VERSION "HNNBNNNYNNNNNNNNNNNNNNNNNNNNNNNNNNNNNNNNNN/4/%%%/4/'%**4NNN///"

NS_ :

BS_:

BU_: AWC BAP_Tester BMC_MLBevo BMS_MV BMS_NV CBC DCDC_800V_PAG DCDC_HV DCDC_HV_02 DCDC_IHEV FCU_MLBevo_FCEV Gateway Gateway_PAG Ladegeraet_2 Ladegeraet_Konzern LE1 LE2 LE_MLBevo Sub_Gateway TME

BO_ 2549874869 ISOx_FCU_Req: 8 Gateway
 SG_ ISOx_FCU_Req_Data : 0|64@1+ (1.0,0.0) [0.0|18446744073709551615] ""  FCU_MLBevo_FCEV

BO_ 2550005941 ISOx_FCU_Resp: 8 FCU_MLBevo_FCEV
 SG_ ISOx_FCU_Resp_Data : 0|64@1+ (1.0,0.0) [0.0|18446744073709551615] ""  Gateway

BO_ 2549874811 ISOx_Hybrid_01_Req: 8 Gateway
 SG_ ISOx_Hybrid_01_Req_Data : 0|64@1+ (1.0,0.0) [0.0|18446744073709551615] ""  BMC_MLBevo

BO_ 2550005883 ISOx_Hybrid_01_Resp: 8 BMC_MLBevo
 SG_ ISOx_Hybrid_01_Resp_Data : 0|64@1+ (1.0,0.0) [0.0|18446744073709551615] ""  Gateway,Gateway_PAG

BO_ 2549874886 ISOx_Ladegeraet_2_Req: 8 Gateway
 SG_ ISOx_Ladegeraet_2_Req_Data : 0|64@1+ (1,0) [0|18446744073709551615] "Unit_None"  Ladegeraet_2

BO_ 2550005958 ISOx_Ladegeraet_2_Resp: 8 Ladegeraet_2
 SG_ ISOx_Ladegeraet_2_Resp_Data : 0|64@1+ (1,0) [0|18446744073709551615] "Unit_None"  Gateway,Gateway_PAG

BO_ 2549874868 ISOx_TelemetrieSG_Req: 8 Gateway
 SG_ ISOx_TelemetrieSG_Req_Data : 0|64@1+ (1.0,0.0) [0.0|18446744073709551615] ""  Sub_Gateway

BO_ 2550005940 ISOx_TelemetrieSG_Resp: 8 Sub_Gateway
 SG_ ISOx_TelemetrieSG_Resp_Data : 0|64@1+ (1.0,0.0) [0.0|18446744073709551615] ""  Gateway,Gateway_PAG

BO_ 497 Kessy_11: 8 Gateway
 SG_ KY_IDG_in_Reichweite : 12|1@1+ (1.0,0.0) [0.0|1] ""  Vector__XXX
 SG_ KY_Auf_Taste : 13|1@1+ (1.0,0.0) [0.0|1] ""  FCU_MLBevo_FCEV,Ladegeraet_Konzern
 SG_ KY_HDF_Taste : 14|1@1+ (1.0,0.0) [0.0|1] ""  Vector__XXX
 SG_ KY_Panik_Taste : 15|1@1+ (1.0,0.0) [0.0|1] ""  Vector__XXX
 SG_ KY_Zu_Taste : 16|1@1+ (1.0,0.0) [0.0|1] ""  Ladegeraet_Konzern
 SG_ KY_FT_Entriegelung_Autorisiert : 17|1@1+ (1.0,0.0) [0.0|1] ""  FCU_MLBevo_FCEV
 SG_ KY_FT_Verriegelung_Autorisiert : 18|1@1+ (1.0,0.0) [0.0|1] ""  Vector__XXX
 SG_ KY_BT_Entriegelung_Autorisiert : 19|1@1+ (1.0,0.0) [0.0|1] ""  FCU_MLBevo_FCEV
 SG_ KY_BT_Verriegelung_Autorisiert : 20|1@1+ (1.0,0.0) [0.0|1] ""  Vector__XXX
 SG_ KY_HFS_Entriegelung_Autorisiert : 21|1@1+ (1.0,0.0) [0.0|1] ""  FCU_MLBevo_FCEV
 SG_ KY_HFS_Verriegelung_Autorisiert : 22|1@1+ (1.0,0.0) [0.0|1] ""  Vector__XXX
 SG_ KY_HBFS_Entriegelung_Autorisiert : 23|1@1+ (1.0,0.0) [0.0|1] ""  FCU_MLBevo_FCEV
 SG_ KY_HBFS_Verriegelung_Autorisiert : 24|1@1+ (1.0,0.0) [0.0|1] ""  Vector__XXX
 SG_ KY_Front_Entr_Autorisiert : 25|1@1+ (1.0,0.0) [0.0|1] ""  Vector__XXX
 SG_ KY_Front_Verr_Autorisiert : 26|1@1+ (1.0,0.0) [0.0|1] ""  Vector__XXX
 SG_ KY_HD_Entriegelung_Autorisiert : 27|1@1+ (1.0,0.0) [0.0|1] ""  FCU_MLBevo_FCEV
 SG_ KY_HD_Verriegelung_Autorisiert : 28|1@1+ (1.0,0.0) [0.0|1] ""  Vector__XXX
 SG_ KY_Bereich : 29|3@1+ (1.0,0.0) [0.0|7] ""  Vector__XXX
 SG_ KY_Position : 32|3@1+ (1.0,0.0) [0.0|7] ""  Vector__XXX
 SG_ KY_ZV_Signatur : 35|11@1+ (1,0) [0|2047] "Unit_None"  Vector__XXX
 SG_ Schluesselnr_Personalisierung : 46|4@1+ (1.0,0.0) [0.0|15] ""  Vector__XXX
 SG_ FFB_FDF_Taste : 50|1@1+ (1.0,0.0) [0.0|1] ""  Vector__XXX
 SG_ FFB_Joker_Taste : 51|1@1+ (1.0,0.0) [0.0|1] ""  Vector__XXX
 SG_ FFB_Park_Taste : 52|1@1+ (1.0,0.0) [0.0|1] ""  Vector__XXX
 SG_ FFB_Remotestart_Taste : 53|1@1+ (1.0,0.0) [0.0|1] ""  Vector__XXX
 SG_ FBS_Aktivierung_Pilot_Parken : 54|1@1+ (1.0,0.0) [0.0|1] ""  Vector__XXX
 SG_ KY_Schluessel_im_Fzg : 55|1@1+ (1.0,0.0) [0.0|1] ""  Vector__XXX
 SG_ KY_EasyClose_Abbruch : 56|1@1+ (1.0,0.0) [0.0|1] ""  Vector__XXX
 SG_ KY_EasyClose_Status : 57|3@1+ (1.0,0.0) [0.0|7] ""  Vector__XXX
 SG_ KY_HD_Auffahrt : 60|1@1+ (1.0,0.0) [0.0|1] ""  Vector__XXX
 SG_ KY_HD_Zufahrt : 61|1@1+ (1.0,0.0) [0.0|1] ""  Vector__XXX
 SG_ KY_LKL_1_Autorisierung : 62|1@1+ (1.0,0.0) [0.0|1] ""  Ladegeraet_Konzern
 SG_ KY_LKL_2_Autorisierung : 63|1@1+ (1.0,0.0) [0.0|1] ""  Ladegeraet_Konzern

BO_ 960 Klemmen_Status_01: 4 Gateway
 SG_ Klemmen_Status_01_CRC : 0|8@1+ (1,0) [0|255] ""  BMC_MLBevo,CBC,DCDC_HV_02,FCU_MLBevo_FCEV,Ladegeraet_2,Ladegeraet_Konzern
 SG_ Klemmen_Status_01_BZ : 8|4@1+ (1,0) [0|15] ""  BMC_MLBevo,CBC,DCDC_HV_02,FCU_MLBevo_FCEV,Ladegeraet_2,Ladegeraet_Konzern
 SG_ RSt_Fahrerhinweise : 12|4@1+ (1.0,0.0) [0.0|15] ""  FCU_MLBevo_FCEV
 SG_ ZAS_Kl_S : 16|1@1+ (1.0,0.0) [0.0|1] ""  FCU_MLBevo_FCEV,Ladegeraet_2,Ladegeraet_Konzern,TME
 SG_ ZAS_Kl_15 : 17|1@1+ (1.0,0.0) [0.0|1] ""  BMC_MLBevo,BMS_MV,BMS_NV,CBC,DCDC_800V_PAG,DCDC_HV,DCDC_HV_02,DCDC_IHEV,FCU_MLBevo_FCEV,Ladegeraet_2,Ladegeraet_Konzern,Sub_Gateway,TME
 SG_ ZAS_Kl_X : 18|1@1+ (1.0,0.0) [0.0|1] ""  FCU_MLBevo_FCEV
 SG_ ZAS_Kl_50_Startanforderung : 19|1@1+ (1.0,0.0) [0.0|1] ""  BMC_MLBevo,FCU_MLBevo_FCEV,Ladegeraet_2,Ladegeraet_Konzern,TME
 SG_ BCM_Remotestart_Betrieb : 20|1@1+ (1.0,0.0) [0.0|1] ""  FCU_MLBevo_FCEV
 SG_ ZAS_Kl_Infotainment : 21|1@1+ (1.0,0.0) [0.0|1] ""  FCU_MLBevo_FCEV
 SG_ BCM_Remotestart_KL15_Anf : 22|1@1+ (1.0,0.0) [0.0|1] ""  FCU_MLBevo_FCEV
 SG_ BCM_Remotestart_MO_Start : 23|1@1+ (1.0,0.0) [0.0|1] ""  FCU_MLBevo_FCEV
 SG_ KST_Warn_P1_ZST_def : 24|1@1+ (1.0,0.0) [0.0|1] ""  FCU_MLBevo_FCEV
 SG_ KST_Warn_P2_ZST_def : 25|1@1+ (1.0,0.0) [0.0|1] ""  FCU_MLBevo_FCEV
 SG_ KST_Fahrerhinweis_1 : 26|1@1+ (1.0,0.0) [0.0|1] ""  FCU_MLBevo_FCEV
 SG_ KST_Fahrerhinweis_2 : 27|1@1+ (1.0,0.0) [0.0|1] ""  FCU_MLBevo_FCEV
 SG_ BCM_Ausparken_Betrieb : 28|1@1+ (1.0,0.0) [0.0|1] ""  FCU_MLBevo_FCEV
 SG_ KST_Fahrerhinweis_4 : 29|1@1+ (1.0,0.0) [0.0|1] ""  FCU_MLBevo_FCEV
 SG_ KST_Fahrerhinweis_5 : 30|1@1+ (1.0,0.0) [0.0|1] ""  FCU_MLBevo_FCEV
 SG_ KST_Fahrerhinweis_6 : 31|1@1+ (1.0,0.0) [0.0|1] ""  FCU_MLBevo_FCEV

BO_ 1646 Klima_03: 8 Gateway
 SG_ KL_STL_aktiv : 0|1@1+ (1.0,0.0) [0.0|1] ""  Vector__XXX
 SG_ KL_STH_aktiv : 1|1@1+ (1.0,0.0) [0.0|1] ""  Vector__XXX
 SG_ KL_Solarluefter_aktiv : 2|1@1+ (1.0,0.0) [0.0|1] ""  Vector__XXX
 SG_ KL_Umluft_Taste : 3|1@1+ (1.0,0.0) [0.0|1] ""  TME
 SG_ KL_Geblaese_Fond_Status : 4|4@1+ (1.0,0.0) [0.0|15] ""  TME
 SG_ KL_STH_Ansteuerung : 8|2@1+ (1.0,0.0) [0.0|3] ""  Vector__XXX
 SG_ KL_STH_Betriebsdauer : 10|6@1+ (1,0) [0|60] "Unit_Minut"  Vector__XXX
 SG_ KL_Magnetventil : 16|1@1+ (1.0,0.0) [0.0|1] ""  Vector__XXX
 SG_ KL_WaPu : 17|1@1+ (1.0,0.0) [0.0|1] ""  Vector__XXX
 SG_ KL_Geblaese_Status : 18|4@1+ (1.0,0.0) [0.0|15] ""  TME
 SG_ KL_Restwaerme_aktiv : 22|1@1+ (1.0,0.0) [0.0|1] ""  Vector__XXX
 SG_ KL_Kompressorkupplung : 23|1@1+ (1.0,0.0) [0.0|1] ""  Vector__XXX
 SG_ KL_BCmE_Livetip_Freigabe : 24|1@1+ (1.0,0.0) [0.0|1] ""  TME
 SG_ KL_HYB_ASV_hinten_schliessen_Anf : 25|1@1+ (1.0,0.0) [0.0|1] ""  TME
 SG_ KL_HYB_ASV_vorne_schliessen_Anf : 26|1@1+ (1.0,0.0) [0.0|1] ""  TME
 SG_ KL_ErwVK_Zusatzrelais : 27|1@1+ (1.0,0.0) [0.0|1] ""  Vector__XXX
 SG_ KL_Status_Beduftung : 28|1@1+ (1.0,0.0) [0.0|1] ""  Vector__XXX
 SG_ KL_Status_Ionisator_Front : 29|1@1+ (1.0,0.0) [0.0|1] ""  Vector__XXX
 SG_ KL_STH_Timer_Status : 30|1@1+ (1.0,0.0) [0.0|1] ""  Vector__XXX
 SG_ KL_ErwVK_Anf : 31|1@1+ (1.0,0.0) [0.0|1] ""  TME
 SG_ KL_Innen_Temp : 32|8@1+ (0.5,-50) [-50.0|76.0] "Unit_DegreCelsi"  TME
 SG_ KL_I_Geblaese_Fond : 40|8@1+ (0.25,0) [0.00|63.50] "Unit_Amper"  Vector__XXX
 SG_ KL_Anf_AussenspiegelHzg : 48|1@1+ (1.0,0.0) [0.0|1] ""  Vector__XXX
 SG_ KL_Heizkreisventilstellung : 49|2@1+ (1.0,0.0) [0.0|3] ""  Vector__XXX
 SG_ KL_FSH_Automatikbetrieb : 51|1@1+ (1.0,0.0) [0.0|1] ""  Vector__XXX
 SG_ KL_SIH_LEH_Verteilung_VL : 52|3@1+ (1.0,0.0) [0.0|7] ""  Vector__XXX
 SG_ KL_SIH_LEL_Verteilung_VL : 55|3@1+ (1.0,0.0) [0.0|7] ""  Vector__XXX
 SG_ KL_SIH_LEH_Verteilung_VR : 58|3@1+ (1.0,0.0) [0.0|7] ""  Vector__XXX
 SG_ KL_SIH_LEL_Verteilung_VR : 61|3@1+ (1.0,0.0) [0.0|7] ""  Vector__XXX

BO_ 1649 Klima_06: 8 Gateway
 SG_ KL_ZZ_Minute : 0|6@1+ (1,0) [0|59] "Unit_Minut"  TME
 SG_ KL_ZZ_Status_Timer : 6|2@1+ (1.0,0.0) [0.0|3] ""  TME
 SG_ KL_ZZ_Monat : 8|4@1+ (1,0) [1|12] "Unit_Month"  TME
 SG_ KL_ZZ_Stunde : 16|5@1+ (1,0) [0|23] "Unit_Hours"  TME
 SG_ KL_ZZ_Betriebsmodus : 21|3@1+ (1.0,0.0) [0.0|7] ""  TME
 SG_ KL_ZZ_Tag : 24|5@1+ (1,0) [1|31] "Unit_Day"  TME
 SG_ KL_Betriebsmodus_FH : 29|3@1+ (1.0,0.0) [0.0|7] ""  Vector__XXX
 SG_ KL_Stopp_Wiederstart_Anz_01 : 32|1@1+ (1.0,0.0) [0.0|1] ""  Vector__XXX
 SG_ KL_Stopp_Wiederstart_Anz_02 : 33|1@1+ (1.0,0.0) [0.0|1] ""  Vector__XXX
 SG_ KL_Stopp_Wiederstart_Anz_03 : 34|1@1+ (1.0,0.0) [0.0|1] ""  Vector__XXX
 SG_ KL_Stopp_Wiederstart_Anz_04 : 35|1@1+ (1.0,0.0) [0.0|1] ""  Vector__XXX
 SG_ KL_Stopp_Wiederstart_Anz_05 : 36|1@1+ (1.0,0.0) [0.0|1] ""  Vector__XXX
 SG_ KL_Stopp_Wiederstart_Anz_06 : 37|1@1+ (1.0,0.0) [0.0|1] ""  Vector__XXX
 SG_ KL_Stopp_Wiederstart_Anz_07 : 38|1@1+ (1.0,0.0) [0.0|1] ""  Vector__XXX
 SG_ KL_Stopp_Wiederstart_Anz_08 : 39|1@1+ (1.0,0.0) [0.0|1] ""  Vector__XXX
 SG_ KL_Stopp_Wiederstart_Anz_09 : 40|1@1+ (1.0,0.0) [0.0|1] ""  Vector__XXX
 SG_ KL_Stopp_Wiederstart_Anz_Std1 : 41|1@1+ (1.0,0.0) [0.0|1] ""  Vector__XXX
 SG_ KL_Stopp_Wiederstart_Anz_Std2 : 42|1@1+ (1.0,0.0) [0.0|1] ""  Vector__XXX

BO_ 949 Klima_11: 8 Gateway
 SG_ KL_Drehz_Anh : 0|1@1+ (1.0,0.0) [0.0|1] ""  TME
 SG_ KL_Vorwarn_Komp_ein : 1|1@1+ (1.0,0.0) [0.0|1] ""  TME
 SG_ KL_AC_Schalter : 2|1@1+ (1.0,0.0) [0.0|1] ""  TME
 SG_ KL_Komp_Moment_alt : 3|1@1+ (1.0,0.0) [0.0|1] ""  TME
 SG_ KL_Vorwarn_Zuheizer_ein : 6|1@1+ (1.0,0.0) [0.0|1] ""  Vector__XXX
 SG_ KL_Zustand : 7|1@1+ (1.0,0.0) [0.0|1] ""  TME
 SG_ KL_Kompressorkupplung_linear : 8|8@1+ (20,0) [0|4000] "Unit_MilliAmper"  Vector__XXX
 SG_ KL_Charisma_FahrPr : 16|4@1+ (1.0,0.0) [0.0|15] ""  TME
 SG_ KL_Charisma_Status : 20|2@1+ (1.0,0.0) [0.0|3] ""  TME
 SG_ KL_nachtr_Stopp_Anf : 22|1@1+ (1.0,0.0) [0.0|1] ""  Vector__XXX
 SG_ KL_T_Charge : 23|1@1+ (1.0,0.0) [0.0|1] ""  Vector__XXX
 SG_ KL_Last_Kompr : 24|8@1+ (0.25,0) [0.00|63.50] "Unit_NewtoMeter"  TME
 SG_ KL_Spannungs_Anf : 32|2@1+ (1.0,0.0) [0.0|3] ""  Vector__XXX
 SG_ KL_Thermomanagement : 34|2@1+ (1.0,0.0) [0.0|3] ""  TME
 SG_ KL_StartStopp_Info : 36|2@1+ (1.0,0.0) [0.0|3] ""  TME
 SG_ KL_Freilauf_Info : 38|2@1+ (1.0,0.0) [0.0|3] ""  Vector__XXX
 SG_ KL_Anf_KL : 40|8@1+ (0.4,0) [0.0|101.6] "Unit_PerCent"  TME
 SG_ KL_el_Zuheizer_Stufe : 48|3@1+ (1.0,0.0) [0.0|7] ""  TME
 SG_ KL_Ausstattung_Klima : 51|3@1+ (1.0,0.0) [0.0|7] ""  Vector__XXX
 SG_ KL_Variante_Standheizung : 54|2@1+ (1.0,0.0) [0.0|3] ""  Vector__XXX

BO_ 1640 Klima_12: 8 Gateway
 SG_ KL_LRH_Taster : 0|1@1+ (1.0,0.0) [0.0|1] ""  Vector__XXX
 SG_ KL_LRH_Stufe : 1|2@1+ (1.0,0.0) [0.0|3] ""  Vector__XXX
 SG_ HSH_Taster : 3|2@1+ (1.0,0.0) [0.0|3] ""  Vector__XXX
 SG_ FSH_Taster : 5|1@1+ (1.0,0.0) [0.0|1] ""  Vector__XXX
 SG_ KL_Zuheizer_Freigabe : 6|1@1+ (1.0,0.0) [0.0|1] ""  TME
 SG_ KL_Beschlagsgefahr : 7|1@1+ (1.0,0.0) [0.0|1] ""  TME
 SG_ KL_SIH_Soll_li : 8|3@1+ (1,0) [0|6] ""  TME
 SG_ KL_SIH_Soll_re : 11|3@1+ (1,0) [0|6] ""  TME
 SG_ KRH_Soll_li : 14|2@1+ (1.0,0.0) [0.0|3] ""  Vector__XXX
 SG_ KL_SIL_Soll_li : 16|3@1+ (1,0) [0|6] ""  TME
 SG_ KL_SIL_Soll_re : 19|3@1+ (1,0) [0|6] ""  TME
 SG_ KRH_Soll_re : 22|2@1+ (1.0,0.0) [0.0|3] ""  Vector__XXX
 SG_ KL_Geblspng_Soll : 24|8@1+ (0.05,1.45) [1.50|14.00] "Unit_Volt"  Vector__XXX
 SG_ KL_Geblspng_Fond_Soll : 32|8@1+ (0.05,1.45) [1.50|14.00] "Unit_Volt"  Vector__XXX
 SG_ KL_I_Geblaese : 40|8@1+ (0.25,0) [0.00|63.50] "Unit_Amper"  Vector__XXX
 SG_ KL_Kompressorstrom_soll : 48|10@1+ (1,0) [0|1021] ""  TME
 SG_ KL_Umluftklappe_Status : 58|4@1+ (1.0,0.0) [0.0|15] ""  TME
 SG_ KL_PTC_Verbauinfo : 62|2@1+ (1.0,0.0) [0.0|3] ""  Vector__XXX

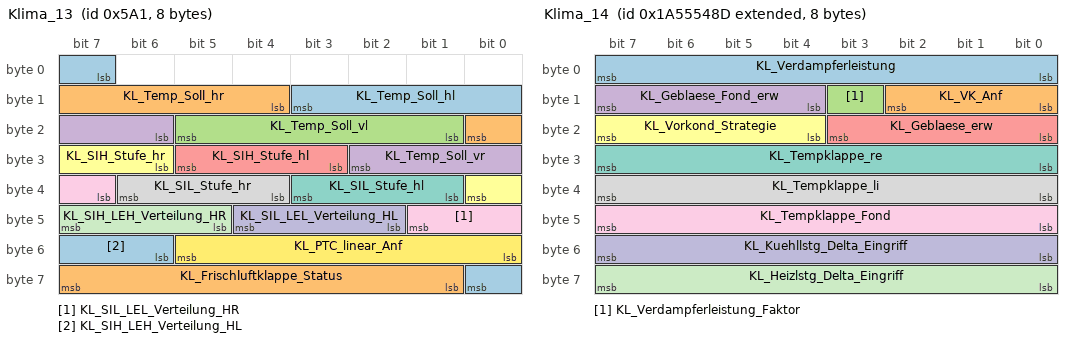
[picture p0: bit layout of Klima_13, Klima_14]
BO_ 1441 Klima_13: 8 Gateway
 SG_ KL_Temp_Soll_hl : 7|5@1+ (0.5,15.5) [15.5|30.0] "Unit_DegreCelsi"  TME
 SG_ KL_Temp_Soll_hr : 12|5@1+ (0.5,15.5) [15.5|30.0] "Unit_DegreCelsi"  TME
 SG_ KL_Temp_Soll_vl : 17|5@1+ (0.5,15.5) [15.5|30.0] "Unit_DegreCelsi"  TME
 SG_ KL_Temp_Soll_vr : 22|5@1+ (0.5,15.5) [15.5|30.0] "Unit_DegreCelsi"  TME
 SG_ KL_SIH_Stufe_hl : 27|3@1+ (1,0) [0|6] ""  Vector__XXX
 SG_ KL_SIH_Stufe_hr : 30|3@1+ (1,0) [0|6] ""  Vector__XXX
 SG_ KL_SIL_Stufe_hl : 33|3@1+ (1,0) [0|6] ""  Vector__XXX
 SG_ KL_SIL_Stufe_hr : 36|3@1+ (1,0) [0|6] ""  Vector__XXX
 SG_ KL_SIL_LEL_Verteilung_HR : 39|3@1+ (1.0,0.0) [0.0|7] ""  Vector__XXX
 SG_ KL_SIL_LEL_Verteilung_HL : 42|3@1+ (1.0,0.0) [0.0|7] ""  Vector__XXX
 SG_ KL_SIH_LEH_Verteilung_HR : 45|3@1+ (1.0,0.0) [0.0|7] ""  Vector__XXX
 SG_ KL_PTC_linear_Anf : 48|6@1+ (50,0) [0|3100] "Unit_Watt"  Vector__XXX
 SG_ KL_SIH_LEH_Verteilung_HL : 54|3@1+ (1.0,0.0) [0.0|7] ""  Vector__XXX
 SG_ KL_Frischluftklappe_Status : 57|7@1+ (1,0) [0|100] "Unit_PerCent"  TME

BO_ 2589283469 Klima_14: 8 Gateway
 SG_ KL_Verdampferleistung : 0|8@1+ (25,0) [0|6325] "Unit_Watt"  TME
 SG_ KL_VK_Anf : 8|3@1+ (1.0,0.0) [0.0|7] ""  Ladegeraet_Konzern,TME
 SG_ KL_Verdampferleistung_Faktor : 11|1@1+ (1.0,0.0) [0.0|1] ""  TME
 SG_ KL_Geblaese_Fond_erw : 12|4@1+ (1.0,0.0) [0.0|15] ""  Vector__XXX
 SG_ KL_Geblaese_erw : 16|4@1+ (1.0,0.0) [0.0|15] ""  Vector__XXX
 SG_ KL_Vorkond_Strategie : 20|4@1+ (1.0,0.0) [0.0|15] ""  TME
 SG_ KL_Tempklappe_re : 24|8@1+ (0.5,0) [0.0|100.0] "Unit_PerCent"  TME
 SG_ KL_Tempklappe_li : 32|8@1+ (0.5,0) [0.0|100.0] "Unit_PerCent"  TME
 SG_ KL_Tempklappe_Fond : 40|8@1+ (0.5,0) [0.0|100.0] "Unit_PerCent"  TME
 SG_ KL_Kuehllstg_Delta_Eingriff : 48|8@1+ (50,-6300) [-6300|6350] "Unit_Watt"  TME
 SG_ KL_Heizlstg_Delta_Eingriff : 56|8@1+ (50,-6300) [-6300|6350] "Unit_Watt"  TME

BO_ 2589283621 Klima_17: 8 Gateway
 SG_ KL_NV_Energie_Anf : 12|8@1+ (10,0) [0|2530] "Unit_WattHour"  Ladegeraet_Konzern,TME
 SG_ KL_FlHz_Soll_VL : 20|3@1+ (1,0) [0|6] "Unit_None"  Vector__XXX
 SG_ KL_FlHz_Soll_HL : 23|3@1+ (1,0) [0|6] "Unit_None"  Vector__XXX
 SG_ KL_FlHz_Soll_VR : 26|3@1+ (1,0) [0|6] "Unit_None"  Vector__XXX
 SG_ KL_FlHz_Soll_HR : 29|3@1+ (1,0) [0|6] "Unit_None"  Vector__XXX
 SG_ KL_Umluft_Connect_status : 32|3@1+ (1.0,0.0) [0.0|7] ""  Vector__XXX
 SG_ KL_ECO_PRO_Aktiv : 35|1@1+ (1.0,0.0) [0.0|1] ""  TME
 SG_ KL_QBit_Sonnenintensitaet : 36|1@1+ (1.0,0.0) [0.0|1] ""  TME
 SG_ KL_ZR_Anforderung : 37|2@1+ (1.0,0.0) [0.0|3] ""  Vector__XXX
 SG_ KL_ACmax_Aktiv : 39|1@1+ (1.0,0.0) [0.0|1] ""  TME
 SG_ KL_Defrost_Aktiv : 40|1@1+ (1.0,0.0) [0.0|1] ""  TME
 SG_ KL_ECO_Aktiv : 41|1@1+ (1.0,0.0) [0.0|1] ""  TME
 SG_ KL_Status_Klimastil : 42|2@1+ (1.0,0.0) [0.0|3] ""  TME
 SG_ KL_Kundeneingriff_Geblaese : 44|1@1+ (1.0,0.0) [0.0|1] ""  TME
 SG_ KL_Thermischer_Bedarf : 45|3@1+ (1.0,0.0) [0.0|7] ""  TME
 SG_ KL_Eps_Innen : 48|8@1+ (0.5,-50) [-50.0|50.0] "Unit_DegreCelsi"  TME
 SG_ KL_Sonnenintensitaet : 56|8@1+ (10,0) [0|1000] "Unit_WattPerMeterSquar"  TME

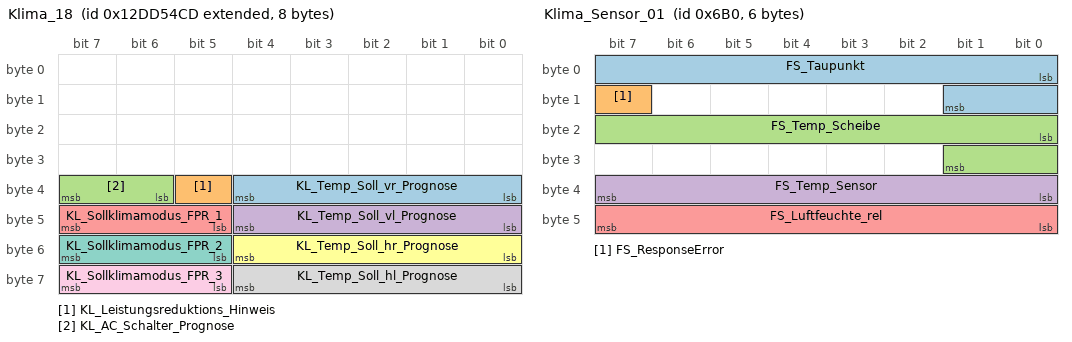
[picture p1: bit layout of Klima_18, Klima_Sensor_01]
BO_ 2463978701 Klima_18: 8 Gateway
 SG_ KL_Temp_Soll_vr_Prognose : 32|5@1+ (0.5,15.5) [15.5|30.0] "Unit_DegreCelsi"  TME
 SG_ KL_Leistungsreduktions_Hinweis : 37|1@1+ (1.0,0.0) [0.0|1] ""  Vector__XXX
 SG_ KL_AC_Schalter_Prognose : 38|2@1+ (1.0,0.0) [0.0|3] ""  TME
 SG_ KL_Temp_Soll_vl_Prognose : 40|5@1+ (0.5,15.5) [15.5|30.0] "Unit_DegreCelsi"  TME
 SG_ KL_Sollklimamodus_FPR_1 : 45|3@1+ (1.0,0.0) [0.0|7] ""  TME
 SG_ KL_Temp_Soll_hr_Prognose : 48|5@1+ (0.5,15.5) [15.5|30.0] "Unit_DegreCelsi"  TME
 SG_ KL_Sollklimamodus_FPR_2 : 53|3@1+ (1.0,0.0) [0.0|7] ""  TME
 SG_ KL_Temp_Soll_hl_Prognose : 56|5@1+ (0.5,15.5) [15.5|30.0] "Unit_DegreCelsi"  TME
 SG_ KL_Sollklimamodus_FPR_3 : 61|3@1+ (1.0,0.0) [0.0|7] ""  TME

BO_ 1712 Klima_Sensor_01: 6 Gateway
 SG_ FS_Taupunkt : 0|10@1+ (0.1,-39.6) [-39.5|60.4] "Unit_DegreCelsi"  TME
 SG_ FS_ResponseError : 15|1@1+ (1.0,0.0) [0.0|1] ""  Vector__XXX
 SG_ FS_Temp_Scheibe : 16|10@1+ (0.1,-39.6) [-39.5|60.4] "Unit_DegreCelsi"  TME
 SG_ FS_Temp_Sensor : 32|8@1+ (0.5,-40) [-39.5|87.0] "Unit_DegreCelsi"  TME
 SG_ FS_Luftfeuchte_rel : 40|8@1+ (0.5,-0.5) [0.0|100.0] "Unit_PerCent"  TME

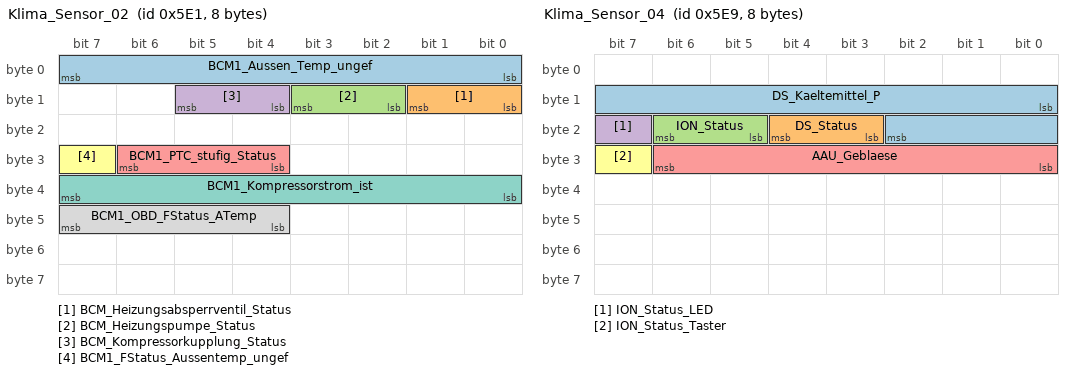
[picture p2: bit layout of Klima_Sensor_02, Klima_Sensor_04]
BO_ 1505 Klima_Sensor_02: 8 Gateway
 SG_ BCM1_Aussen_Temp_ungef : 0|8@1+ (0.5,-50) [-50.0|76.0] "Unit_DegreCelsi"  BMC_MLBevo,BMS_MV,BMS_NV,FCU_MLBevo_FCEV,Ladegeraet_Konzern,TME
 SG_ BCM_Heizungsabsperrventil_Status : 8|2@1+ (1.0,0.0) [0.0|3] ""  Vector__XXX
 SG_ BCM_Heizungspumpe_Status : 10|2@1+ (1.0,0.0) [0.0|3] ""  Vector__XXX
 SG_ BCM_Kompressorkupplung_Status : 12|2@1+ (1.0,0.0) [0.0|3] ""  Vector__XXX
 SG_ BCM1_PTC_stufig_Status : 28|3@1+ (1.0,0.0) [0.0|7] ""  Vector__XXX
 SG_ BCM1_FStatus_Aussentemp_ungef : 31|1@1+ (1.0,0.0) [0.0|1] ""  TME
 SG_ BCM1_Kompressorstrom_ist : 32|8@1+ (4,0) [0|1000] "Unit_MilliAmper"  Vector__XXX
 SG_ BCM1_OBD_FStatus_ATemp : 44|4@1+ (1.0,0.0) [0.0|15] ""  BMC_MLBevo,BMS_MV,Ladegeraet_Konzern,TME

BO_ 1717 Klima_Sensor_03: 8 Gateway
 SG_ FSA_Taupunkt : 0|10@1+ (0.1,-40) [-40.0|60.0] "Unit_DegreCelsi"  TME
 SG_ FSA_Err_Defekt_Tsens_TF : 10|1@1+ (1.0,0.0) [0.0|1] ""  Vector__XXX
 SG_ FSA_Luftfeuchte_TNCTOC : 11|1@1+ (1.0,0.0) [0.0|1] ""  Vector__XXX
 SG_ FSA_Luftfeuchte_TF : 12|1@1+ (1.0,0.0) [0.0|1] ""  Vector__XXX
 SG_ FSA_Err_Unterspannung_TF : 13|1@1+ (1.0,0.0) [0.0|1] ""  Vector__XXX
 SG_ FSA_Err_RAMROM_Check_TF : 14|1@1+ (1.0,0.0) [0.0|1] ""  Vector__XXX
 SG_ FSA_ResponseError : 15|1@1+ (1.0,0.0) [0.0|1] ""  Vector__XXX
 SG_ FSA_Temp_Luft : 16|10@1+ (0.1,-40) [-40.0|61.0] "Unit_DegreCelsi"  TME
 SG_ FSA_Err_RAMROM_Check_TNCTOC : 26|1@1+ (1.0,0.0) [0.0|1] ""  Vector__XXX
 SG_ FSA_Lokal_Bus_elektr_Fehler : 27|1@1+ (1.0,0.0) [0.0|1] ""  Vector__XXX
 SG_ FSA_Timeout : 28|1@1+ (1.0,0.0) [0.0|1] ""  Vector__XXX
 SG_ FSA_Lokal_Bus_Unterbrechung : 29|1@1+ (1.0,0.0) [0.0|1] ""  Vector__XXX
 SG_ FSA_Err_Ueberspannung_TF : 30|1@1+ (1.0,0.0) [0.0|1] ""  Vector__XXX
 SG_ FSA_Luftfeuchte_rel : 32|8@1+ (0.5,0) [0.0|126.0] "Unit_PerCent"  TME
 SG_ FSA_HW : 40|4@1+ (1,0) [0|15] ""  Vector__XXX
 SG_ FSA_SW : 44|4@1+ (1,0) [0|15] ""  Vector__XXX
 SG_ FSA_Temp_Sensor : 48|11@1+ (0.1,-40) [-40.0|90.0] "Unit_DegreCelsi"  TME
 SG_ FSA_Sensorheizung_Status : 59|1@1+ (1.0,0.0) [0.0|1] ""  TME
 SG_ FSA_Err_Defekt_HumSense_TF : 60|1@1+ (1.0,0.0) [0.0|1] ""  Vector__XXX
 SG_ FSA_Err_Defekt_HumSens_TNCTOC : 61|1@1+ (1.0,0.0) [0.0|1] ""  Vector__XXX
 SG_ FSA_ErrMemState : 62|2@1+ (1.0,0.0) [0.0|3] ""  Vector__XXX

BO_ 1513 Klima_Sensor_04: 8 Gateway
 SG_ DS_Kaeltemittel_P : 8|11@1+ (0.0161,0) [0.0000|32.9245] "Unit_Bar"  TME
 SG_ DS_Status : 19|2@1+ (1.0,0.0) [0.0|3] ""  TME
 SG_ ION_Status : 21|2@1+ (1.0,0.0) [0.0|3] ""  Vector__XXX
 SG_ ION_Status_LED : 23|1@1+ (1.0,0.0) [0.0|1] ""  Vector__XXX
 SG_ AAU_Geblaese : 24|7@1+ (1,0) [0|100] "Unit_PerCent"  Vector__XXX
 SG_ ION_Status_Taster : 31|1@1+ (1.0,0.0) [0.0|1] ""  Vector__XXX

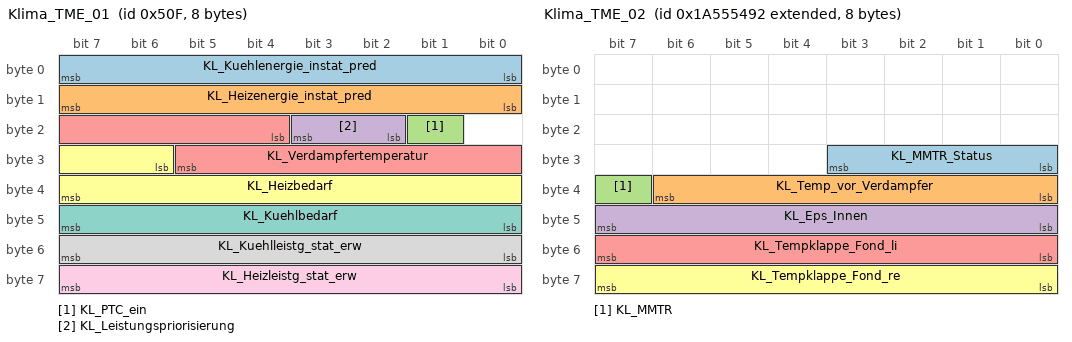
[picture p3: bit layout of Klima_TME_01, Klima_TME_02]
BO_ 1295 Klima_TME_01: 8 Gateway
 SG_ KL_Kuehlenergie_instat_pred : 0|8@1+ (25,0) [0|6325] "Unit_WattHour"  TME
 SG_ KL_Heizenergie_instat_pred : 8|8@1+ (25,0) [0|6325] "Unit_WattHour"  TME
 SG_ KL_PTC_ein : 17|1@1+ (1.0,0.0) [0.0|1] ""  Vector__XXX
 SG_ KL_Leistungspriorisierung : 18|2@1+ (1.0,0.0) [0.0|3] ""  TME
 SG_ KL_Verdampfertemperatur : 20|10@1+ (0.1,-20) [-20.0|70.0] "Unit_DegreCelsi"  TME
 SG_ KL_Heizbedarf : 30|10@1+ (0.1,0) [0.1|90.0] "Unit_DegreCelsi"  TME
 SG_ KL_Kuehlbedarf : 40|8@1+ (0.1,0) [0.0|25.0] "Unit_DegreCelsi"  TME
 SG_ KL_Kuehlleistg_stat_erw : 48|8@1+ (50,0) [0|12650] "Unit_Watt"  TME
 SG_ KL_Heizleistg_stat_erw : 56|8@1+ (50,0) [0|12650] "Unit_Watt"  TME

BO_ 2589283474 Klima_TME_02: 8 Gateway
 SG_ KL_MMTR_Status : 24|4@1+ (1.0,0.0) [0.0|15] ""  BMC_MLBevo,LE1,LE2
 SG_ KL_Temp_vor_Verdampfer : 32|7@1+ (1,-20) [-20|70] "Unit_DegreCelsi"  TME
 SG_ KL_MMTR : 39|1@1+ (1.0,0.0) [0.0|1] ""  BMC_MLBevo,TME
 SG_ KL_Eps_Innen : 40|8@1+ (0.5,-50) [-50.0|50.0] "Unit_DegreCelsi"  Vector__XXX
 SG_ KL_Tempklappe_Fond_li : 48|8@1+ (0.5,0) [0.0|100.0] "Unit_PerCent"  Vector__XXX
 SG_ KL_Tempklappe_Fond_re : 56|8@1+ (0.5,0) [0.0|100.0] "Unit_PerCent"  Vector__XXX

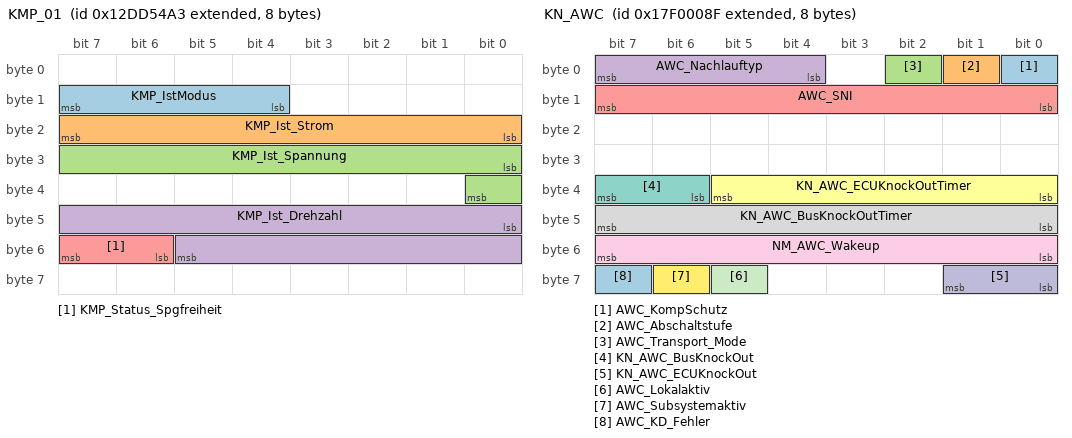
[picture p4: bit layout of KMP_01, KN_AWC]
BO_ 2463978659 KMP_01: 8 FCU_MLBevo_FCEV
 SG_ KMP_IstModus : 12|4@1+ (1.0,0.0) [0.0|15] ""  Vector__XXX
 SG_ KMP_Ist_Strom : 16|8@1+ (0.1,0) [0.0|25.5] "Unit_Amper"  Vector__XXX
 SG_ KMP_Ist_Spannung : 24|9@1+ (2,0) [0|1022] "Unit_Volt"  Gateway
 SG_ KMP_Ist_Drehzahl : 40|14@1+ (1,0) [0|16383] "Unit_RevPerMinute"  TME
 SG_ KMP_Status_Spgfreiheit : 54|2@1+ (1.0,0.0) [0.0|3] ""  Gateway

BO_ 2549088399 KN_AWC: 8 AWC
 SG_ AWC_KompSchutz : 0|1@1+ (1.0,0.0) [0.0|1] ""  Vector__XXX
 SG_ AWC_Abschaltstufe : 1|1@1+ (1.0,0.0) [0.0|1] ""  Vector__XXX
 SG_ AWC_Transport_Mode : 2|1@1+ (1.0,0.0) [0.0|1] ""  Vector__XXX
 SG_ AWC_Nachlauftyp : 4|4@1+ (1.0,0.0) [0.0|15] ""  Gateway
 SG_ AWC_SNI : 8|8@1+ (1.0,0.0) [0.0|255] ""  Gateway
 SG_ KN_AWC_ECUKnockOutTimer : 32|6@1+ (1,0) [0|62] "Unit_Minut"  Gateway
 SG_ KN_AWC_BusKnockOut : 38|2@1+ (1.0,0.0) [0.0|3] ""  Gateway
 SG_ KN_AWC_BusKnockOutTimer : 40|8@1+ (1,0) [0|254] ""  Gateway
 SG_ NM_AWC_Wakeup : 48|8@1+ (1.0,0.0) [0.0|255] ""  Vector__XXX
 SG_ KN_AWC_ECUKnockOut : 56|2@1+ (1.0,0.0) [0.0|3] ""  Gateway
 SG_ AWC_Lokalaktiv : 61|1@1+ (1.0,0.0) [0.0|1] ""  Gateway
 SG_ AWC_Subsystemaktiv : 62|1@1+ (1.0,0.0) [0.0|1] ""  Vector__XXX
 SG_ AWC_KD_Fehler : 63|1@1+ (1.0,0.0) [0.0|1] ""  Gateway

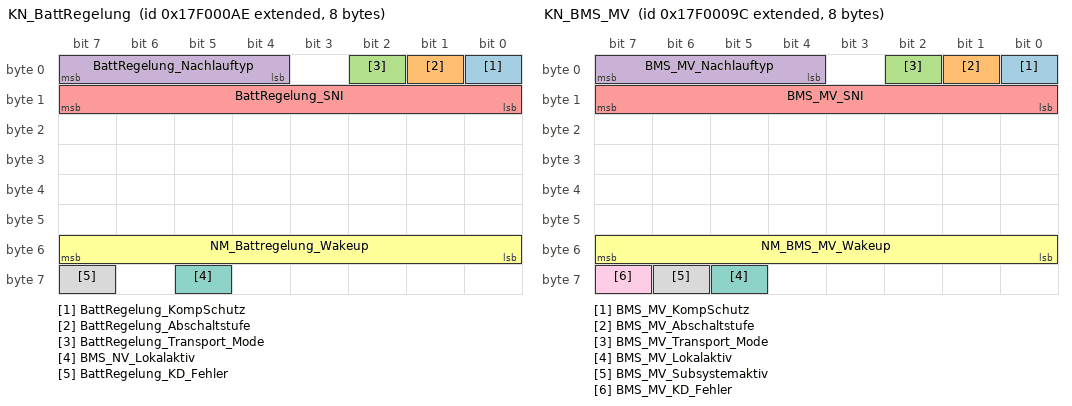
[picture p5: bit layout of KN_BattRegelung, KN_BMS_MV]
BO_ 2549088430 KN_BattRegelung: 8 BMS_NV
 SG_ BattRegelung_KompSchutz : 0|1@1+ (1.0,0.0) [0.0|1] ""  Vector__XXX
 SG_ BattRegelung_Abschaltstufe : 1|1@1+ (1.0,0.0) [0.0|1] ""  Vector__XXX
 SG_ BattRegelung_Transport_Mode : 2|1@1+ (1.0,0.0) [0.0|1] ""  Vector__XXX
 SG_ BattRegelung_Nachlauftyp : 4|4@1+ (1.0,0.0) [0.0|15] ""  Gateway,Gateway_PAG
 SG_ BattRegelung_SNI : 8|8@1+ (1.0,0.0) [0.0|255] ""  Gateway,Gateway_PAG
 SG_ NM_Battregelung_Wakeup : 48|8@1+ (1.0,0.0) [0.0|255] ""  Vector__XXX
 SG_ BMS_NV_Lokalaktiv : 61|1@1+ (1.0,0.0) [0.0|1] ""  Gateway,Gateway_PAG
 SG_ BattRegelung_KD_Fehler : 63|1@1+ (1.0,0.0) [0.0|1] ""  Gateway,Gateway_PAG

BO_ 2549088412 KN_BMS_MV: 8 BMS_MV
 SG_ BMS_MV_KompSchutz : 0|1@1+ (1.0,0.0) [0.0|1] ""  Vector__XXX
 SG_ BMS_MV_Abschaltstufe : 1|1@1+ (1.0,0.0) [0.0|1] ""  Vector__XXX
 SG_ BMS_MV_Transport_Mode : 2|1@1+ (1.0,0.0) [0.0|1] ""  Vector__XXX
 SG_ BMS_MV_Nachlauftyp : 4|4@1+ (1.0,0.0) [0.0|15] ""  Gateway,Gateway_PAG
 SG_ BMS_MV_SNI : 8|8@1+ (1.0,0.0) [0.0|255] ""  Gateway,Gateway_PAG
 SG_ NM_BMS_MV_Wakeup : 48|8@1+ (1.0,0.0) [0.0|255] ""  Vector__XXX
 SG_ BMS_MV_Lokalaktiv : 61|1@1+ (1.0,0.0) [0.0|1] ""  Gateway,Gateway_PAG
 SG_ BMS_MV_Subsystemaktiv : 62|1@1+ (1.0,0.0) [0.0|1] ""  Gateway,Gateway_PAG
 SG_ BMS_MV_KD_Fehler : 63|1@1+ (1.0,0.0) [0.0|1] ""  Gateway,Gateway_PAG

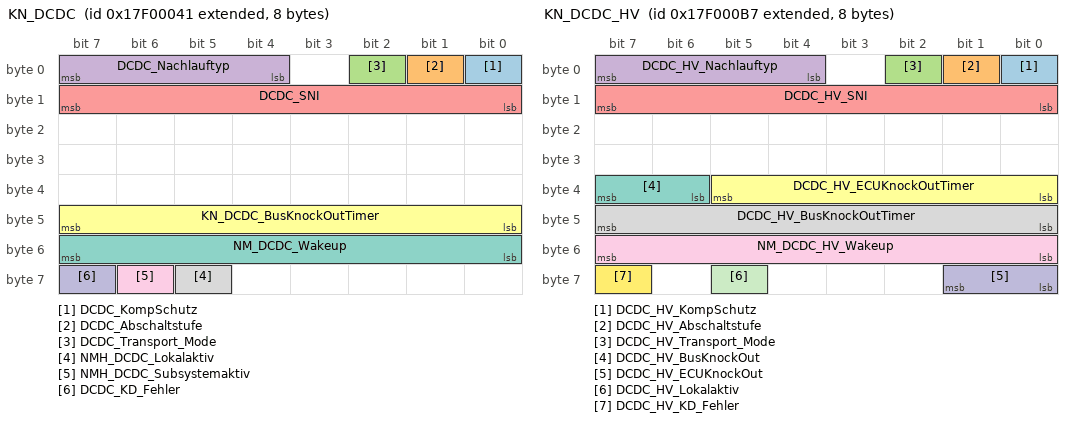
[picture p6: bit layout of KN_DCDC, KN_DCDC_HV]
BO_ 2549088321 KN_DCDC: 8 DCDC_IHEV
 SG_ DCDC_KompSchutz : 0|1@1+ (1.0,0.0) [0.0|1] ""  Vector__XXX
 SG_ DCDC_Abschaltstufe : 1|1@1+ (1.0,0.0) [0.0|1] ""  Vector__XXX
 SG_ DCDC_Transport_Mode : 2|1@1+ (1.0,0.0) [0.0|1] ""  Vector__XXX
 SG_ DCDC_Nachlauftyp : 4|4@1+ (1.0,0.0) [0.0|15] ""  Gateway,Gateway_PAG
 SG_ DCDC_SNI : 8|8@1+ (1.0,0.0) [0.0|255] ""  Gateway,Gateway_PAG
 SG_ KN_DCDC_BusKnockOutTimer : 40|8@1+ (1,0) [0|254] "Unit_None"  Gateway,Gateway_PAG
 SG_ NM_DCDC_Wakeup : 48|8@1+ (1.0,0.0) [0.0|255] ""  Vector__XXX
 SG_ NMH_DCDC_Lokalaktiv : 61|1@1+ (1.0,0.0) [0.0|1] ""  Gateway,Gateway_PAG
 SG_ NMH_DCDC_Subsystemaktiv : 62|1@1+ (1.0,0.0) [0.0|1] ""  Vector__XXX
 SG_ DCDC_KD_Fehler : 63|1@1+ (1.0,0.0) [0.0|1] ""  Gateway,Gateway_PAG

BO_ 2549088439 KN_DCDC_HV: 8 CBC
 SG_ DCDC_HV_KompSchutz : 0|1@1+ (1.0,0.0) [0.0|1] ""  Vector__XXX
 SG_ DCDC_HV_Abschaltstufe : 1|1@1+ (1.0,0.0) [0.0|1] ""  Vector__XXX
 SG_ DCDC_HV_Transport_Mode : 2|1@1+ (1.0,0.0) [0.0|1] ""  Vector__XXX
 SG_ DCDC_HV_Nachlauftyp : 4|4@1+ (1.0,0.0) [0.0|15] ""  Gateway,Gateway_PAG
 SG_ DCDC_HV_SNI : 8|8@1+ (1.0,0.0) [0.0|255] ""  Gateway,Gateway_PAG
 SG_ DCDC_HV_ECUKnockOutTimer : 32|6@1+ (1,0) [0|62] "Unit_Minut"  Gateway,Gateway_PAG
 SG_ DCDC_HV_BusKnockOut : 38|2@1+ (1.0,0.0) [0.0|3] ""  Gateway,Gateway_PAG
 SG_ DCDC_HV_BusKnockOutTimer : 40|8@1+ (1,0) [0|254] ""  Gateway,Gateway_PAG
 SG_ NM_DCDC_HV_Wakeup : 48|8@1+ (1.0,0.0) [0.0|255] ""  Vector__XXX
 SG_ DCDC_HV_ECUKnockOut : 56|2@1+ (1.0,0.0) [0.0|3] ""  Gateway,Gateway_PAG
 SG_ DCDC_HV_Lokalaktiv : 61|1@1+ (1.0,0.0) [0.0|1] ""  Gateway,Gateway_PAG
 SG_ DCDC_HV_KD_Fehler : 63|1@1+ (1.0,0.0) [0.0|1] ""  Gateway,Gateway_PAG

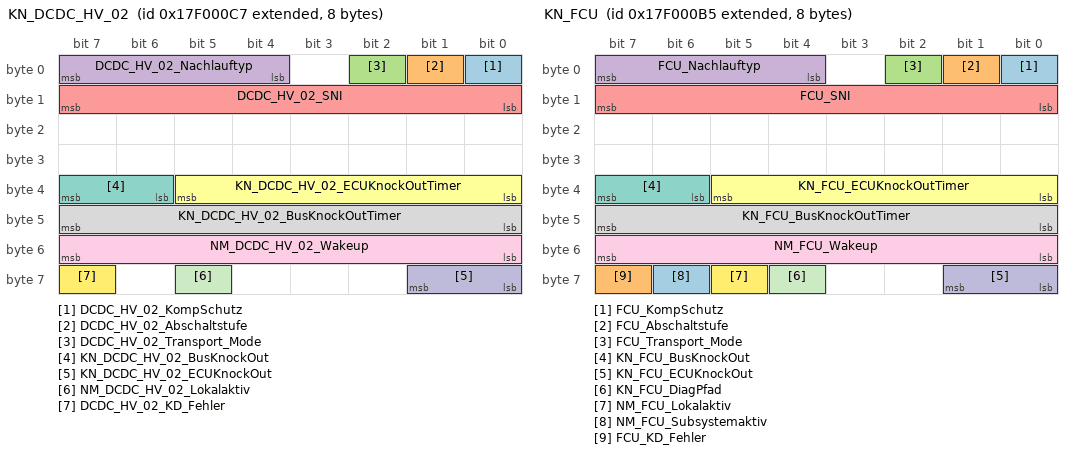
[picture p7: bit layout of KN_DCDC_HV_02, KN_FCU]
BO_ 2549088455 KN_DCDC_HV_02: 8 DCDC_HV_02
 SG_ DCDC_HV_02_KompSchutz : 0|1@1+ (1.0,0.0) [0.0|1] ""  Vector__XXX
 SG_ DCDC_HV_02_Abschaltstufe : 1|1@1+ (1.0,0.0) [0.0|1] ""  Vector__XXX
 SG_ DCDC_HV_02_Transport_Mode : 2|1@1+ (1.0,0.0) [0.0|1] ""  Vector__XXX
 SG_ DCDC_HV_02_Nachlauftyp : 4|4@1+ (1.0,0.0) [0.0|15] ""  Gateway,Gateway_PAG
 SG_ DCDC_HV_02_SNI : 8|8@1+ (1.0,0.0) [0.0|255] ""  Gateway,Gateway_PAG
 SG_ KN_DCDC_HV_02_ECUKnockOutTimer : 32|6@1+ (1,0) [0|62] "Unit_Minut"  Gateway,Gateway_PAG
 SG_ KN_DCDC_HV_02_BusKnockOut : 38|2@1+ (1.0,0.0) [0.0|3] ""  Gateway,Gateway_PAG
 SG_ KN_DCDC_HV_02_BusKnockOutTimer : 40|8@1+ (1,0) [0|254] ""  Gateway,Gateway_PAG
 SG_ NM_DCDC_HV_02_Wakeup : 48|8@1+ (1.0,0.0) [0.0|255] ""  Vector__XXX
 SG_ KN_DCDC_HV_02_ECUKnockOut : 56|2@1+ (1.0,0.0) [0.0|3] ""  Gateway,Gateway_PAG
 SG_ NM_DCDC_HV_02_Lokalaktiv : 61|1@1+ (1.0,0.0) [0.0|1] ""  Gateway,Gateway_PAG
 SG_ DCDC_HV_02_KD_Fehler : 63|1@1+ (1.0,0.0) [0.0|1] ""  Gateway,Gateway_PAG

BO_ 2549088437 KN_FCU: 8 FCU_MLBevo_FCEV
 SG_ FCU_KompSchutz : 0|1@1+ (1.0,0.0) [0.0|1] ""  Vector__XXX
 SG_ FCU_Abschaltstufe : 1|1@1+ (1.0,0.0) [0.0|1] ""  Vector__XXX
 SG_ FCU_Transport_Mode : 2|1@1+ (1.0,0.0) [0.0|1] ""  Vector__XXX
 SG_ FCU_Nachlauftyp : 4|4@1+ (1.0,0.0) [0.0|15] ""  Gateway
 SG_ FCU_SNI : 8|8@1+ (1.0,0.0) [0.0|255] ""  Gateway
 SG_ KN_FCU_ECUKnockOutTimer : 32|6@1+ (1,0) [0|62] "Unit_Minut"  Gateway
 SG_ KN_FCU_BusKnockOut : 38|2@1+ (1.0,0.0) [0.0|3] ""  Gateway
 SG_ KN_FCU_BusKnockOutTimer : 40|8@1+ (1,0) [0|254] ""  Gateway
 SG_ NM_FCU_Wakeup : 48|8@1+ (1.0,0.0) [0.0|255] ""  Vector__XXX
 SG_ KN_FCU_ECUKnockOut : 56|2@1+ (1.0,0.0) [0.0|3] ""  Gateway
 SG_ KN_FCU_DiagPfad : 60|1@1+ (1.0,0.0) [0.0|1] ""  Vector__XXX
 SG_ NM_FCU_Lokalaktiv : 61|1@1+ (1.0,0.0) [0.0|1] ""  Gateway
 SG_ NM_FCU_Subsystemaktiv : 62|1@1+ (1.0,0.0) [0.0|1] ""  Gateway
 SG_ FCU_KD_Fehler : 63|1@1+ (1.0,0.0) [0.0|1] ""  Gateway

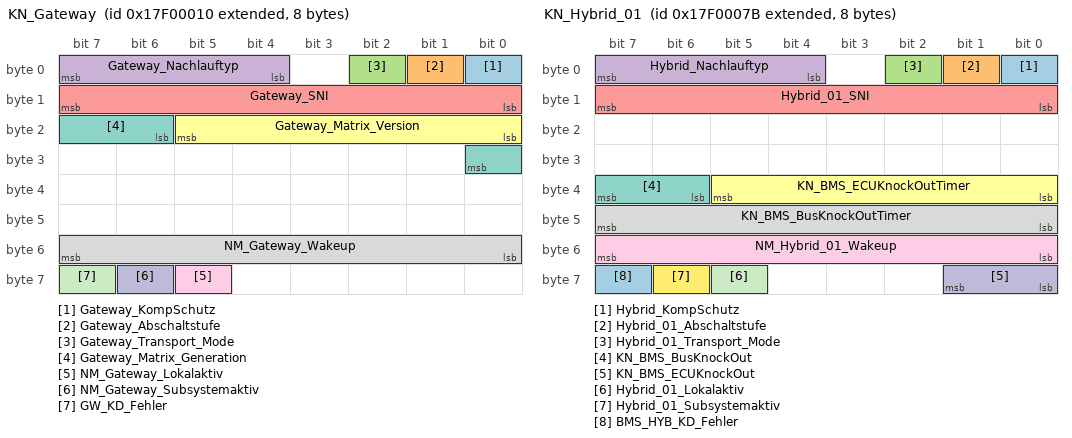
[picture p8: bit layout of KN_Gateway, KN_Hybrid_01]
BO_ 2549088272 KN_Gateway: 8 Gateway
 SG_ Gateway_KompSchutz : 0|1@1+ (1.0,0.0) [0.0|1] ""  Vector__XXX
 SG_ Gateway_Abschaltstufe : 1|1@1+ (1.0,0.0) [0.0|1] ""  Vector__XXX
 SG_ Gateway_Transport_Mode : 2|1@1+ (1.0,0.0) [0.0|1] ""  Vector__XXX
 SG_ Gateway_Nachlauftyp : 4|4@1+ (1.0,0.0) [0.0|15] ""  Vector__XXX
 SG_ Gateway_SNI : 8|8@1+ (1.0,0.0) [0.0|255] ""  Vector__XXX
 SG_ Gateway_Matrix_Version : 16|6@1+ (1,0) [0|63] "Unit_None"  Vector__XXX
 SG_ Gateway_Matrix_Generation : 22|3@1+ (1,0) [0|7] "Unit_None"  Vector__XXX
 SG_ NM_Gateway_Wakeup : 48|8@1+ (1.0,0.0) [0.0|255] ""  Vector__XXX
 SG_ NM_Gateway_Lokalaktiv : 61|1@1+ (1.0,0.0) [0.0|1] ""  Vector__XXX
 SG_ NM_Gateway_Subsystemaktiv : 62|1@1+ (1.0,0.0) [0.0|1] ""  Vector__XXX
 SG_ GW_KD_Fehler : 63|1@1+ (1.0,0.0) [0.0|1] ""  Vector__XXX

BO_ 2549088379 KN_Hybrid_01: 8 BMC_MLBevo
 SG_ Hybrid_KompSchutz : 0|1@1+ (1.0,0.0) [0.0|1] ""  Vector__XXX
 SG_ Hybrid_01_Abschaltstufe : 1|1@1+ (1.0,0.0) [0.0|1] ""  Vector__XXX
 SG_ Hybrid_01_Transport_Mode : 2|1@1+ (1.0,0.0) [0.0|1] ""  Vector__XXX
 SG_ Hybrid_Nachlauftyp : 4|4@1+ (1.0,0.0) [0.0|15] ""  Gateway,Gateway_PAG
 SG_ Hybrid_01_SNI : 8|8@1+ (1.0,0.0) [0.0|255] ""  Gateway,Gateway_PAG
 SG_ KN_BMS_ECUKnockOutTimer : 32|6@1+ (1,0) [0|62] "Unit_Minut"  Vector__XXX
 SG_ KN_BMS_BusKnockOut : 38|2@1+ (1.0,0.0) [0.0|3] ""  Vector__XXX
 SG_ KN_BMS_BusKnockOutTimer : 40|8@1+ (1,0) [0|254] ""  Gateway,Gateway_PAG
 SG_ NM_Hybrid_01_Wakeup : 48|8@1+ (1.0,0.0) [0.0|255] ""  Vector__XXX
 SG_ KN_BMS_ECUKnockOut : 56|2@1+ (1.0,0.0) [0.0|3] ""  Vector__XXX
 SG_ Hybrid_01_Lokalaktiv : 61|1@1+ (1.0,0.0) [0.0|1] ""  Gateway,Gateway_PAG
 SG_ Hybrid_01_Subsystemaktiv : 62|1@1+ (1.0,0.0) [0.0|1] ""  Gateway,Gateway_PAG
 SG_ BMS_HYB_KD_Fehler : 63|1@1+ (1.0,0.0) [0.0|1] ""  Gateway,Gateway_PAG

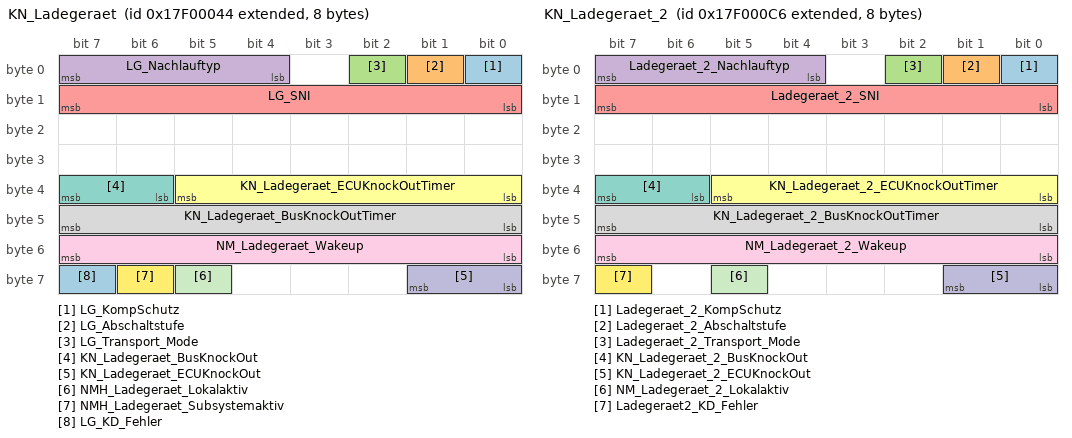
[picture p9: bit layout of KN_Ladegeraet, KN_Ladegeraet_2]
BO_ 2549088324 KN_Ladegeraet: 8 Ladegeraet_Konzern
 SG_ LG_KompSchutz : 0|1@1+ (1.0,0.0) [0.0|1] ""  Vector__XXX
 SG_ LG_Abschaltstufe : 1|1@1+ (1.0,0.0) [0.0|1] ""  Vector__XXX
 SG_ LG_Transport_Mode : 2|1@1+ (1.0,0.0) [0.0|1] ""  Vector__XXX
 SG_ LG_Nachlauftyp : 4|4@1+ (1.0,0.0) [0.0|15] ""  Gateway,Gateway_PAG
 SG_ LG_SNI : 8|8@1+ (1.0,0.0) [0.0|255] ""  Gateway,Gateway_PAG
 SG_ KN_Ladegeraet_ECUKnockOutTimer : 32|6@1+ (1,0) [0|62] "Unit_Minut"  Gateway
 SG_ KN_Ladegeraet_BusKnockOut : 38|2@1+ (1.0,0.0) [0.0|3] ""  Gateway
 SG_ KN_Ladegeraet_BusKnockOutTimer : 40|8@1+ (1,0) [0|254] ""  Gateway,Gateway_PAG
 SG_ NM_Ladegeraet_Wakeup : 48|8@1+ (1.0,0.0) [0.0|255] ""  Vector__XXX
 SG_ KN_Ladegeraet_ECUKnockOut : 56|2@1+ (1.0,0.0) [0.0|3] ""  Gateway
 SG_ NMH_Ladegeraet_Lokalaktiv : 61|1@1+ (1.0,0.0) [0.0|1] ""  Gateway,Gateway_PAG
 SG_ NMH_Ladegeraet_Subsystemaktiv : 62|1@1+ (1.0,0.0) [0.0|1] ""  Vector__XXX
 SG_ LG_KD_Fehler : 63|1@1+ (1.0,0.0) [0.0|1] ""  Gateway,Gateway_PAG

BO_ 2549088454 KN_Ladegeraet_2: 8 Ladegeraet_2
 SG_ Ladegeraet_2_KompSchutz : 0|1@1+ (1.0,0.0) [0.0|1] ""  Vector__XXX
 SG_ Ladegeraet_2_Abschaltstufe : 1|1@1+ (1.0,0.0) [0.0|1] ""  Vector__XXX
 SG_ Ladegeraet_2_Transport_Mode : 2|1@1+ (1.0,0.0) [0.0|1] ""  Vector__XXX
 SG_ Ladegeraet_2_Nachlauftyp : 4|4@1+ (1.0,0.0) [0.0|15] ""  Gateway,Gateway_PAG
 SG_ Ladegeraet_2_SNI : 8|8@1+ (1.0,0.0) [0.0|255] ""  Gateway,Gateway_PAG
 SG_ KN_Ladegeraet_2_ECUKnockOutTimer : 32|6@1+ (1,0) [0|62] "Unit_Minut"  Vector__XXX
 SG_ KN_Ladegeraet_2_BusKnockOut : 38|2@1+ (1.0,0.0) [0.0|3] ""  Vector__XXX
 SG_ KN_Ladegeraet_2_BusKnockOutTimer : 40|8@1+ (1,0) [0|254] ""  Gateway
 SG_ NM_Ladegeraet_2_Wakeup : 48|8@1+ (1.0,0.0) [0.0|255] ""  Vector__XXX
 SG_ KN_Ladegeraet_2_ECUKnockOut : 56|2@1+ (1.0,0.0) [0.0|3] ""  Vector__XXX
 SG_ NM_Ladegeraet_2_Lokalaktiv : 61|1@1+ (1.0,0.0) [0.0|1] ""  Gateway,Gateway_PAG
 SG_ Ladegeraet2_KD_Fehler : 63|1@1+ (1.0,0.0) [0.0|1] ""  Gateway,Gateway_PAG

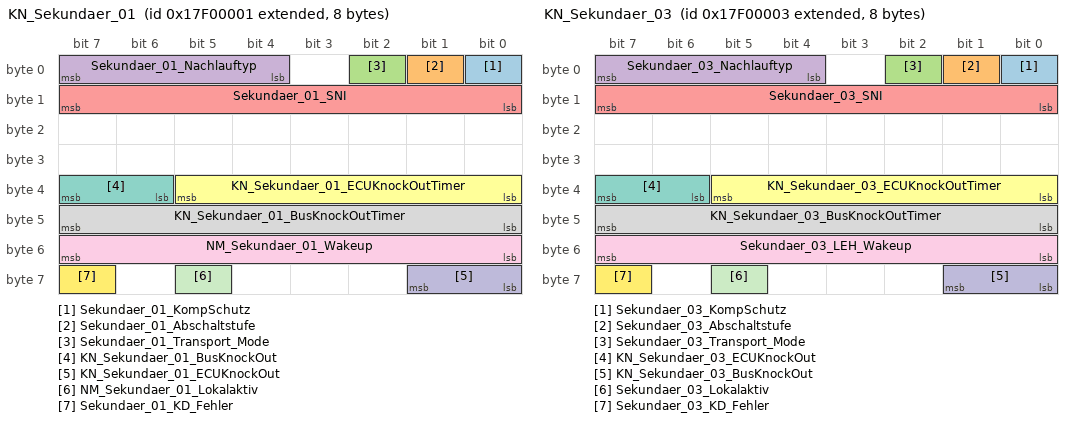
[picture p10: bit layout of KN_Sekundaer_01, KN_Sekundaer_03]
BO_ 2549088257 KN_Sekundaer_01: 8 LE2
 SG_ Sekundaer_01_KompSchutz : 0|1@1+ (1.0,0.0) [0.0|1] ""  Vector__XXX
 SG_ Sekundaer_01_Abschaltstufe : 1|1@1+ (1.0,0.0) [0.0|1] ""  Vector__XXX
 SG_ Sekundaer_01_Transport_Mode : 2|1@1+ (1.0,0.0) [0.0|1] ""  Vector__XXX
 SG_ Sekundaer_01_Nachlauftyp : 4|4@1+ (1.0,0.0) [0.0|15] ""  Gateway,Gateway_PAG
 SG_ Sekundaer_01_SNI : 8|8@1+ (1.0,0.0) [0.0|255] ""  Gateway,Gateway_PAG
 SG_ KN_Sekundaer_01_ECUKnockOutTimer : 32|6@1+ (1,0) [0|62] "Unit_Minut"  Gateway,Gateway_PAG
 SG_ KN_Sekundaer_01_BusKnockOut : 38|2@1+ (1.0,0.0) [0.0|3] ""  Gateway,Gateway_PAG
 SG_ KN_Sekundaer_01_BusKnockOutTimer : 40|8@1+ (1,0) [0|254] ""  Gateway,Gateway_PAG
 SG_ NM_Sekundaer_01_Wakeup : 48|8@1+ (1.0,0.0) [0.0|255] ""  Vector__XXX
 SG_ KN_Sekundaer_01_ECUKnockOut : 56|2@1+ (1.0,0.0) [0.0|3] ""  Gateway,Gateway_PAG
 SG_ NM_Sekundaer_01_Lokalaktiv : 61|1@1+ (1.0,0.0) [0.0|1] ""  Gateway
 SG_ Sekundaer_01_KD_Fehler : 63|1@1+ (1.0,0.0) [0.0|1] ""  Gateway,Gateway_PAG

BO_ 2549088259 KN_Sekundaer_03: 8 LE1
 SG_ Sekundaer_03_KompSchutz : 0|1@1+ (1.0,0.0) [0.0|1] ""  Vector__XXX
 SG_ Sekundaer_03_Abschaltstufe : 1|1@1+ (1.0,0.0) [0.0|1] ""  Vector__XXX
 SG_ Sekundaer_03_Transport_Mode : 2|1@1+ (1.0,0.0) [0.0|1] ""  Vector__XXX
 SG_ Sekundaer_03_Nachlauftyp : 4|4@1+ (1.0,0.0) [0.0|15] ""  Gateway,Gateway_PAG
 SG_ Sekundaer_03_SNI : 8|8@1+ (1.0,0.0) [0.0|255] ""  Gateway,Gateway_PAG
 SG_ KN_Sekundaer_03_ECUKnockOutTimer : 32|6@1+ (1,0) [0|62] "Unit_Minut"  Gateway,Gateway_PAG
 SG_ KN_Sekundaer_03_ECUKnockOut : 38|2@1+ (1.0,0.0) [0.0|3] ""  Gateway,Gateway_PAG
 SG_ KN_Sekundaer_03_BusKnockOutTimer : 40|8@1+ (1,0) [0|254] ""  Gateway,Gateway_PAG
 SG_ Sekundaer_03_LEH_Wakeup : 48|8@1+ (1.0,0.0) [0.0|255] ""  Vector__XXX
 SG_ KN_Sekundaer_03_BusKnockOut : 56|2@1+ (1.0,0.0) [0.0|3] ""  Gateway,Gateway_PAG
 SG_ Sekundaer_03_Lokalaktiv : 61|1@1+ (1.0,0.0) [0.0|1] ""  Gateway
 SG_ Sekundaer_03_KD_Fehler : 63|1@1+ (1.0,0.0) [0.0|1] ""  Gateway,Gateway_PAG

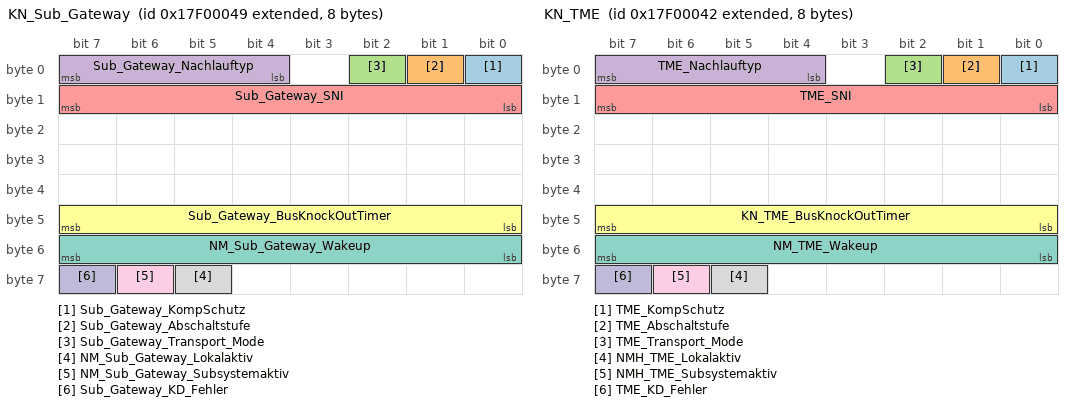
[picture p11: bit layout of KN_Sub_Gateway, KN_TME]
BO_ 2549088329 KN_Sub_Gateway: 8 Sub_Gateway
 SG_ Sub_Gateway_KompSchutz : 0|1@1+ (1.0,0.0) [0.0|1] ""  Vector__XXX
 SG_ Sub_Gateway_Abschaltstufe : 1|1@1+ (1.0,0.0) [0.0|1] ""  Vector__XXX
 SG_ Sub_Gateway_Transport_Mode : 2|1@1+ (1.0,0.0) [0.0|1] ""  Vector__XXX
 SG_ Sub_Gateway_Nachlauftyp : 4|4@1+ (1.0,0.0) [0.0|15] ""  Gateway,Gateway_PAG
 SG_ Sub_Gateway_SNI : 8|8@1+ (1.0,0.0) [0.0|255] ""  Gateway,Gateway_PAG
 SG_ Sub_Gateway_BusKnockOutTimer : 40|8@1+ (1,0) [0|254] ""  Vector__XXX
 SG_ NM_Sub_Gateway_Wakeup : 48|8@1+ (1.0,0.0) [0.0|255] ""  Vector__XXX
 SG_ NM_Sub_Gateway_Lokalaktiv : 61|1@1+ (1.0,0.0) [0.0|1] ""  Gateway
 SG_ NM_Sub_Gateway_Subsystemaktiv : 62|1@1+ (1.0,0.0) [0.0|1] ""  Gateway
 SG_ Sub_Gateway_KD_Fehler : 63|1@1+ (1.0,0.0) [0.0|1] ""  Gateway,Gateway_PAG

BO_ 2549088322 KN_TME: 8 TME
 SG_ TME_KompSchutz : 0|1@1+ (1.0,0.0) [0.0|1] ""  Vector__XXX
 SG_ TME_Abschaltstufe : 1|1@1+ (1.0,0.0) [0.0|1] ""  Vector__XXX
 SG_ TME_Transport_Mode : 2|1@1+ (1.0,0.0) [0.0|1] ""  Vector__XXX
 SG_ TME_Nachlauftyp : 4|4@1+ (1.0,0.0) [0.0|15] ""  Gateway,Gateway_PAG
 SG_ TME_SNI : 8|8@1+ (1.0,0.0) [0.0|255] ""  Gateway,Gateway_PAG
 SG_ KN_TME_BusKnockOutTimer : 40|8@1+ (1,0) [0|254] "Unit_Minut"  Gateway,Gateway_PAG
 SG_ NM_TME_Wakeup : 48|8@1+ (1.0,0.0) [0.0|255] ""  Vector__XXX
 SG_ NMH_TME_Lokalaktiv : 61|1@1+ (1.0,0.0) [0.0|1] ""  Gateway,Gateway_PAG
 SG_ NMH_TME_Subsystemaktiv : 62|1@1+ (1.0,0.0) [0.0|1] ""  Gateway,Gateway_PAG
 SG_ TME_KD_Fehler : 63|1@1+ (1.0,0.0) [0.0|1] ""  Gateway,Gateway_PAG

BO_ 779 Kombi_01: 8 Gateway
 SG_ KBI_ABS_Lampe : 0|1@1+ (1.0,0.0) [0.0|1] ""  Vector__XXX
 SG_ KBI_ESP_Lampe : 1|1@1+ (1.0,0.0) [0.0|1] ""  Vector__XXX
 SG_ KBI_BKL_Lampe : 2|1@1+ (1.0,0.0) [0.0|1] ""  Vector__XXX
 SG_ KBI_Airbag_Lampe : 3|1@1+ (1.0,0.0) [0.0|1] ""  Vector__XXX
 SG_ KBI_SILA_gueltig : 4|1@1+ (1.0,0.0) [0.0|1] ""  Vector__XXX
 SG_ KBI_Lenkung_Lampe : 5|1@1+ (1,0) [0|1] ""  Vector__XXX
 SG_ KBI_Vorglueh_System_Lampe : 6|1@1+ (1.0,0.0) [0.0|1] ""  Vector__XXX
 SG_ KBI_NV_in_Anzeige : 7|1@1+ (1.0,0.0) [0.0|1] ""  Vector__XXX
 SG_ Kombi_01_BZ : 8|4@1+ (1,0) [0|15] ""  Vector__XXX
 SG_ KBI_Anzeigestatus_ACC : 12|1@1+ (1.0,0.0) [0.0|1] ""  Vector__XXX
 SG_ KBI_Anzeigestatus_GRA : 13|2@1+ (1.0,0.0) [0.0|3] ""  Vector__XXX
 SG_ KBI_Tankwarnung : 16|1@1+ (1.0,0.0) [0.0|1] ""  TME
 SG_ KBI_MFA_v_Einheit_01 : 17|1@1+ (1.0,0.0) [0.0|1] ""  Vector__XXX
 SG_ KBI_im_Stellgliedtest : 18|1@1+ (1.0,0.0) [0.0|1] ""  Vector__XXX
 SG_ KBI_Anzeigefehler_LDW : 19|2@1+ (1.0,0.0) [0.0|3] ""  Vector__XXX
 SG_ KBI_Tankwarnung_ungueltig : 21|1@1+ (1.0,0.0) [0.0|1] ""  Vector__XXX
 SG_ KBI_Handbremse : 23|1@1+ (1.0,0.0) [0.0|1] ""  Vector__XXX
 SG_ KBI_V_Digital : 24|9@1+ (1,0) [0|511] ""  Vector__XXX
 SG_ KBI_PLA_in_Anzeige : 33|1@1+ (1.0,0.0) [0.0|1] ""  Vector__XXX
 SG_ KBI_Anzeigefehler_NV : 34|1@1+ (1.0,0.0) [0.0|1] ""  Vector__XXX
 SG_ KBI_Anzeigestatus_LIM : 35|2@1+ (1.0,0.0) [0.0|3] ""  Vector__XXX
 SG_ KBI_ARA_in_Anzeige : 37|1@1+ (1.0,0.0) [0.0|1] ""  Vector__XXX
 SG_ KBI_Taster_Lift : 38|1@1+ (1.0,0.0) [0.0|1] ""  Vector__XXX
 SG_ KBI_Taster_Fahrwerk : 39|1@1+ (1.0,0.0) [0.0|1] ""  Vector__XXX
 SG_ KBI_GRA_Hauptschalter : 40|2@1+ (1.0,0.0) [0.0|3] ""  Vector__XXX
 SG_ KBI_Bestaetigung_ESP_Off : 42|2@1+ (1.0,0.0) [0.0|3] ""  Vector__XXX
 SG_ KBI_angez_Geschw : 48|10@1+ (0.32,0) [0.00|325.12] "Unit_KiloMeterPerHour"  Vector__XXX
 SG_ KBI_Einheit_Tacho : 58|1@1+ (1.0,0.0) [0.0|1] ""  Vector__XXX
 SG_ KBI_Konsistenz_ACC : 59|1@1+ (1.0,0.0) [0.0|1] ""  Vector__XXX
 SG_ KBI_Fehler_Anzeige_ACC : 60|1@1+ (1.0,0.0) [0.0|1] ""  Vector__XXX
 SG_ KBI_Anzeigefehler_SWA : 61|2@1+ (1.0,0.0) [0.0|3] ""  Vector__XXX
 SG_ KBI_Systemstatus : 63|1@1+ (1.0,0.0) [0.0|1] ""  Vector__XXX

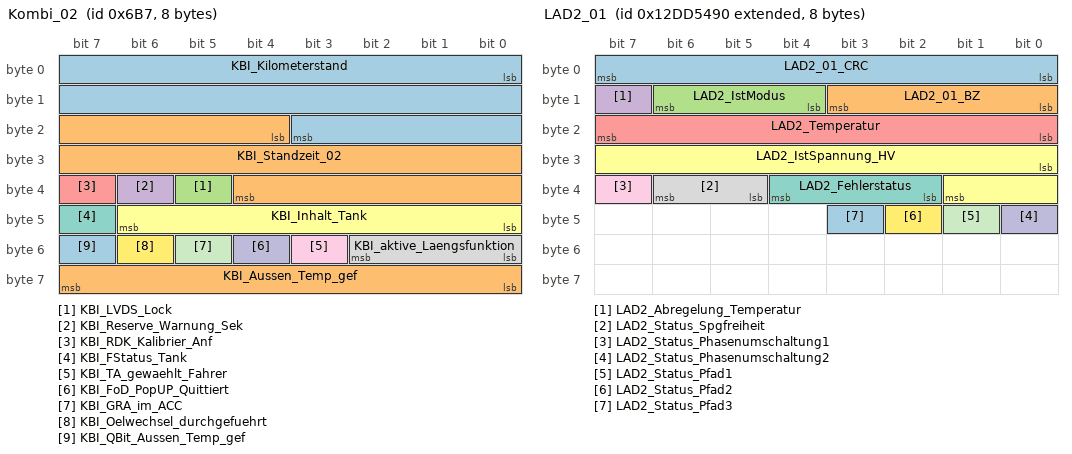
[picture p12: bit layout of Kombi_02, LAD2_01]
BO_ 1719 Kombi_02: 8 Gateway
 SG_ KBI_Kilometerstand : 0|20@1+ (1,0) [0|1048573] "Unit_KiloMeter"  Sub_Gateway
 SG_ KBI_Standzeit_02 : 20|17@1+ (1,0) [0|131068] "Unit_Secon"  Sub_Gateway,TME
 SG_ KBI_LVDS_Lock : 37|1@1+ (1.0,0.0) [0.0|1] ""  Sub_Gateway
 SG_ KBI_Reserve_Warnung_Sek : 38|1@1+ (1.0,0.0) [0.0|1] ""  Sub_Gateway
 SG_ KBI_RDK_Kalibrier_Anf : 39|1@1+ (1.0,0.0) [0.0|1] ""  Sub_Gateway
 SG_ KBI_Inhalt_Tank : 40|7@1+ (1,0) [0|125] "Unit_Liter"  Sub_Gateway
 SG_ KBI_FStatus_Tank : 47|1@1+ (1.0,0.0) [0.0|1] ""  Sub_Gateway
 SG_ KBI_aktive_Laengsfunktion : 48|3@1+ (1.0,0.0) [0.0|7] ""  Sub_Gateway
 SG_ KBI_TA_gewaehlt_Fahrer : 51|1@1+ (1.0,0.0) [0.0|1] ""  Sub_Gateway
 SG_ KBI_FoD_PopUP_Quittiert : 52|1@1+ (1.0,0.0) [0.0|1] ""  Sub_Gateway
 SG_ KBI_GRA_im_ACC : 53|1@1+ (1.0,0.0) [0.0|1] ""  Sub_Gateway
 SG_ KBI_Oelwechsel_durchgefuehrt : 54|1@1+ (1.0,0.0) [0.0|1] ""  Sub_Gateway
 SG_ KBI_QBit_Aussen_Temp_gef : 55|1@1+ (1.0,0.0) [0.0|1] ""  Sub_Gateway
 SG_ KBI_Aussen_Temp_gef : 56|8@1+ (0.5,-50) [-50.0|75.0] "Unit_DegreCelsi"  Ladegeraet_Konzern,Sub_Gateway

BO_ 2549875067 KS_Hybrid_01_Req: 8 Gateway
 SG_ KS_Hybrid_01_Req_Data : 0|64@1+ (1.0,0.0) [0.0|18446744073709551615] ""  BMC_MLBevo

BO_ 2550006139 KS_Hybrid_01_Resp: 8 BMC_MLBevo
 SG_ KS_Hybrid_01_Resp_Data : 0|64@1+ (1.0,0.0) [0.0|18446744073709551615] ""  Gateway,Gateway_PAG

BO_ 2549875142 KS_Ladegeraet_2_Req: 8 Gateway
 SG_ KS_Ladegeraet_2_Req_Data : 0|64@1+ (1.0,0.0) [0.0|18446744073709551615] ""  Ladegeraet_2

BO_ 2550006214 KS_Ladegeraet_2_Resp: 8 Ladegeraet_2
 SG_ KS_Ladegeraet_2_Resp_Data : 0|64@1+ (1.0,0.0) [0.0|18446744073709551615] ""  Gateway,Gateway_PAG

BO_ 2549875012 KS_Ladegeraet_Req: 8 Gateway
 SG_ KS_Ladegeraet_Req_Data : 0|64@1+ (1.0,0.0) [0.0|18446744073709551615] ""  Ladegeraet_Konzern

BO_ 2550006084 KS_Ladegeraet_Resp: 8 Ladegeraet_Konzern
 SG_ KS_Ladegeraet_Resp_Data : 0|64@1+ (1.0,0.0) [0.0|18446744073709551615] ""  Gateway,Gateway_PAG

BO_ 2549899473 KS_SSN_CMC_01_Req: 8 Gateway
 SG_ KS_SSN_CMC_01_Req_Data : 0|64@1+ (1.0,0.0) [0.0|18446744073709551615] ""  BMC_MLBevo

BO_ 2550030545 KS_SSN_CMC_01_Resp: 8 BMC_MLBevo
 SG_ KS_SSN_CMC_01_Resp_Data : 0|64@1+ (1.0,0.0) [0.0|18446744073709551615] ""  Gateway

BO_ 2549899474 KS_SSN_CMC_02_Req: 8 Gateway
 SG_ KS_SSN_CMC_02_Req_Data : 0|64@1+ (1.0,0.0) [0.0|18446744073709551615] ""  BMC_MLBevo

BO_ 2550030546 KS_SSN_CMC_02_Resp: 8 BMC_MLBevo
 SG_ KS_SSN_CMC_02_Resp_Data : 0|64@1+ (1.0,0.0) [0.0|18446744073709551615] ""  Gateway

BO_ 2549899475 KS_SSN_CMC_03_Req: 8 Gateway
 SG_ KS_SSN_CMC_03_Req_Data : 0|64@1+ (1.0,0.0) [0.0|18446744073709551615] ""  BMC_MLBevo

BO_ 2550030547 KS_SSN_CMC_03_Resp: 8 BMC_MLBevo
 SG_ KS_SSN_CMC_03_Resp_Data : 0|64@1+ (1.0,0.0) [0.0|18446744073709551615] ""  Gateway

BO_ 2549899476 KS_SSN_CMC_04_Req: 8 Gateway
 SG_ KS_SSN_CMC_04_Req_Data : 0|64@1+ (1.0,0.0) [0.0|18446744073709551615] ""  BMC_MLBevo

BO_ 2550030548 KS_SSN_CMC_04_Resp: 8 BMC_MLBevo
 SG_ KS_SSN_CMC_04_Resp_Data : 0|64@1+ (1.0,0.0) [0.0|18446744073709551615] ""  Gateway

BO_ 2549899477 KS_SSN_CMC_05_Req: 8 Gateway
 SG_ KS_SSN_CMC_05_Req_Data : 0|64@1+ (1.0,0.0) [0.0|18446744073709551615] ""  BMC_MLBevo

BO_ 2550030549 KS_SSN_CMC_05_Resp: 8 BMC_MLBevo
 SG_ KS_SSN_CMC_05_Resp_Data : 0|64@1+ (1.0,0.0) [0.0|18446744073709551615] ""  Gateway

BO_ 2549899478 KS_SSN_CMC_06_Req: 8 Gateway
 SG_ KS_SSN_CMC_06_Req_Data : 0|64@1+ (1.0,0.0) [0.0|18446744073709551615] ""  BMC_MLBevo

BO_ 2550030550 KS_SSN_CMC_06_Resp: 8 BMC_MLBevo
 SG_ KS_SSN_CMC_06_Resp_Data : 0|64@1+ (1.0,0.0) [0.0|18446744073709551615] ""  Gateway

BO_ 2549899479 KS_SSN_CMC_07_Req: 8 Gateway
 SG_ KS_SSN_CMC_07_Req_Data : 0|64@1+ (1.0,0.0) [0.0|18446744073709551615] ""  BMC_MLBevo

BO_ 2550030551 KS_SSN_CMC_07_Resp: 8 BMC_MLBevo
 SG_ KS_SSN_CMC_07_Resp_Data : 0|64@1+ (1.0,0.0) [0.0|18446744073709551615] ""  Gateway

BO_ 2549899480 KS_SSN_CMC_08_Req: 8 Gateway
 SG_ KS_SSN_CMC_08_Req_Data : 0|64@1+ (1.0,0.0) [0.0|18446744073709551615] ""  BMC_MLBevo

BO_ 2550030552 KS_SSN_CMC_08_Resp: 8 BMC_MLBevo
 SG_ KS_SSN_CMC_08_Resp_Data : 0|64@1+ (1.0,0.0) [0.0|18446744073709551615] ""  Gateway

BO_ 2549899481 KS_SSN_CMC_09_Req: 8 Gateway
 SG_ KS_SSN_CMC_09_Req_Data : 0|64@1+ (1.0,0.0) [0.0|18446744073709551615] ""  BMC_MLBevo

BO_ 2550030553 KS_SSN_CMC_09_Resp: 8 BMC_MLBevo
 SG_ KS_SSN_CMC_09_Resp_Data : 0|64@1+ (1.0,0.0) [0.0|18446744073709551615] ""  Gateway

BO_ 2549899482 KS_SSN_CMC_10_Req: 8 Gateway
 SG_ KS_SSN_CMC_10_Req_Data : 0|64@1+ (1.0,0.0) [0.0|18446744073709551615] ""  BMC_MLBevo

BO_ 2550030554 KS_SSN_CMC_10_Resp: 8 BMC_MLBevo
 SG_ KS_SSN_CMC_10_Resp_Data : 0|64@1+ (1.0,0.0) [0.0|18446744073709551615] ""  Gateway

BO_ 2549899483 KS_SSN_CMC_11_Req: 8 Gateway
 SG_ KS_SSN_CMC_11_Req_Data : 0|64@1+ (1.0,0.0) [0.0|18446744073709551615] ""  BMC_MLBevo

BO_ 2550030555 KS_SSN_CMC_11_Resp: 8 BMC_MLBevo
 SG_ KS_SSN_CMC_11_Resp_Data : 0|64@1+ (1.0,0.0) [0.0|18446744073709551615] ""  Gateway

BO_ 2549899484 KS_SSN_CMC_12_Req: 8 Gateway
 SG_ KS_SSN_CMC_12_Req_Data : 0|64@1+ (1.0,0.0) [0.0|18446744073709551615] ""  BMC_MLBevo

BO_ 2550030556 KS_SSN_CMC_12_Resp: 8 BMC_MLBevo
 SG_ KS_SSN_CMC_12_Resp_Data : 0|64@1+ (1.0,0.0) [0.0|18446744073709551615] ""  Gateway

BO_ 2549899505 KS_SSN_CMC_13_Req: 8 Gateway
 SG_ KS_SSN_CMC_13_Req_Data : 0|64@1+ (1.0,0.0) [0.0|18446744073709551615] ""  BMC_MLBevo

BO_ 2550030577 KS_SSN_CMC_13_Resp: 8 BMC_MLBevo
 SG_ KS_SSN_CMC_13_Resp_Data : 0|64@1+ (1.0,0.0) [0.0|18446744073709551615] ""  Gateway

BO_ 2549899506 KS_SSN_CMC_14_Req: 8 Gateway
 SG_ KS_SSN_CMC_14_Req_Data : 0|64@1+ (1.0,0.0) [0.0|18446744073709551615] ""  BMC_MLBevo

BO_ 2550030578 KS_SSN_CMC_14_Resp: 8 BMC_MLBevo
 SG_ KS_SSN_CMC_14_Resp_Data : 0|64@1+ (1.0,0.0) [0.0|18446744073709551615] ""  Gateway

BO_ 2549899507 KS_SSN_CMC_15_Req: 8 Gateway
 SG_ KS_SSN_CMC_15_Req_Data : 0|64@1+ (1.0,0.0) [0.0|18446744073709551615] ""  BMC_MLBevo

BO_ 2550030579 KS_SSN_CMC_15_Resp: 8 BMC_MLBevo
 SG_ KS_SSN_CMC_15_Resp_Data : 0|64@1+ (1.0,0.0) [0.0|18446744073709551615] ""  Gateway

BO_ 2463978640 LAD2_01: 8 Ladegeraet_2
 SG_ LAD2_01_CRC : 0|8@1+ (1,0) [0|255] ""  Gateway,Gateway_PAG,Ladegeraet_Konzern
 SG_ LAD2_01_BZ : 8|4@1+ (1,0) [0|15] ""  Gateway,Gateway_PAG,Ladegeraet_Konzern
 SG_ LAD2_IstModus : 12|3@1+ (1.0,0.0) [0.0|7] ""  Ladegeraet_Konzern
 SG_ LAD2_Abregelung_Temperatur : 15|1@1+ (1.0,0.0) [0.0|1] ""  Ladegeraet_Konzern
 SG_ LAD2_Temperatur : 16|8@1+ (1,-40) [-40|213] "Unit_DegreCelsi"  Ladegeraet_Konzern
 SG_ LAD2_IstSpannung_HV : 24|10@1+ (1,0) [0|1021] "Unit_Volt"  Gateway,Gateway_PAG,Ladegeraet_Konzern
 SG_ LAD2_Fehlerstatus : 34|3@1+ (1.0,0.0) [0.0|7] ""  Gateway,Gateway_PAG,Ladegeraet_Konzern
 SG_ LAD2_Status_Spgfreiheit : 37|2@1+ (1.0,0.0) [0.0|3] ""  Gateway,Gateway_PAG,Ladegeraet_Konzern
 SG_ LAD2_Status_Phasenumschaltung1 : 39|1@1+ (1.0,0.0) [0.0|1] ""  Ladegeraet_Konzern
 SG_ LAD2_Status_Phasenumschaltung2 : 40|1@1+ (1.0,0.0) [0.0|1] ""  Ladegeraet_Konzern
 SG_ LAD2_Status_Pfad1 : 41|1@1+ (1.0,0.0) [0.0|1] ""  Ladegeraet_Konzern
 SG_ LAD2_Status_Pfad2 : 42|1@1+ (1.0,0.0) [0.0|1] ""  Ladegeraet_Konzern
 SG_ LAD2_Status_Pfad3 : 43|1@1+ (1.0,0.0) [0.0|1] ""  Ladegeraet_Konzern

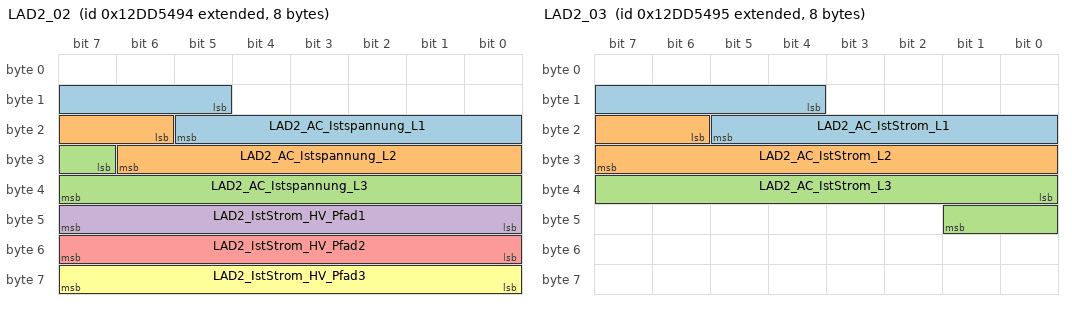
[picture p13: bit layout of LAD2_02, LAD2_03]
BO_ 2463978644 LAD2_02: 8 Ladegeraet_2
 SG_ LAD2_AC_Istspannung_L1 : 13|9@1+ (1,0) [0|509] "Unit_Volt"  Ladegeraet_Konzern
 SG_ LAD2_AC_Istspannung_L2 : 22|9@1+ (1,0) [0|509] "Unit_Volt"  Ladegeraet_Konzern
 SG_ LAD2_AC_Istspannung_L3 : 31|9@1+ (1,0) [0|509] "Unit_Volt"  Ladegeraet_Konzern
 SG_ LAD2_IstStrom_HV_Pfad1 : 40|8@1+ (0.1,0) [0.0|25.3] "Unit_Amper"  Ladegeraet_Konzern
 SG_ LAD2_IstStrom_HV_Pfad2 : 48|8@1+ (0.1,0) [0.0|25.3] "Unit_Amper"  Ladegeraet_Konzern
 SG_ LAD2_IstStrom_HV_Pfad3 : 56|8@1+ (0.1,0) [0.0|25.3] "Unit_Amper"  Ladegeraet_Konzern

BO_ 2463978645 LAD2_03: 8 Ladegeraet_2
 SG_ LAD2_AC_IstStrom_L1 : 12|10@1+ (0.1,0) [0.0|102.1] "Unit_Amper"  Ladegeraet_Konzern
 SG_ LAD2_AC_IstStrom_L2 : 22|10@1+ (0.1,0) [0.0|102.1] "Unit_Amper"  Ladegeraet_Konzern
 SG_ LAD2_AC_IstStrom_L3 : 32|10@1+ (0.1,0) [0.0|102.1] "Unit_Amper"  Ladegeraet_Konzern

BO_ 2589283493 LAD2_CALID_CVN: 8 Ladegeraet_2
 SG_ LAD2_CALID_CVN_MUX M  : 0|2@1+ (1,0) [0|3] "Unit_None"  BMC_MLBevo
 SG_ LAD2_CVN_VLD : 7|1@1+ (1.0,0.0) [0.0|1] ""  BMC_MLBevo
 SG_ LAD2_CALID_Index_01 m0  : 8|8@1+ (1.0,0.0) [0.0|255] ""  BMC_MLBevo
 SG_ LAD2_CALID_Index_05 m1  : 8|8@1+ (1.0,0.0) [0.0|255] ""  BMC_MLBevo
 SG_ LAD2_CALID_Index_09 m2  : 8|8@1+ (1.0,0.0) [0.0|255] ""  BMC_MLBevo
 SG_ LAD2_CALID_Index_13 m3  : 8|8@1+ (1.0,0.0) [0.0|255] ""  BMC_MLBevo
 SG_ LAD2_CALID_Index_02 m0  : 16|8@1+ (1.0,0.0) [0.0|255] ""  BMC_MLBevo
 SG_ LAD2_CALID_Index_06 m1  : 16|8@1+ (1.0,0.0) [0.0|255] ""  BMC_MLBevo
 SG_ LAD2_CALID_Index_10 m2  : 16|8@1+ (1.0,0.0) [0.0|255] ""  BMC_MLBevo
 SG_ LAD2_CALID_Index_14 m3  : 16|8@1+ (1.0,0.0) [0.0|255] ""  BMC_MLBevo
 SG_ LAD2_CALID_Index_03 m0  : 24|8@1+ (1.0,0.0) [0.0|255] ""  BMC_MLBevo
 SG_ LAD2_CALID_Index_07 m1  : 24|8@1+ (1.0,0.0) [0.0|255] ""  BMC_MLBevo
 SG_ LAD2_CALID_Index_11 m2  : 24|8@1+ (1.0,0.0) [0.0|255] ""  BMC_MLBevo
 SG_ LAD2_CALID_Index_15 m3  : 24|8@1+ (1.0,0.0) [0.0|255] ""  BMC_MLBevo
 SG_ LAD2_CALID_Index_04 m0  : 32|8@1+ (1.0,0.0) [0.0|255] ""  BMC_MLBevo
 SG_ LAD2_CALID_Index_08 m1  : 32|8@1+ (1.0,0.0) [0.0|255] ""  BMC_MLBevo
 SG_ LAD2_CALID_Index_12 m2  : 32|8@1+ (1.0,0.0) [0.0|255] ""  BMC_MLBevo
 SG_ LAD2_CALID_Index_16 m3  : 32|8@1+ (1.0,0.0) [0.0|255] ""  BMC_MLBevo
 SG_ LAD2_CVN_Byte_1 m0  : 40|8@1+ (1.0,0.0) [0.0|255] ""  BMC_MLBevo
 SG_ LAD2_CVN_Byte_2 m1  : 40|8@1+ (1.0,0.0) [0.0|255] ""  BMC_MLBevo
 SG_ LAD2_CVN_Byte_3 m2  : 40|8@1+ (1.0,0.0) [0.0|255] ""  BMC_MLBevo
 SG_ LAD2_CVN_Byte_4 m3  : 40|8@1+ (1.0,0.0) [0.0|255] ""  BMC_MLBevo

BO_ 2589283392 LAD2_KomponentenFehler_01: 8 Ladegeraet_2
 SG_ LAD2_KomponentenFehler_01 : 24|2@1+ (1.0,0.0) [0.0|3] ""  BMC_MLBevo
 SG_ LAD2_KomponentenFehler_02 : 26|2@1+ (1.0,0.0) [0.0|3] ""  BMC_MLBevo
 SG_ LAD2_KomponentenFehler_03 : 28|2@1+ (1.0,0.0) [0.0|3] ""  BMC_MLBevo
 SG_ LAD2_KomponentenFehler_04 : 30|2@1+ (1.0,0.0) [0.0|3] ""  BMC_MLBevo
 SG_ LAD2_KomponentenFehler_05 : 32|2@1+ (1.0,0.0) [0.0|3] ""  BMC_MLBevo
 SG_ LAD2_KomponentenFehler_06 : 34|2@1+ (1.0,0.0) [0.0|3] ""  BMC_MLBevo
 SG_ LAD2_KomponentenFehler_07 : 36|2@1+ (1.0,0.0) [0.0|3] ""  BMC_MLBevo
 SG_ LAD2_KomponentenFehler_08 : 38|2@1+ (1.0,0.0) [0.0|3] ""  BMC_MLBevo
 SG_ LAD2_KomponentenFehler_09 : 40|2@1+ (1.0,0.0) [0.0|3] ""  BMC_MLBevo
 SG_ LAD2_KomponentenFehler_10 : 42|2@1+ (1.0,0.0) [0.0|3] ""  BMC_MLBevo
 SG_ LAD2_KomponentenFehler_11 : 44|2@1+ (1.0,0.0) [0.0|3] ""  BMC_MLBevo
 SG_ LAD2_KomponentenFehler_12 : 46|2@1+ (1.0,0.0) [0.0|3] ""  BMC_MLBevo
 SG_ LAD2_KomponentenFehler_13 : 48|2@1+ (1.0,0.0) [0.0|3] ""  BMC_MLBevo
 SG_ LAD2_KomponentenFehler_14 : 50|2@1+ (1.0,0.0) [0.0|3] ""  BMC_MLBevo
 SG_ LAD2_KomponentenFehler_15 : 52|2@1+ (1.0,0.0) [0.0|3] ""  BMC_MLBevo
 SG_ LAD2_KomponentenFehler_16 : 54|2@1+ (1.0,0.0) [0.0|3] ""  BMC_MLBevo
 SG_ LAD2_KomponentenFehler_17 : 56|2@1+ (1.0,0.0) [0.0|3] ""  BMC_MLBevo
 SG_ LAD2_KomponentenFehler_18 : 58|2@1+ (1.0,0.0) [0.0|3] ""  BMC_MLBevo
 SG_ LAD2_KomponentenFehler_19 : 60|2@1+ (1.0,0.0) [0.0|3] ""  BMC_MLBevo
 SG_ LAD2_KomponentenFehler_20 : 62|2@1+ (1.0,0.0) [0.0|3] ""  BMC_MLBevo

BO_ 2589283688 LAD2_Version: 8 Ladegeraet_2
 SG_ LAD2_Version : 0|2@1+ (1.0,0.0) [0.0|3] ""  Ladegeraet_Konzern
 SG_ LAD2_Version_MUX M  : 6|2@1+ (1,0) [0|3] "Unit_None"  Ladegeraet_Konzern
 SG_ LAD2_Version_Index_01 m0  : 8|5@1+ (1.0,0.0) [0.0|31] ""  Ladegeraet_Konzern
 SG_ LAD2_Version_Index_02 m1  : 8|5@1+ (1.0,0.0) [0.0|31] ""  Ladegeraet_Konzern
 SG_ LAD2_Version_Index_03 m2  : 8|5@1+ (1.0,0.0) [0.0|31] ""  Ladegeraet_Konzern
 SG_ LAD2_Version_Index_04 m3  : 8|5@1+ (1.0,0.0) [0.0|31] ""  Ladegeraet_Konzern

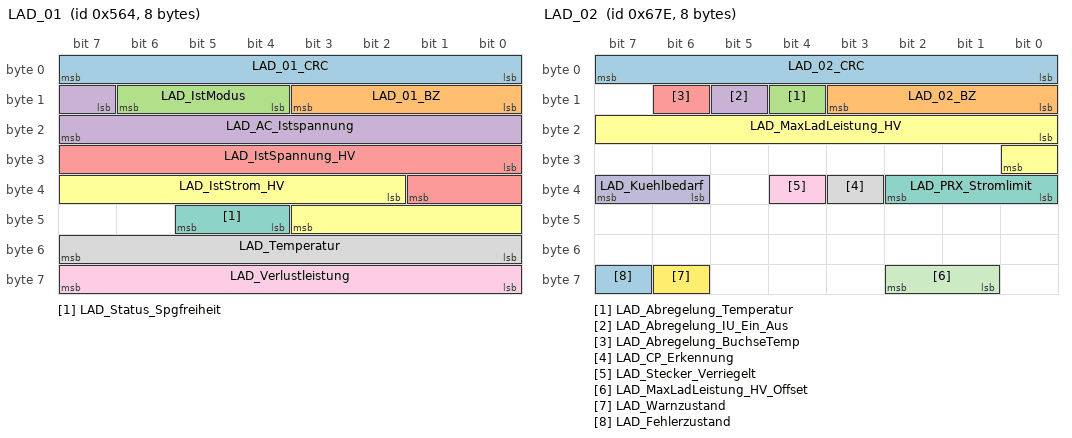
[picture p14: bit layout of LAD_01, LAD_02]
BO_ 1380 LAD_01: 8 Ladegeraet_Konzern
 SG_ LAD_01_CRC : 0|8@1+ (1,0) [0|255] ""  Gateway,Gateway_PAG
 SG_ LAD_01_BZ : 8|4@1+ (1,0) [0|15] ""  Gateway,Gateway_PAG
 SG_ LAD_IstModus : 12|3@1+ (1.0,0.0) [0.0|7] ""  Gateway,Gateway_PAG,Ladegeraet_2,TME
 SG_ LAD_AC_Istspannung : 15|9@1+ (1,0) [0|509] "Unit_Volt"  Gateway_PAG
 SG_ LAD_IstSpannung_HV : 24|10@1+ (1,0) [0|1021] "Unit_Volt"  Gateway_PAG
 SG_ LAD_IstStrom_HV : 34|10@1+ (0.2,-102) [-102.0|102.2] "Unit_Amper"  Gateway,Gateway_PAG
 SG_ LAD_Status_Spgfreiheit : 44|2@1+ (1.0,0.0) [0.0|3] ""  Gateway,Gateway_PAG
 SG_ LAD_Temperatur : 48|8@1+ (1,-40) [-40|213] "Unit_DegreCelsi"  Gateway_PAG,TME
 SG_ LAD_Verlustleistung : 56|8@1+ (20,0) [0|5060] "Unit_Watt"  Gateway_PAG,TME

BO_ 1662 LAD_02: 8 Ladegeraet_Konzern
 SG_ LAD_02_CRC : 0|8@1+ (1,0) [0|255] ""  Gateway,Gateway_PAG
 SG_ LAD_02_BZ : 8|4@1+ (1,0) [0|15] ""  Gateway,Gateway_PAG
 SG_ LAD_Abregelung_Temperatur : 12|1@1+ (1.0,0.0) [0.0|1] ""  TME
 SG_ LAD_Abregelung_IU_Ein_Aus : 13|1@1+ (1.0,0.0) [0.0|1] ""  Vector__XXX
 SG_ LAD_Abregelung_BuchseTemp : 14|1@1+ (1.0,0.0) [0.0|1] ""  Vector__XXX
 SG_ LAD_MaxLadLeistung_HV : 16|9@1+ (100,0) [0|50900] "Unit_Watt"  TME
 SG_ LAD_PRX_Stromlimit : 32|3@1+ (1.0,0.0) [0.0|7] ""  Vector__XXX
 SG_ LAD_CP_Erkennung : 35|1@1+ (1.0,0.0) [0.0|1] ""  Vector__XXX
 SG_ LAD_Stecker_Verriegelt : 36|1@1+ (1.0,0.0) [0.0|1] ""  Vector__XXX
 SG_ LAD_Kuehlbedarf : 38|2@1+ (1.0,0.0) [0.0|3] ""  Vector__XXX
 SG_ LAD_MaxLadLeistung_HV_Offset : 57|2@1+ (1.0,0.0) [0.0|3] ""  Vector__XXX
 SG_ LAD_Warnzustand : 62|1@1+ (1.0,0.0) [0.0|1] ""  Vector__XXX
 SG_ LAD_Fehlerzustand : 63|1@1+ (1.0,0.0) [0.0|1] ""  Vector__XXX

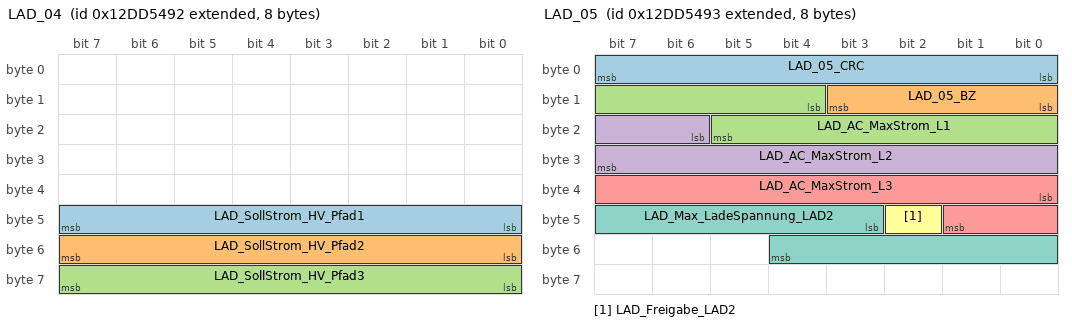
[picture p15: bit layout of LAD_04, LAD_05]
BO_ 2463978642 LAD_04: 8 Ladegeraet_Konzern
 SG_ LAD_SollStrom_HV_Pfad1 : 40|8@1+ (0.1,0) [0.0|25.3] "Unit_Amper"  Ladegeraet_2
 SG_ LAD_SollStrom_HV_Pfad2 : 48|8@1+ (0.1,0) [0.0|25.3] "Unit_Amper"  Ladegeraet_2
 SG_ LAD_SollStrom_HV_Pfad3 : 56|8@1+ (0.1,0) [0.0|25.3] "Unit_Amper"  Ladegeraet_2

BO_ 2463978643 LAD_05: 8 Ladegeraet_Konzern
 SG_ LAD_05_CRC : 0|8@1+ (1,0) [0|255] ""  Ladegeraet_2
 SG_ LAD_05_BZ : 8|4@1+ (1,0) [0|15] ""  Ladegeraet_2
 SG_ LAD_AC_MaxStrom_L1 : 12|10@1+ (0.1,0) [0.0|102.1] "Unit_Amper"  Ladegeraet_2
 SG_ LAD_AC_MaxStrom_L2 : 22|10@1+ (0.1,0) [0.0|102.1] "Unit_Amper"  Ladegeraet_2
 SG_ LAD_AC_MaxStrom_L3 : 32|10@1+ (0.1,0) [0.0|102.1] "Unit_Amper"  Ladegeraet_2
 SG_ LAD_Freigabe_LAD2 : 42|1@1+ (1.0,0.0) [0.0|1] ""  Ladegeraet_2
 SG_ LAD_Max_LadeSpannung_LAD2 : 43|10@1+ (1,0) [0|1021] "Unit_Volt"  Ladegeraet_2

BO_ 2589283663 LAD_06: 8 Ladegeraet_Konzern
 SG_ LAD_PlanAntw_Verlustleistung : 48|12@1+ (50,0) [0|204650] "Unit_Watt"  TME
 SG_ LAD_PlanAntw_Zaehler : 60|4@1+ (1,0) [0|13] "Unit_None"  TME

BO_ 2589283415 LAD_CALID_CVN: 8 Ladegeraet_Konzern
 SG_ LAD_CALID_CVN_MUX M  : 0|2@1+ (1,0) [0|3] "Unit_None"  BMC_MLBevo
 SG_ LAD_CVN_VLD : 7|1@1+ (1.0,0.0) [0.0|1] ""  BMC_MLBevo
 SG_ LAD_CALID_Index_01 m0  : 8|8@1+ (1.0,0.0) [0.0|255] ""  BMC_MLBevo
 SG_ LAD_CALID_Index_05 m1  : 8|8@1+ (1.0,0.0) [0.0|255] ""  BMC_MLBevo
 SG_ LAD_CALID_Index_09 m2  : 8|8@1+ (1.0,0.0) [0.0|255] ""  BMC_MLBevo
 SG_ LAD_CALID_Index_13 m3  : 8|8@1+ (1.0,0.0) [0.0|255] ""  BMC_MLBevo
 SG_ LAD_CALID_Index_02 m0  : 16|8@1+ (1.0,0.0) [0.0|255] ""  BMC_MLBevo
 SG_ LAD_CALID_Index_06 m1  : 16|8@1+ (1.0,0.0) [0.0|255] ""  BMC_MLBevo
 SG_ LAD_CALID_Index_10 m2  : 16|8@1+ (1.0,0.0) [0.0|255] ""  BMC_MLBevo
 SG_ LAD_CALID_Index_14 m3  : 16|8@1+ (1.0,0.0) [0.0|255] ""  BMC_MLBevo
 SG_ LAD_CALID_Index_03 m0  : 24|8@1+ (1.0,0.0) [0.0|255] ""  BMC_MLBevo
 SG_ LAD_CALID_Index_07 m1  : 24|8@1+ (1.0,0.0) [0.0|255] ""  BMC_MLBevo
 SG_ LAD_CALID_Index_11 m2  : 24|8@1+ (1.0,0.0) [0.0|255] ""  BMC_MLBevo
 SG_ LAD_CALID_Index_15 m3  : 24|8@1+ (1.0,0.0) [0.0|255] ""  BMC_MLBevo
 SG_ LAD_CALID_Index_04 m0  : 32|8@1+ (1.0,0.0) [0.0|255] ""  BMC_MLBevo
 SG_ LAD_CALID_Index_08 m1  : 32|8@1+ (1.0,0.0) [0.0|255] ""  BMC_MLBevo
 SG_ LAD_CALID_Index_12 m2  : 32|8@1+ (1.0,0.0) [0.0|255] ""  BMC_MLBevo
 SG_ LAD_CALID_Index_16 m3  : 32|8@1+ (1.0,0.0) [0.0|255] ""  BMC_MLBevo
 SG_ LAD_CVN_Byte_1 m0  : 40|8@1+ (1.0,0.0) [0.0|255] ""  BMC_MLBevo
 SG_ LAD_CVN_Byte_2 m1  : 40|8@1+ (1.0,0.0) [0.0|255] ""  BMC_MLBevo
 SG_ LAD_CVN_Byte_3 m2  : 40|8@1+ (1.0,0.0) [0.0|255] ""  BMC_MLBevo
 SG_ LAD_CVN_Byte_4 m3  : 40|8@1+ (1.0,0.0) [0.0|255] ""  BMC_MLBevo

BO_ 2589283472 LAD_Komponentenfehler: 8 Ladegeraet_Konzern
 SG_ LAD_KomponentenFehler_01 : 0|2@1+ (1.0,0.0) [0.0|3] ""  BMC_MLBevo
 SG_ LAD_KomponentenFehler_02 : 2|2@1+ (1.0,0.0) [0.0|3] ""  BMC_MLBevo
 SG_ LAD_KomponentenFehler_03 : 4|2@1+ (1.0,0.0) [0.0|3] ""  BMC_MLBevo
 SG_ LAD_KomponentenFehler_04 : 6|2@1+ (1.0,0.0) [0.0|3] ""  BMC_MLBevo
 SG_ LAD_KomponentenFehler_05 : 8|2@1+ (1.0,0.0) [0.0|3] ""  BMC_MLBevo
 SG_ LAD_KomponentenFehler_06 : 10|2@1+ (1.0,0.0) [0.0|3] ""  BMC_MLBevo
 SG_ LAD_KomponentenFehler_07 : 12|2@1+ (1.0,0.0) [0.0|3] ""  BMC_MLBevo
 SG_ LAD_KomponentenFehler_08 : 14|2@1+ (1.0,0.0) [0.0|3] ""  BMC_MLBevo
 SG_ LAD_KomponentenFehler_09 : 16|2@1+ (1.0,0.0) [0.0|3] ""  BMC_MLBevo
 SG_ LAD_KomponentenFehler_10 : 18|2@1+ (1.0,0.0) [0.0|3] ""  BMC_MLBevo
 SG_ LAD_KomponentenFehler_11 : 20|2@1+ (1.0,0.0) [0.0|3] ""  BMC_MLBevo
 SG_ LAD_KomponentenFehler_12 : 22|2@1+ (1.0,0.0) [0.0|3] ""  BMC_MLBevo
 SG_ LAD_KomponentenFehler_13 : 24|2@1+ (1.0,0.0) [0.0|3] ""  BMC_MLBevo
 SG_ LAD_KomponentenFehler_14 : 26|2@1+ (1.0,0.0) [0.0|3] ""  BMC_MLBevo
 SG_ LAD_KomponentenFehler_15 : 28|2@1+ (1.0,0.0) [0.0|3] ""  BMC_MLBevo
 SG_ LAD_KomponentenFehler_16 : 30|2@1+ (1.0,0.0) [0.0|3] ""  BMC_MLBevo
 SG_ LAD_KomponentenFehler_17 : 32|2@1+ (1.0,0.0) [0.0|3] ""  BMC_MLBevo
 SG_ LAD_KomponentenFehler_18 : 34|2@1+ (1.0,0.0) [0.0|3] ""  BMC_MLBevo
 SG_ LAD_KomponentenFehler_19 : 36|2@1+ (1.0,0.0) [0.0|3] ""  BMC_MLBevo
 SG_ LAD_KomponentenFehler_20 : 38|2@1+ (1.0,0.0) [0.0|3] ""  BMC_MLBevo
 SG_ LAD_KomponentenFehler_21 : 40|2@1+ (1.0,0.0) [0.0|3] ""  BMC_MLBevo
 SG_ LAD_KomponentenFehler_22 : 42|2@1+ (1.0,0.0) [0.0|3] ""  BMC_MLBevo
 SG_ LAD_KomponentenFehler_23 : 44|2@1+ (1.0,0.0) [0.0|3] ""  BMC_MLBevo
 SG_ LAD_KomponentenFehler_24 : 46|2@1+ (1.0,0.0) [0.0|3] ""  BMC_MLBevo
 SG_ LAD_KomponentenFehler_25 : 48|2@1+ (1.0,0.0) [0.0|3] ""  BMC_MLBevo
 SG_ LAD_KomponentenFehler_26 : 50|2@1+ (1.0,0.0) [0.0|3] ""  BMC_MLBevo
 SG_ LAD_KomponentenFehler_27 : 52|2@1+ (1.0,0.0) [0.0|3] ""  BMC_MLBevo
 SG_ LAD_KomponentenFehler_28 : 54|2@1+ (1.0,0.0) [0.0|3] ""  BMC_MLBevo
 SG_ LAD_KomponentenFehler_29 : 56|2@1+ (1.0,0.0) [0.0|3] ""  BMC_MLBevo
 SG_ LAD_KomponentenFehler_30 : 58|2@1+ (1.0,0.0) [0.0|3] ""  BMC_MLBevo
 SG_ LAD_KomponentenFehler_31 : 60|2@1+ (1.0,0.0) [0.0|3] ""  BMC_MLBevo
 SG_ LAD_KomponentenFehler_32 : 62|2@1+ (1.0,0.0) [0.0|3] ""  BMC_MLBevo

BO_ 2589283473 LAD_Komponentenfehler2: 8 Ladegeraet_Konzern
 SG_ LAD_KomponentenFehler_33 : 0|2@1+ (1.0,0.0) [0.0|3] ""  BMC_MLBevo
 SG_ LAD_KomponentenFehler_34 : 2|2@1+ (1.0,0.0) [0.0|3] ""  BMC_MLBevo
 SG_ LAD_KomponentenFehler_35 : 4|2@1+ (1.0,0.0) [0.0|3] ""  BMC_MLBevo
 SG_ LAD_KomponentenFehler_36 : 6|2@1+ (1.0,0.0) [0.0|3] ""  BMC_MLBevo
 SG_ LAD_KomponentenFehler_37 : 8|2@1+ (1.0,0.0) [0.0|3] ""  BMC_MLBevo
 SG_ LAD_KomponentenFehler_38 : 10|2@1+ (1.0,0.0) [0.0|3] ""  BMC_MLBevo
 SG_ LAD_KomponentenFehler_39 : 12|2@1+ (1.0,0.0) [0.0|3] ""  BMC_MLBevo
 SG_ LAD_KomponentenFehler_40 : 14|2@1+ (1.0,0.0) [0.0|3] ""  BMC_MLBevo
 SG_ LAD_KomponentenFehler_41 : 16|2@1+ (1.0,0.0) [0.0|3] ""  BMC_MLBevo
 SG_ LAD_KomponentenFehler_42 : 18|2@1+ (1.0,0.0) [0.0|3] ""  BMC_MLBevo
 SG_ LAD_KomponentenFehler_43 : 20|2@1+ (1.0,0.0) [0.0|3] ""  BMC_MLBevo
 SG_ LAD_KomponentenFehler_44 : 22|2@1+ (1.0,0.0) [0.0|3] ""  BMC_MLBevo
 SG_ LAD_KomponentenFehler_45 : 24|2@1+ (1.0,0.0) [0.0|3] ""  BMC_MLBevo
 SG_ LAD_KomponentenFehler_46 : 26|2@1+ (1.0,0.0) [0.0|3] ""  BMC_MLBevo
 SG_ LAD_KomponentenFehler_47 : 28|2@1+ (1.0,0.0) [0.0|3] ""  BMC_MLBevo
 SG_ LAD_KomponentenFehler_48 : 30|2@1+ (1.0,0.0) [0.0|3] ""  BMC_MLBevo
 SG_ LAD_KomponentenFehler_49 : 32|2@1+ (1.0,0.0) [0.0|3] ""  BMC_MLBevo
 SG_ LAD_KomponentenFehler_50 : 34|2@1+ (1.0,0.0) [0.0|3] ""  BMC_MLBevo
 SG_ LAD_KomponentenFehler_51 : 36|2@1+ (1.0,0.0) [0.0|3] ""  BMC_MLBevo
 SG_ LAD_KomponentenFehler_52 : 38|2@1+ (1.0,0.0) [0.0|3] ""  BMC_MLBevo
 SG_ LAD_KomponentenFehler_53 : 40|2@1+ (1.0,0.0) [0.0|3] ""  BMC_MLBevo
 SG_ LAD_KomponentenFehler_54 : 42|2@1+ (1.0,0.0) [0.0|3] ""  BMC_MLBevo
 SG_ LAD_KomponentenFehler_55 : 44|2@1+ (1.0,0.0) [0.0|3] ""  BMC_MLBevo
 SG_ LAD_KomponentenFehler_56 : 46|2@1+ (1.0,0.0) [0.0|3] ""  BMC_MLBevo
 SG_ LAD_KomponentenFehler_57 : 48|2@1+ (1.0,0.0) [0.0|3] ""  BMC_MLBevo
 SG_ LAD_KomponentenFehler_58 : 50|2@1+ (1.0,0.0) [0.0|3] ""  BMC_MLBevo
 SG_ LAD_KomponentenFehler_59 : 52|2@1+ (1.0,0.0) [0.0|3] ""  BMC_MLBevo
 SG_ LAD_KomponentenFehler_60 : 54|2@1+ (1.0,0.0) [0.0|3] ""  BMC_MLBevo
 SG_ LAD_KomponentenFehler_61 : 56|2@1+ (1.0,0.0) [0.0|3] ""  BMC_MLBevo
 SG_ LAD_KomponentenFehler_62 : 58|2@1+ (1.0,0.0) [0.0|3] ""  BMC_MLBevo
 SG_ LAD_KomponentenFehler_63 : 60|2@1+ (1.0,0.0) [0.0|3] ""  BMC_MLBevo
 SG_ LAD_Komponentenfehler_VLD : 63|1@1+ (1.0,0.0) [0.0|1] ""  BMC_MLBevo

BO_TX_BU_ 2549874811 :Gateway,Gateway_PAG;
BO_TX_BU_ 2549874886 :Gateway,Gateway_PAG;
BO_TX_BU_ 2549874868 :Gateway,Gateway_PAG;
BO_TX_BU_ 497 :Gateway,Gateway_PAG;
BO_TX_BU_ 960 :Gateway,Gateway_PAG;
BO_TX_BU_ 1646 :Gateway,Gateway_PAG;
BO_TX_BU_ 1649 :Gateway,Gateway_PAG;
BO_TX_BU_ 949 :Gateway,Gateway_PAG;
BO_TX_BU_ 1640 :Gateway,Gateway_PAG;
BO_TX_BU_ 1441 :Gateway,Gateway_PAG;
BO_TX_BU_ 2589283469 :Gateway,Gateway_PAG;
BO_TX_BU_ 2589283621 :Gateway,Gateway_PAG;
BO_TX_BU_ 2463978701 :Gateway,Gateway_PAG;
BO_TX_BU_ 1712 :Gateway,Gateway_PAG;
BO_TX_BU_ 1505 :Gateway,Gateway_PAG;
BO_TX_BU_ 1717 :Gateway,Gateway_PAG;
BO_TX_BU_ 1513 :Gateway,Gateway_PAG;
BO_TX_BU_ 1295 :Gateway,Gateway_PAG;
BO_TX_BU_ 2589283474 :Gateway,Gateway_PAG;
BO_TX_BU_ 2549088439 :CBC,DCDC_800V_PAG,DCDC_HV;
BO_TX_BU_ 2549088272 :Gateway,Gateway_PAG;
BO_TX_BU_ 2549088259 :LE1,LE_MLBevo;
BO_TX_BU_ 779 :Gateway,Gateway_PAG;
BO_TX_BU_ 1719 :Gateway,Gateway_PAG;
BO_TX_BU_ 2549875067 :Gateway,Gateway_PAG;
BO_TX_BU_ 2549875142 :Gateway,Gateway_PAG;
BO_TX_BU_ 2549875012 :Gateway,Gateway_PAG;
CM_ BO_ 960 "MQB";
CM_ BO_ 1646 "ab MQB 7.3";
CM_ BO_ 949 "ab MQB 7.4";
CM_ BO_ 1640 "ab MQB IS-4";
CM_ BO_ 1712 "D4 und B8-PA

1:1 LIN-CAN Botschaft, nur bei Kl.15 EIN gesendet";
CM_ BO_ 1505 "ab MQB 7.3";
CM_ BO_ 1717 "ab D4 gültig  --  geänderter Wertebereich und Signalnamen
1:1 LIN-CAN Botschaft vom BCM1, nur bei Kl.15 EIN gesendet";
CM_ BO_ 779 "MQB";
CM_ BO_ 1380 "MLB, MXB, MLBevo";
CM_ BO_ 1662 "MLB, MXB, MLBevo";

CM_ SG_ 2549874869 ISOx_FCU_Req_Data "Diagnose Request";

CM_ SG_ 2550005941 ISOx_FCU_Resp_Data "Diagnose Response";

CM_ SG_ 2549874811 ISOx_Hybrid_01_Req_Data "OffBoard Tester Diagnose Request Hybrid_01";

CM_ SG_ 2550005883 ISOx_Hybrid_01_Resp_Data "OffBoard Tester Diagnose Response Hybrid_01";

CM_ SG_ 2549874886 ISOx_Ladegeraet_2_Req_Data "Diagnose Request Ladegerät_2";

CM_ SG_ 2550005958 ISOx_Ladegeraet_2_Resp_Data "Diagnose Response Ladegerät_2";

CM_ SG_ 2549874868 ISOx_TelemetrieSG_Req_Data "OffBoard Tester Diagnose Request TelemetrieSG";

CM_ SG_ 2550005940 ISOx_TelemetrieSG_Resp_Data "OffBoard Tester Diagnose Response TelemetrieSG";

CM_ SG_ 497 FBS_Aktivierung_Pilot_Parken "Aktivierung der Funktion pilotiertes Parken";
CM_ SG_ 497 FFB_FDF_Taste "FDF Taste am Funkschluessel";
CM_ SG_ 497 FFB_Joker_Taste "Frei konfigurierbare Taste auf der Funkfernbedienung (für Verdecktaste, UGDO Taste).
";
CM_ SG_ 497 FFB_Park_Taste "Parktaste Funkschluessel";
CM_ SG_ 497 FFB_Remotestart_Taste "Remotestart Taste Funkschluessel";
CM_ SG_ 497 KY_Auf_Taste "Auf-Taste Funkschluessel";
CM_ SG_ 497 KY_Bereich "Schlüsselentfernung für Funktionen Annäherungslicht, automatisches Entriegeln";
CM_ SG_ 497 KY_BT_Entriegelung_Autorisiert "Erkennung / Authorisierung Keyless BT
";
CM_ SG_ 497 KY_BT_Verriegelung_Autorisiert "Authorisierung Verriegelungssensor Keyless BT
";
CM_ SG_ 497 KY_EasyClose_Abbruch "ID-Geber während HD-Zufahrt im Nahbereich EasyClose erkannt";
CM_ SG_ 497 KY_EasyClose_Status "Signal zur LED Ansteuerung im HD-Verriegelungstaster für die Funktion EasyClose.";
CM_ SG_ 497 KY_Front_Entr_Autorisiert "Erkennung / Authorisierung Keyless Front";
CM_ SG_ 497 KY_Front_Verr_Autorisiert "Authorisierung Verriegelungssensor Keyless Front";
CM_ SG_ 497 KY_FT_Entriegelung_Autorisiert "Erkennung / Authorisierung Keyless FT
";
CM_ SG_ 497 KY_FT_Verriegelung_Autorisiert "Authorisierung Verriegelungssensor Keyless FT
";
CM_ SG_ 497 KY_HBFS_Entriegelung_Autorisiert "Erkennung / Authorisierung Keyless HBFS
";
CM_ SG_ 497 KY_HBFS_Verriegelung_Autorisiert "Authorisierung Verriegelungssensor Keyless HBFS


";
CM_ SG_ 497 KY_HD_Auffahrt "Auffahrt HD nach Wiedereintritt ID-Geber in EasyClose Nahbereich";
CM_ SG_ 497 KY_HD_Entriegelung_Autorisiert "Erkennung / Authorisierung Keyless Heck
";
CM_ SG_ 497 KY_HD_Verriegelung_Autorisiert "Autorisierung der Schließanforderung über Verriegelungsinnentaster";
CM_ SG_ 497 KY_HD_Zufahrt "Zufahrt HD nach erfolgreicher Funktion EasyClose";
CM_ SG_ 497 KY_HDF_Taste "HDF Taste am Funkschluessel";
CM_ SG_ 497 KY_HFS_Entriegelung_Autorisiert "Erkennung / Authorisierung Keyless HFS
";
CM_ SG_ 497 KY_HFS_Verriegelung_Autorisiert "Authorisierung Verriegelungssensor Keyless HFS

";
CM_ SG_ 497 KY_IDG_in_Reichweite "Für elektrisch betätigte Türen und Klappen muss für eine Betätigung über Funk eine Reichweitenbegrenzung eingeführt werden. Diese Bit zeigt an, dass sich der Funkschlüssel innerhalb der geforderten Reichweite befindet";
CM_ SG_ 497 KY_LKL_1_Autorisierung "Schlüsselstatus für Anfragen der Ladeklappe 1";
CM_ SG_ 497 KY_LKL_2_Autorisierung "Schlüsselstatus für Anfragen der Ladeklappe 2";
CM_ SG_ 497 KY_Panik_Taste "Panik Taste Funkschluessel";
CM_ SG_ 497 KY_Position "Schlüsselposition für Funktionen Annäherungslicht, automatisches Entriegeln";
CM_ SG_ 497 KY_Schluessel_im_Fzg "Zeigt einen erkannten Schlüssel im Fzg an.";
CM_ SG_ 497 KY_Zu_Taste "Zu-Taste Funkschluessel";
CM_ SG_ 497 KY_ZV_Signatur "Signatur der ZV";
CM_ SG_ 497 Schluesselnr_Personalisierung "Signal gibt die jewels aktuelle Schlüsselnummer für die Personalisierung wieder";

CM_ SG_ 960 BCM_Ausparken_Betrieb "Anforderung zur erneuten Lampenaufprüfung und Anzeige von Warnhinweisen nach einem pilotierten Ausparkvorgang (Trigger: fallende Flanke)";
CM_ SG_ 960 BCM_Remotestart_Betrieb "Zeigt den Status des RemoteStarts an, d.h. KL15_RSt ist aktiviert und der Motorlauf ist im RSt-Betrieb aktiv.";
CM_ SG_ 960 BCM_Remotestart_KL15_Anf "Zeigt den Status der Aktivierung der KL15_RST durch das BCM an.";
CM_ SG_ 960 BCM_Remotestart_MO_Start "Nachdem das BCM die Remotestart MSG Freigabe sicher erkannt hat, fordert das BCM wiederum über dieses Signal vom MSG einen Motorstart durchzuführen.";
CM_ SG_ 960 Klemmen_Status_01_BZ "4bit Botschaftszaehler; wird in jeder Sendebotschaft inkrementiert";
CM_ SG_ 960 Klemmen_Status_01_CRC "Für MLB:
'Berechnung siehe Lastenheft 'Kommunikationsabsicherung für FlexRay und CAN''

Ab MQB und MLBevo:
'Berechnung siehe Lastenheft 'End-to-End Kommunikationsabsicherung''

Endwerte siehe Begleitdokument 'S-PDU Kennungsfolgen'";
CM_ SG_ 960 KST_Fahrerhinweis_1 "Signalisierung Fahrerhinweis 1 der Klemmensteuerung an das Kombi";
CM_ SG_ 960 KST_Fahrerhinweis_2 "Signalisierung Fahrerhinweis 2 der Klemmensteuerung an das Kombi";
CM_ SG_ 960 KST_Fahrerhinweis_4 "Signalisierung Fahrerhinweis 4 der Klemmensteuerung an das Kombi";
CM_ SG_ 960 KST_Fahrerhinweis_5 "Anzeigesignal für RemoteStart";
CM_ SG_ 960 KST_Fahrerhinweis_6 "Signal aktiviert die Kombi-Anzeigeinstrumente (Drehzahl, Tankinhalt, Kühlmitteltemperatur) während aktiviertem RemoteStart-Betrieb";
CM_ SG_ 960 KST_Warn_P1_ZST_def "Kombi Prio Warnung Klemmensteuerung 
Zündschloß defekt, Service aufsuchen!";
CM_ SG_ 960 KST_Warn_P2_ZST_def "Kombi Prio Warnung Klemmensteuerung
Zündschloß defekt!
";
CM_ SG_ 960 RSt_Fahrerhinweise "Über das Signal fordert das BCM Fahrerhinweise im Kombi für die Funktion RemoteStart an.";
CM_ SG_ 960 ZAS_Kl_15 "Klemme 15: Zuendung (SW-Kl.15)
";
CM_ SG_ 960 ZAS_Kl_50_Startanforderung "Klemme 50: Startwunsch Fahrer
";
CM_ SG_ 960 ZAS_Kl_Infotainment "Separate Klemmeninformation für das Infotainment. Signal entspricht im wesentlichen einer Klemme S Information, kann aber über einen Vor - bzw. Nachlauf zu Klemme S verfügen. 
Ein konkreter Anwendungsfall für einen Nachlauf ist die Abschaltung der Klemme";
CM_ SG_ 960 ZAS_Kl_S "Klemme S: S-Kontakt (Schluessel steckt)
";
CM_ SG_ 960 ZAS_Kl_X "Klemme 75
";

CM_ SG_ 1646 KL_Anf_AussenspiegelHzg "Anforderung Außenspiegelheizung seitens Klimafunktion (z.B. bei Erweiterter VoKo)";
CM_ SG_ 1646 KL_BCmE_Livetip_Freigabe "Status der Klimaanlage. 
Zeigt an, ob der Livetip 'Fenster schließen wegen Ineffizienz Klimaanlage' sinvollerweise angezeigt werden soll";
CM_ SG_ 1646 KL_ErwVK_Anf "Erweiterte Voko angefordertert / aktiv";
CM_ SG_ 1646 KL_ErwVK_Zusatzrelais "Steuerung Zusatzrelais für Erweiterte Voko";
CM_ SG_ 1646 KL_FSH_Automatikbetrieb "Ermöglicht eine Unterscheidung von Anforderung FSH durch Kundenwunsch und Anforderung FSH durch Regelung des Klimasteuergeräts.
Das Signal liegt als Pegel an.";
CM_ SG_ 1646 KL_Geblaese_Fond_Status "Status Geblaese









";
CM_ SG_ 1646 KL_Geblaese_Status "Status Geblaese









";
CM_ SG_ 1646 KL_Heizkreisventilstellung "Bei MQB PHEV: Stellung Heizkreisventil Motor";
CM_ SG_ 1646 KL_HYB_ASV_hinten_schliessen_Anf "Anforderung der Klima an das BMS, das Absperrventil des Kältemittelkreislaufs zur Batteriekühlung zu schliessen";
CM_ SG_ 1646 KL_HYB_ASV_vorne_schliessen_Anf "Anforderung der Klima an das BMS, das Absperrventil des Kältemittelkreislaufs der Klimaanlage zu schliessen";
CM_ SG_ 1646 KL_I_Geblaese_Fond "Stromaufnahme Gebläse Heck";
CM_ SG_ 1646 KL_Innen_Temp "Innentemperatur

";
CM_ SG_ 1646 KL_Kompressorkupplung "Signal zur Aktivierung/Deaktivierung der Kompressorkupplung";
CM_ SG_ 1646 KL_Magnetventil "Anforderung des Bypassventils.";
CM_ SG_ 1646 KL_Restwaerme_aktiv "Signal zur Aktivierung/Deaktivierung der Wasserpumpe bei Restwärme; 
reduzierte IRÜ Empfindlichkeit";
CM_ SG_ 1646 KL_SIH_LEH_Verteilung_VL "Vom Kunden eingestellte Aufteilung der Heizleistung auf Sitzfläche und Lehnefläche für Sitz vorne links";
CM_ SG_ 1646 KL_SIH_LEH_Verteilung_VR "Vom Kunden eingestellte Aufteilung der Heizleistung auf Sitzfläche und Lehnefläche für Sitz vorne rechts";
CM_ SG_ 1646 KL_SIH_LEL_Verteilung_VL "Vom Kunden eingestellte Aufteilung der Lüftungsleistung auf Sitzfläche und Lehnenfläche für Sitz vorne links";
CM_ SG_ 1646 KL_SIH_LEL_Verteilung_VR "Vom Kunden eingestellte Aufteilung der Lüftungsleistung auf Sitzfläche und Lehnenfläche für Sitz vorne rechts";
CM_ SG_ 1646 KL_Solarluefter_aktiv "Betriebsstatus Solarluefter
";
CM_ SG_ 1646 KL_Status_Beduftung "Status der Beduftung";
CM_ SG_ 1646 KL_Status_Ionisator_Front "Status des Ionisator Front";
CM_ SG_ 1646 KL_STH_aktiv "Betriebsstatus Standheizung
";
CM_ SG_ 1646 KL_STH_Ansteuerung "Ansteuerung STH

";
CM_ SG_ 1646 KL_STH_Betriebsdauer "Betriebsdauer STH";
CM_ SG_ 1646 KL_STH_Timer_Status "Status des Standheizungstimers (für VW621 initial zur Übermittelung der Information von KlimaMSB zu Kombi)
Zur Anzeige im Kombi für 10 Sekunden nach Kl.15 aus;";
CM_ SG_ 1646 KL_STL_aktiv "Betriebsstatus Standlueftung
";
CM_ SG_ 1646 KL_Umluft_Taste "Betaetigung Umlufttaste
";
CM_ SG_ 1646 KL_WaPu "Ansteuerung der Standheizungswasserpumpe";

CM_ SG_ 1649 KL_Betriebsmodus_FH "Synchronisation des Betriebsmodus zwischen Front und Fond";
CM_ SG_ 1649 KL_Stopp_Wiederstart_Anz_01 "Dieses Signal gibt die detaillierte Begründung für eine Stoppverbot-/Wiederstartanfrage der Klima-SG an.";
CM_ SG_ 1649 KL_Stopp_Wiederstart_Anz_02 "Dieses Signal gibt die detaillierte Begründung für eine Stoppverbot-/Wiederstartanfrage der Klima-SG an.";
CM_ SG_ 1649 KL_Stopp_Wiederstart_Anz_03 "Dieses Signal gibt die detaillierte Begründung für eine Stoppverbot-/Wiederstartanfrage der Klima-SG an.";
CM_ SG_ 1649 KL_Stopp_Wiederstart_Anz_04 "Dieses Signal gibt die detaillierte Begründung für eine Stoppverbot-/Wiederstartanfrage der Klima-SG an.";
CM_ SG_ 1649 KL_Stopp_Wiederstart_Anz_05 "Dieses Signal gibt die detaillierte Begründung für eine Stoppverbot-/Wiederstartanfrage der Klima-SG an.";
CM_ SG_ 1649 KL_Stopp_Wiederstart_Anz_06 "Dieses Signal gibt die detaillierte Begründung für eine Stoppverbot-/Wiederstartanfrage der Klima-SG an.";
CM_ SG_ 1649 KL_Stopp_Wiederstart_Anz_07 "Dieses Signal gibt die detaillierte Begründung für eine Stoppverbot-/Wiederstartanfrage der Klima-SG an.";
CM_ SG_ 1649 KL_Stopp_Wiederstart_Anz_08 "Dieses Signal gibt die detaillierte Begründung für eine Stoppverbot-/Wiederstartanfrage der Klima-SG an.";
CM_ SG_ 1649 KL_Stopp_Wiederstart_Anz_09 "Dieses Signal gibt die detaillierte Begründung für eine Stoppverbot-/Wiederstartanfrage der Klima-SG an.";
CM_ SG_ 1649 KL_Stopp_Wiederstart_Anz_Std1 "Dieses Signal gibt die detaillierte Begründung für eine Stoppverbot-/Wiederstartanfrage der Klima-SG an.";
CM_ SG_ 1649 KL_Stopp_Wiederstart_Anz_Std2 "Dieses Signal gibt die detaillierte Begründung für eine Stoppverbot-/Wiederstartanfrage der Klima-SG an.";
CM_ SG_ 1649 KL_ZZ_Betriebsmodus "Betriebsdauerberechnung anhand Aussentemperaturauswertung mit Faktor 'ZZ_Betriebsmodus'";
CM_ SG_ 1649 KL_ZZ_Minute "Zielzeittimeranzeige im Display der Funkfernbedienung (Minute); Initwert ist der zuletzt gültige Wert";
CM_ SG_ 1649 KL_ZZ_Monat "Zielzeittimeranzeige im Display der Funkfernbedienung (Datum, Monat); Initwert ist der zuletzt gültige Wert";
CM_ SG_ 1649 KL_ZZ_Status_Timer "Timerstatusanzeige im Display der Funkfernbedienung (Timer aktiv/n.aktiv)";
CM_ SG_ 1649 KL_ZZ_Stunde "Zielzeittimeranzeige im Display der Funkfernbedienung (Stunde); Initwert ist der zuletzt gültige Wert";
CM_ SG_ 1649 KL_ZZ_Tag "Zielzeittimeranzeige im Display der Funkfernbedienung (Datum, Tag); Initwert ist der zuletzt gültige Wert";

CM_ SG_ 949 KL_AC_Schalter "AC Schalter
";
CM_ SG_ 949 KL_Anf_KL "Anforderung Kühlerlüfter der Klimaanlage in Prozent

";
CM_ SG_ 949 KL_Ausstattung_Klima "Austtattungsart der Klimabedienung";
CM_ SG_ 949 KL_Charisma_FahrPr "MLBevo: Aktuelles Fahrprogramm des Charisma-Teilnehmers (siehe Systemlastenheft Drive Select)
MQB: Istwert der Kennlinie (siehe Systemlastenheft MQB FPA)";
CM_ SG_ 949 KL_Charisma_Status "Charisma Systemstatus des Charisma-Teilnehmers

Wert 0x3 ist nur für Fahrzeuge ab MQB relevant";
CM_ SG_ 949 KL_Drehz_Anh "Drehzahlanhebung vom Motor angefordert

";
CM_ SG_ 949 KL_el_Zuheizer_Stufe "Vorgabe für Motorsteuergeraet PTC-Stufe; im MLB-B8 und MQB nur Stufe 0...3

";
CM_ SG_ 949 KL_Freilauf_Info "Freilauf Informationssignal von Klima zum Freilaufkoordinator. Klima kann über dieses Signal den Freilauf freigeben, verhindern bzw. explizit anfordern.";
CM_ SG_ 949 KL_Kompressorkupplung_linear "Sollwert zur Ansteuerung der Kompressorkupplung";
CM_ SG_ 949 KL_Last_Kompr "Aktuelles Verlustmoment der Klimaanlage bezogen auf die Kurbelwelle. Wird der Klimakompressor nicht angesteuert, ist das Schleppmoment bezogen auf die Kurbelwelle zu senden.";
CM_ SG_ 949 KL_nachtr_Stopp_Anf "Dieses Signal dient dem Motor als Trigger, dass ein nachträglicher Motorstopp eingeleitet werden kann, wenn es die Bedingungen des StSt Koordinators dies zulassen. ";
CM_ SG_ 949 KL_Spannungs_Anf "Forderung des Klima-SG's zur Spannungsanhebung.";
CM_ SG_ 949 KL_StartStopp_Info "Stopp-Freigabe und Start-Anforderung an den Start-Stopp-Koordinator";
CM_ SG_ 949 KL_T_Charge "Signal für Tastenbetätigung Charge-Taste (SOC Increasing)";
CM_ SG_ 949 KL_Thermomanagement "Stufen des Thermomanagements;
Bei Klemme 15 AUS und erkannten Timeout zum Klimabedienteil (z.B. Klimabedienteil während des Motorsteuergeräte-Kommunikations-Nachlaufs bereits im NM-Zustand ¿Bus Sleep¿)
erfolgt keine Ansteuerung der Wasserpumpe durch die";
CM_ SG_ 949 KL_Variante_Standheizung "Identifikation der Variante der Standheizungen zur Berechnung der energetischen Zielzeit";
CM_ SG_ 949 KL_Vorwarn_Komp_ein "Vorwarnung Kompressor ein; 140ms vorher; Information für Motor zum Aufbau Momentenreserve";
CM_ SG_ 949 KL_Vorwarn_Zuheizer_ein "Vorwarnung Zuheizerbetrieb
";
CM_ SG_ 949 KL_Zustand "Beschreibt den Zustand des Klima-/Heizungsbedienteils. (OFF-Mode Bedienteil)

PAG (MLB): Beschreibt den Zustand des Kompressors";

CM_ SG_ 1640 FSH_Taster "Tasterbetätigung Frontscheibenheizung
";
CM_ SG_ 1640 HSH_Taster "An-/Abforderung Heckscheibenheizung über spezielles Tastersignal
";
CM_ SG_ 1640 KL_Beschlagsgefahr "Beschlagsgefahr auf der Frontscheibe im Bereich des Spiegelfusses. Dient zur präventiven Ansteuerung der  Kamera-Scheibenheizung, um Kamera-Blindheit zu vermeiden
PHEV: volle Leistungsfreigabe 
HV Heizer und HV EKK bei Scheibenbeschlag ";
CM_ SG_ 1640 KL_Geblspng_Fond_Soll "Ausgabe des Sollwertes für die Spannung des Klimagebläsemotores hinten.






";
CM_ SG_ 1640 KL_Geblspng_Soll "Ausgabe des Sollwertes für die Spannung des Klimagebläsemotores vorne.







";
CM_ SG_ 1640 KL_I_Geblaese "Stromaufnahme Gebläse";
CM_ SG_ 1640 KL_Kompressorstrom_soll "Sollvorgabe Klima-Kompressorstrom";
CM_ SG_ 1640 KL_LRH_Stufe "Eingestellte Temperaturstufe der Lenkradheizung";
CM_ SG_ 1640 KL_LRH_Taster "Tasterbetätigung Lenkradheizung";
CM_ SG_ 1640 KL_PTC_Verbauinfo "Im Klima- bzw. Heizungsbedienteil wird der Verbau eines PTCs und dessen elektr. Leistungsklasse codiert";
CM_ SG_ 1640 KL_SIH_Soll_li "Einstellung Sitzheizung Fahrer (0...6)";
CM_ SG_ 1640 KL_SIH_Soll_re "Einstellung Sitzheizung Beifahrer (0...6)";
CM_ SG_ 1640 KL_SIL_Soll_li "Einstellung Sitzlüftung Fahrer (0...6)";
CM_ SG_ 1640 KL_SIL_Soll_re "Einstellung Sitzlüftung Beifahrer (0...6)";
CM_ SG_ 1640 KL_Umluftklappe_Status "Status Umluftklappe";
CM_ SG_ 1640 KL_Zuheizer_Freigabe "Freigabe Zuheizer
";
CM_ SG_ 1640 KRH_Soll_li "Ausgabe des Sollwertes für die Kopfraumheizung links.";
CM_ SG_ 1640 KRH_Soll_re "Ausgabe des Sollwertes für die Kopfraumheizung rechts.";

CM_ SG_ 1441 KL_Frischluftklappe_Status "Aktuelle Position der Frischluftklappe";
CM_ SG_ 1441 KL_PTC_linear_Anf "Kundenanforderung des PTC (linear)";
CM_ SG_ 1441 KL_SIH_LEH_Verteilung_HL "Vom Kunden eingestellte Aufteilung der Heizleistung auf Sitz und Lehne für Sitz hinten links";
CM_ SG_ 1441 KL_SIH_LEH_Verteilung_HR "Vom Kunden eingestellte Aufteilung der Heizleistung auf Sitz und Lehne für Sitz hinten rechts.";
CM_ SG_ 1441 KL_SIH_Stufe_hl "Eingestellte Sitzheizungsstufe hinten links für verteilte Komfortfunktionen";
CM_ SG_ 1441 KL_SIH_Stufe_hr "Eingestellte Sitzheizungsstufe hinten rechts für verteilte Komfortfunktionen";
CM_ SG_ 1441 KL_SIL_LEL_Verteilung_HL "Vom Kunden eingestellte Aufteilung der Lüftungsleistung auf Sitzfläche und Lehnenfläche für Sitz hinten links";
CM_ SG_ 1441 KL_SIL_LEL_Verteilung_HR "Vom Kunden eingestellte Aufteilung der Lüftungsleistung auf Sitzfläche und Lehnenfläche für Sitz hinten rechts";
CM_ SG_ 1441 KL_SIL_Stufe_hl "Eingestellte Sitzlüftungsstufe hinten links für verteilte Komfortfunktionen";
CM_ SG_ 1441 KL_SIL_Stufe_hr "Eingestellte Sitzlüftungsstufe hinten rechts für verteilte Komfortfunktionen";
CM_ SG_ 1441 KL_Temp_Soll_hl "Eingestellte Solltemperatur hinten links für verteilte Komfortfunktionen";
CM_ SG_ 1441 KL_Temp_Soll_hr "Eingestellte Solltemperatur hinten rechts für verteilte Komfortfunktionen";
CM_ SG_ 1441 KL_Temp_Soll_vl "Eingestellte Solltemperatur vorne links für verteilte Komfortfunktionen";
CM_ SG_ 1441 KL_Temp_Soll_vr "Eingestellte Solltemperatur vorne rechts für verteilte Komfortfunktionen";

CM_ SG_ 2589283469 KL_Geblaese_erw "Erwarteter Gebläsestatus im eingeschwungenen Zustand";
CM_ SG_ 2589283469 KL_Geblaese_Fond_erw "Erwarteter Fond-Gebläsestatus im eingeschwungenen Zustand";
CM_ SG_ 2589283469 KL_Heizlstg_Delta_Eingriff "Durch Kundeneingriff erwartete Veränderung der  Heizleistung bei aktuellen klimatischen Bedingungen";
CM_ SG_ 2589283469 KL_Kuehllstg_Delta_Eingriff "Durch Kundeneingriff erwartete Veränderung der  Kühlleistung bei aktuellen klimatischen Bedingungen";
CM_ SG_ 2589283469 KL_Tempklappe_Fond "Sollwert der Temperaturklappe Fond";
CM_ SG_ 2589283469 KL_Tempklappe_li "Sollwert der Temperaturklappe links (2 zonig)
Sollwert der Temperaturklappe (1-zonig)";
CM_ SG_ 2589283469 KL_Tempklappe_re "Sollwert der Temperaturklappe rechts";
CM_ SG_ 2589283469 KL_Verdampferleistung "Ist-Kühlleistung am Verdampfer
Bei KL_Verdampferleistung_Faktor = 1 wird der Signalwert mit dem Faktor 2 multipliziert.";
CM_ SG_ 2589283469 KL_Verdampferleistung_Faktor "Faktor für Signal KL_Verdampferleistung, 
Bei Signalwert 1 wird das Signal KL_Verdampferleistung mit dem Faktor 2 Multipliziert";
CM_ SG_ 2589283469 KL_VK_Anf "Starten einer Standklimatisierung ausgehend von der Climatronic Richtung Lademanagment.";
CM_ SG_ 2589283469 KL_Vorkond_Strategie "Strategie der Vorkonditionierung des Innenraums";

CM_ SG_ 2589283621 KL_ACmax_Aktiv "Funktion ACmax durch Kundeneingriff aktiviert";
CM_ SG_ 2589283621 KL_Defrost_Aktiv "Funktion Defrost durch Kundeneingriff aktiviert";
CM_ SG_ 2589283621 KL_ECO_Aktiv "Funktion Eco durch Kundeneingriff aktiviert";
CM_ SG_ 2589283621 KL_ECO_PRO_Aktiv "Funktion ECO-PRO durch Kundeneingriff aktiviert";
CM_ SG_ 2589283621 KL_Eps_Innen "mittlerer Wert der Klima Regelabweichung";
CM_ SG_ 2589283621 KL_FlHz_Soll_HL "Sollwertvorgabe für Flächenheizung hinten links";
CM_ SG_ 2589283621 KL_FlHz_Soll_HR "Sollwertvorgabe für Flächenheizung hinten rechts";
CM_ SG_ 2589283621 KL_FlHz_Soll_VL "Sollwertvorgabe für Flächenheizung vorne links";
CM_ SG_ 2589283621 KL_FlHz_Soll_VR "Sollwertvorgabe für Flächenheizung vorne rechts";
CM_ SG_ 2589283621 KL_Kundeneingriff_Geblaese "Manueller Kundeneingriff in die Geblaeseregelung";
CM_ SG_ 2589283621 KL_NV_Energie_Anf "Benötigte Energie (12V) für die Erweiterte Vorkonditionierung";
CM_ SG_ 2589283621 KL_QBit_Sonnenintensitaet "Gültigkeitsbit für Signal KL_Sonenintensität
Gesetzt bei Ersatzwert, Init oder Fehler.";
CM_ SG_ 2589283621 KL_Sonnenintensitaet "gemittelte eingestrahlte Leistung in W/m2";
CM_ SG_ 2589283621 KL_Status_Klimastil "Signal für aktuelles Programm des KBT";
CM_ SG_ 2589283621 KL_Thermischer_Bedarf "Temperierungsbedarf zur Innenraumklimatisierung";
CM_ SG_ 2589283621 KL_Umluft_Connect_status "Umluft Status zum Backend Server";
CM_ SG_ 2589283621 KL_ZR_Anforderung "Anforderung an MIB die Displays zu aktivieren";

CM_ SG_ 2463978701 KL_AC_Schalter_Prognose "Erwarteter Zustand des Klimakompressorwunschs bei einem Fahrprogramm-Wechsel";
CM_ SG_ 2463978701 KL_Leistungsreduktions_Hinweis "Signal zum Auslösen der Kombi-Meldung das bei einem Klima Defizit die Leistung der Klimatisierung reduziert wird.";
CM_ SG_ 2463978701 KL_Sollklimamodus_FPR_1 "Ziel Modus der Klimatisierung für ein definierbares Fahrprogramm.";
CM_ SG_ 2463978701 KL_Sollklimamodus_FPR_2 "Ziel Modus der Klimatisierung für ein definierbares Fahrprogramm.";
CM_ SG_ 2463978701 KL_Sollklimamodus_FPR_3 "Ziel Modus der Klimatisierung für ein definierbares Fahrprogramm.";
CM_ SG_ 2463978701 KL_Temp_Soll_hl_Prognose "Solltemperatur (Kundenwunsch) für die Prognose bei einem Fahrprogrammwechsel im BEV";
CM_ SG_ 2463978701 KL_Temp_Soll_hr_Prognose "Solltemperatur hinten rechts (Kundenwunsch) für die Prognose bei einem Fahrprogrammwechsel im BEV";
CM_ SG_ 2463978701 KL_Temp_Soll_vl_Prognose "Solltemperatur vorne links (Kundenwunsch) für die Prognose bei einem Fahrprogrammwechsel im BEV";
CM_ SG_ 2463978701 KL_Temp_Soll_vr_Prognose "Solltemperatur vorne rechts (Kundenwunsch) für die Prognose bei einem Fahrprogrammwechsel im BEV";

CM_ SG_ 1712 FS_Luftfeuchte_rel "gemessene relative Luftfeuchte";
CM_ SG_ 1712 FS_ResponseError "siehe LIN2.0-Specification
(Darf nicht über ein Fehlergueltigkeitsbit abgesichtert werden!)";
CM_ SG_ 1712 FS_Taupunkt "berechneter Taupunkt";
CM_ SG_ 1712 FS_Temp_Scheibe "gemessene Frontscheibentemperatur";
CM_ SG_ 1712 FS_Temp_Sensor "gemessene Sensortemperatur";

CM_ SG_ 1505 BCM1_Aussen_Temp_ungef "ungefilterter Wert des Aussentemperatursensors
";
CM_ SG_ 1505 BCM1_FStatus_Aussentemp_ungef "Fehlerstatus für Aussentemperatur (Kombianzeige)";
CM_ SG_ 1505 BCM1_Kompressorstrom_ist "IST-Strom vom Klima-Kompressor";
CM_ SG_ 1505 BCM1_OBD_FStatus_ATemp "Fehlerstatus Umgebungstemperatursensor (OBD relevanter Sensor)
";
CM_ SG_ 1505 BCM1_PTC_stufig_Status "Status des BCM1-Heizverbrauchers PTC (stufig)";
CM_ SG_ 1505 BCM_Heizungsabsperrventil_Status "Das Signal beschreibt den Zustand des Heizungsabsperrventils, welches als Portexpander vom BCM1 elektrisch angesteuert wird.";
CM_ SG_ 1505 BCM_Heizungspumpe_Status "Das Signal beschreibt den Zustand der Heizungspumpe, welche als Portexpander vom BCM1 elektrisch angesteuert wird.";
CM_ SG_ 1505 BCM_Kompressorkupplung_Status "Das Signal beschreibt den Zustand der Klimakompressorkupplung, welche als Portexpander vom BCM1 elektrisch angesteuert wird.";

CM_ SG_ 1717 FSA_Err_Defekt_HumSens_TNCTOC "OBD TestNotCompletedThisOperationCycle nach LIN LAH für Feuchteelement, testNotCompletedThisOperationCycle (TNCTOC)";
CM_ SG_ 1717 FSA_Err_Defekt_HumSense_TF "OBD TestFailed Flag, Statusbotschaft für Feuchtesensor außen, testFailed (TF)";
CM_ SG_ 1717 FSA_Err_Defekt_Tsens_TF "OBD TestFailed Flag, Statusbotschaft für diden Feuchtesensor, testFailed (TF)";
CM_ SG_ 1717 FSA_Err_RAMROM_Check_TF "OBD TestFailed Flag, Statusbotschaft für den Feuchtesensor, testFailed (TF)";
CM_ SG_ 1717 FSA_Err_RAMROM_Check_TNCTOC "Signal meldet den Status der Diagnosen nach OBD LIN-LAH, testNotCompletedThisOperationCycle (TNCTOC)";
CM_ SG_ 1717 FSA_Err_Ueberspannung_TF "OBD TestFailed Flag, Statusbotschaft für den Feuchtesensor Außen, testFailed (TF)";
CM_ SG_ 1717 FSA_Err_Unterspannung_TF "OBD TestFailed Flag, Statusbotschaft für den Feuchtesensor, testFailed (TF)";
CM_ SG_ 1717 FSA_ErrMemState "OBD Signal statusbotschaft für den Feuchtesensor außen";
CM_ SG_ 1717 FSA_HW "Hardwarestand";
CM_ SG_ 1717 FSA_Lokal_Bus_elektr_Fehler "Bit wird gesetzt, wenn fuer lokaler Datenbus elektr. Fehler eingetragen wird";
CM_ SG_ 1717 FSA_Lokal_Bus_Unterbrechung "Bit wird gesetzt, wenn fuer lokaler Datenbus DTC wegen Unterbrechung eingetragen wird";
CM_ SG_ 1717 FSA_Luftfeuchte_rel "Maximaler Feuchtebereich bis 126% für theoretisch errechnete Feuchtewerte des Sensors. Signalwerte >100% bedeuten  rel. Feuchte = 100%";
CM_ SG_ 1717 FSA_Luftfeuchte_TF "OBD TestFailed Flag, Statusbotschaft für den Feuchtesensor, testFailed (TF)";
CM_ SG_ 1717 FSA_Luftfeuchte_TNCTOC "Signal meldet den Status der Diagnosen nach OBD LIN-LAH, testNotCompletedThisOperationCycle (TNCTOC)";
CM_ SG_ 1717 FSA_ResponseError "siehe LIN2.0-Specification
(Darf nicht über ein Fehlergueltigkeitsbit abgesichtert werden!)";
CM_ SG_ 1717 FSA_Sensorheizung_Status "Status der Heizung im Feuchteelement (z.B. SHT10).
0 (=inaktiv) auch bei nicht verbaut";
CM_ SG_ 1717 FSA_SW "Softwarestand";
CM_ SG_ 1717 FSA_Taupunkt "'Init' falls nicht verbaut";
CM_ SG_ 1717 FSA_Temp_Luft "gemessene Temperatur im Luftstrom (z.B. NTC am Sensor)
'Init' falls nicht verbaut
(+61°C bedeutet: Temp_Luft > 60,9°C !)";
CM_ SG_ 1717 FSA_Timeout "Bit wird gesetzt, wenn Time-Out DTC eingetragen wird";

CM_ SG_ 1513 AAU_Geblaese "Ansteuergrad des Gebläses";
CM_ SG_ 1513 DS_Kaeltemittel_P "Drucksensor Kältemittel Druck, das Signal wird bei Kl.15 AUS mit dem letzten empfangenen Wert gesendet";
CM_ SG_ 1513 DS_Status "Status des Drucksensors (= LIN-Slave BCM1);
bei Kl.15 AUS wird für 4s noch der letzte Wert gesendet, danach wird das Signal mit dem Wert 3 (= Fehler) gesendet";
CM_ SG_ 1513 ION_Status "Status Hochspannung Ionisator";
CM_ SG_ 1513 ION_Status_LED "Status Funktions LED";
CM_ SG_ 1513 ION_Status_Taster "Status Kundenwunsch (Bedientaster) Ionisator";

CM_ SG_ 1295 KL_Heizbedarf "Bedarf an Heizmenge für Innenraumklimatisierung";
CM_ SG_ 1295 KL_Heizenergie_instat_pred "Erwartete thermische Energie für den instationären Heizbetrieb bis zum Übergang in den stationären Betrieb";
CM_ SG_ 1295 KL_Heizleistg_stat_erw "Erwartete thermische Heizleistungsaufnahme für den stationären Klimabetrieb bei aktuellen klimatischen Bedingungen";
CM_ SG_ 1295 KL_Kuehlbedarf "Bedarf an Kühlmenge für Innenraumklimatisierung";
CM_ SG_ 1295 KL_Kuehlenergie_instat_pred "Erwartete thermische Energie für den instationären Kühlbetrieb bis zum Übergang in den stationären Betrieb";
CM_ SG_ 1295 KL_Kuehlleistg_stat_erw "Erwartete thermische Kühlleistungsaufnahme für den stationären Klimabetrieb bei aktuellen klimatischen Bedingungen";
CM_ SG_ 1295 KL_Leistungspriorisierung "Priorisierungsvorgaben";
CM_ SG_ 1295 KL_PTC_ein "PTC Aus/Ein";
CM_ SG_ 1295 KL_Verdampfertemperatur "Istwert der Verdampfertemperatur";

CM_ SG_ 2589283474 KL_Eps_Innen "mittlerer Wert der Klima Regelabweichung";
CM_ SG_ 2589283474 KL_MMTR "Signal zum TME-SG zur Aktivierung der Funktion Make me track ready";
CM_ SG_ 2589283474 KL_MMTR_Status "Status der Funktion Make me track ready";
CM_ SG_ 2589283474 KL_Temp_vor_Verdampfer "Ist Lufttemperatur vor Verdampfer";
CM_ SG_ 2589283474 KL_Tempklappe_Fond_li "Sollwert der Temperaturklappe Fond links";
CM_ SG_ 2589283474 KL_Tempklappe_Fond_re "Sollwert der Temperaturklappe Fond rechts";

CM_ SG_ 2463978659 KMP_Ist_Drehzahl "Ist- Drehzahl der Kühlmittelpumpe";
CM_ SG_ 2463978659 KMP_Ist_Spannung "Spannung HV am der Kühlmittelpumpe";
CM_ SG_ 2463978659 KMP_Ist_Strom "Ist- Stromaufnahme der Kühlmittelpumpe auf HV Leitung";
CM_ SG_ 2463978659 KMP_IstModus "Istmodus der Kühlmittelpumpe, gesendet von der KMP";
CM_ SG_ 2463978659 KMP_Status_Spgfreiheit "Status der HV-Spannungsfreiheitserfassungsfunktion in der LE der KMP";

CM_ SG_ 2549088399 AWC_Abschaltstufe "Funktionseinschraenkung aufgrund aktiver Abschaltstufe";
CM_ SG_ 2549088399 AWC_KD_Fehler "Bei gesetztem Bit ist mindestens ein Kundendienstfehler eingetragen";
CM_ SG_ 2549088399 AWC_KompSchutz "Funktionseinschraenkung aufgrund Komponentenschutz aktiv";
CM_ SG_ 2549088399 AWC_Lokalaktiv "Zeigt an ob das SG nach Klemme15 AUS und nach entsprechender MAX Aktivzeit noch aktiv war";
CM_ SG_ 2549088399 AWC_Nachlauftyp "Abgebildet wird die von der Hardware vorgegebene Möglichkeit, die Kommunikation nach Klemme 15 = AUS aufrecht zu erhalten. Es wird ein Init-Wert gesendet.";
CM_ SG_ 2549088399 AWC_SNI "Das Signal beinhaltet den Source Node Identifier (Knotenadresse, die auch in der Abbildungsvorschrift zur CAN-ID für die NM-High Botschaft verwendet wird).";
CM_ SG_ 2549088399 AWC_Subsystemaktiv "Zeigt an ob ein Subsystem des SGs nach Klemme15 AUS und nach entsprechender MAX Aktivzeit noch aktiv war";
CM_ SG_ 2549088399 AWC_Transport_Mode "Funktionseinschränkung aufgrund aktivem Transport Mode und/ oder Transport Schutz";
CM_ SG_ 2549088399 KN_AWC_BusKnockOut "Ausgabe des BusKnockout-Status";
CM_ SG_ 2549088399 KN_AWC_BusKnockOutTimer "Ausgabe des BusKnockOut-Timer";
CM_ SG_ 2549088399 KN_AWC_ECUKnockOut "Ausgabe des ECUKnockout-Status";
CM_ SG_ 2549088399 KN_AWC_ECUKnockOutTimer "Ausgabe des ECUKnockOut-Timer";
CM_ SG_ 2549088399 NM_AWC_Wakeup "enthält die Weckursache; stehen mehrere Weckursachen parallel an, dann muss der kleinste Wert übertragen werden";

CM_ SG_ 2549088430 BattRegelung_Abschaltstufe "Funktionseinschränkung aufgrund aktiver Abschaltstufe";
CM_ SG_ 2549088430 BattRegelung_KD_Fehler "Bei gesetztem Bit ist mindestens ein Kundendienstfehler eingetragen";
CM_ SG_ 2549088430 BattRegelung_KompSchutz "Funktionseinschränkung aufgrund Komponentenschutz aktiv";
CM_ SG_ 2549088430 BattRegelung_Nachlauftyp "Abgebildet wird die von der Hardware vorgegebene Möglichkeit, die Kommunikation nach Klemme 15 = AUS aufrecht zu erhalten. Es wird ein Init-Wert gesendet.";
CM_ SG_ 2549088430 BattRegelung_SNI "Das Signal beinhaltet den Source Node Identifier (Knotenadresse, die auch in der Abbildungsvorschrift zur CAN-ID für die NM-High Botschaft verwendet wird).";
CM_ SG_ 2549088430 BattRegelung_Transport_Mode "Funktionseinschränkung aufgrund aktivem Transport Mode und/oder Transport Schutz";
CM_ SG_ 2549088430 BMS_NV_Lokalaktiv "Zeigt an ob das SG nach Klemme15 AUS und nach entsprechender MAX Aktivzeit noch aktiv war. LAH.DUM.907.T.1_Abschaltungen Ruhestrommgm MLBevo";
CM_ SG_ 2549088430 NM_Battregelung_Wakeup "enthält die Weckursache; stehen mehrere Weckursachen parallel an, dann muss der kleinste Wert übertragen werden";

CM_ SG_ 2549088412 BMS_MV_Abschaltstufe "Funktionseinschränkung aufgrund aktiver Abschaltstufe";
CM_ SG_ 2549088412 BMS_MV_KD_Fehler "Bei gesetztem Bit ist mindestens ein Kundendienstfehler eingetragen";
CM_ SG_ 2549088412 BMS_MV_KompSchutz "Funktionseinschränkung aufgrund Komponentenschutz aktiv";
CM_ SG_ 2549088412 BMS_MV_Lokalaktiv "Zeigt an ob das SG nach Klemme15 AUS und nach entsprechender MAX Aktivzeit noch aktiv war";
CM_ SG_ 2549088412 BMS_MV_Nachlauftyp "Abgebildet wird die von der Hardware vorgegebene Möglichkeit, die Kommunikation nach Klemme 15 = AUS aufrecht zu erhalten. Es wird ein Init-Wert gesendet.
0 = Kommunikation nur bei KL15=EIN (kein Nachlauf, nicht weckfähig)
1 = Kommunikation nach KL15=AU";
CM_ SG_ 2549088412 BMS_MV_SNI "Das Signal beinhaltet den Source Node Identifier (Knotenadresse, die auch in der Abbildungsvorschrift zur CAN-ID für die NM-High Botschaft verwendet wird).";
CM_ SG_ 2549088412 BMS_MV_Subsystemaktiv "Zeigt an ob ein Subsystem des SGs nach Klemme15 AUS und nach entsprechender MAX Aktivzeit noch aktiv war";
CM_ SG_ 2549088412 BMS_MV_Transport_Mode "Funktionseinschränkung aufgrund aktivem Transport Mode und/oder Transport Schutz";
CM_ SG_ 2549088412 NM_BMS_MV_Wakeup "enthält die Weckursache; stehen mehrere Weckursachen parallel an, dann muss der kleinste Wert übertragen werden";

CM_ SG_ 2549088321 DCDC_Abschaltstufe "Funktionseinschränkung aufgrund aktiver Abschaltstufe";
CM_ SG_ 2549088321 DCDC_KD_Fehler "Bei gesetztem Bit ist mindestens ein Kundendienstfehler eingetragen";
CM_ SG_ 2549088321 DCDC_KompSchutz "Funktionseinschränkung aufgrund Komponentenschutz aktiv";
CM_ SG_ 2549088321 DCDC_Nachlauftyp "Abgebildet wird die von der Hardware vorgegebene Möglichkeit, die Kommunikation nach Klemme 15 = AUS aufrecht zu erhalten. Es wird ein Init-Wert gesendet.";
CM_ SG_ 2549088321 DCDC_SNI "Das Signal beinhaltet den Source Node Identifier (Knotenadresse, die auch in der Abbildungsvorschrift zur CAN-ID für die NM-High Botschaft verwendet wird).";
CM_ SG_ 2549088321 DCDC_Transport_Mode "Funktionseinschränkung aufgrund aktivem Transport Mode und/oder Transport Schutz";
CM_ SG_ 2549088321 KN_DCDC_BusKnockOutTimer "Ausgabe des BusKnockOut-Timer";
CM_ SG_ 2549088321 NM_DCDC_Wakeup "enthält die Weckursache; stehen mehrere Weckursachen parallel an, dann muss der kleinste Wert übertragen werden";
CM_ SG_ 2549088321 NMH_DCDC_Lokalaktiv "Zeigt an ob Steuergerät lokal aktiv war";
CM_ SG_ 2549088321 NMH_DCDC_Subsystemaktiv "Zeigt an ob ein Subsystem des SGs nach Klemme15 AUS und nach entsprechender MAX Aktivzeit noch aktiv war";

CM_ SG_ 2549088439 DCDC_HV_Abschaltstufe "Funktionseinschraenkung aufgrund aktiver Abschaltstufe";
CM_ SG_ 2549088439 DCDC_HV_BusKnockOut "Ausgabe des BusKnockout-Status in der Knotenbotschaft";
CM_ SG_ 2549088439 DCDC_HV_BusKnockOutTimer "Ausgabe des BusKnockOut-Timer in der Knotenbotschaft";
CM_ SG_ 2549088439 DCDC_HV_ECUKnockOut "Ausgabe des ECUKnockout-Status in der Knotenbotschaft";
CM_ SG_ 2549088439 DCDC_HV_ECUKnockOutTimer "Ausgabe des ECUKnockOut-Timer in der Knotenbotschaft";
CM_ SG_ 2549088439 DCDC_HV_KD_Fehler "Bei gesetztem Bit ist mindestens ein Kundendienstfehler eingetragen";
CM_ SG_ 2549088439 DCDC_HV_KompSchutz "Funktionseinschraenkung aufgrund Komponentenschutz aktiv";
CM_ SG_ 2549088439 DCDC_HV_Lokalaktiv "Zeigt an ob das SG nach Klemme15 AUS und nach entsprechender MAX Aktivzeit noch aktiv war.";
CM_ SG_ 2549088439 DCDC_HV_Nachlauftyp "Abgebildet wird die von der Hardware vorgegebene Möglichkeit, die Kommunikation nach Klemme 15 = AUS aufrecht zu erhalten. Es wird ein Init-Wert gesendet.";
CM_ SG_ 2549088439 DCDC_HV_SNI "Source Node-Identifier (SNI) identifiziert den Sender der NM-Botschaft (Knotenadresse) eindeutig im Fahrzeug";
CM_ SG_ 2549088439 DCDC_HV_Transport_Mode "Funktionseinschraenkung aufgrund aktivem Transport Mode und/oder Transport Schutz";
CM_ SG_ 2549088439 NM_DCDC_HV_Wakeup "enthaelt die Weckursache; stehen mehrere Weckursachen parallel an, dann muss der kleinste Wert übertragen werden";

CM_ SG_ 2549088455 DCDC_HV_02_Abschaltstufe "Funktionseinschränkung aufgrund aktiver Abschaltstufe";
CM_ SG_ 2549088455 DCDC_HV_02_KD_Fehler "Bei gesetztem Bit ist mindestens ein Kundendienstfehler eingetragen";
CM_ SG_ 2549088455 DCDC_HV_02_KompSchutz "Funktionseinschränkung aufgrund Komponentenschutz aktiv";
CM_ SG_ 2549088455 DCDC_HV_02_Nachlauftyp "Abgebildet wird die von der Hardware vorgegebene Möglichkeit, die Kommunikation nach Klemme 15 = AUS aufrecht zu erhalten. Es wird ein Init-Wert gesendet.
0 = Kommunikation nur bei KL15=EIN (kein Nachlauf, nicht weckfähig)
1 = Kommunikation nach KL15=AU";
CM_ SG_ 2549088455 DCDC_HV_02_SNI "Source Node-Identifier (SNI) identifiziert den Sender der NM-Botschaft (Knotenadresse) eindeutig im Fahrzeug";
CM_ SG_ 2549088455 DCDC_HV_02_Transport_Mode "Funktionseinschränkung aufgrund aktivem Transport Mode und/oder Transport Schutz";
CM_ SG_ 2549088455 KN_DCDC_HV_02_BusKnockOut "Ausgabe des BusKnockout-Status in der Knotenbotschaft";
CM_ SG_ 2549088455 KN_DCDC_HV_02_BusKnockOutTimer "Ausgabe des BusKnockOut-Timer in der Knotenbotschaft";
CM_ SG_ 2549088455 KN_DCDC_HV_02_ECUKnockOut "Ausgabe des ECUKnockout-Status in der Knotenbotschaft";
CM_ SG_ 2549088455 KN_DCDC_HV_02_ECUKnockOutTimer "Ausgabe des ECUKnockOut-Timer in der Knotenbotschaft";
CM_ SG_ 2549088455 NM_DCDC_HV_02_Lokalaktiv "Zeigt an ob das SG nach Klemme15 AUS und nach entsprechender MAX Aktivzeit noch aktiv war.";
CM_ SG_ 2549088455 NM_DCDC_HV_02_Wakeup "enthält die Weckursache; stehen mehrere Weckursachen parallel an, dann muss der kleinste Wert übertragen werden";

CM_ SG_ 2549088437 FCU_Abschaltstufe "Funktionseinschränkung aufgrund aktiver Abschaltstufe";
CM_ SG_ 2549088437 FCU_KD_Fehler "Bei gesetztem Bit ist mindestens ein Kundendienstfehler eingetragen";
CM_ SG_ 2549088437 FCU_KompSchutz "Funktionseinschränkung aufgrund Komponentenschutz aktiv";
CM_ SG_ 2549088437 FCU_Nachlauftyp "Abgebildet wird die von der Hardware vorgegebene Möglichkeit, die Kommunikation nach Klemme 15 = AUS aufrecht zu erhalten. Es wird ein Init-Wert gesendet.
0 = Kommunikation nur bei KL15=EIN (kein Nachlauf, nicht weckfähig)
1 = Kommunikation nach KL15=AU";
CM_ SG_ 2549088437 FCU_SNI "Source Node-Identifier (SNI) identifiziert den Sender der NM-Botschaft (Knotenadresse) eindeutig im Fahrzeug";
CM_ SG_ 2549088437 FCU_Transport_Mode "Funktionseinschränkung aufgrund aktivem Transport Mode und/oder Transport Schutz";
CM_ SG_ 2549088437 KN_FCU_BusKnockOut "Ausgabe des BusKnockout-Status in der Knotenbotschaft";
CM_ SG_ 2549088437 KN_FCU_BusKnockOutTimer "Ausgabe des BusKnockOut-Timer in der Knotenbotschaft";
CM_ SG_ 2549088437 KN_FCU_DiagPfad "Kennzeichnung der Diagnosefähigkeit des BusInterfaces eines Steuergerätes (Knoten)
Umfang LAH 80127

Bei Nutzung des Signal explizit pro angebundenem BusInterface zu setzen:
MQB auf A-CAN = 0 (aktiv)";
CM_ SG_ 2549088437 KN_FCU_ECUKnockOut "Ausgabe des ECUKnockout-Status in der Knotenbotschaft";
CM_ SG_ 2549088437 KN_FCU_ECUKnockOutTimer "Ausgabe des ECUKnockOut-Timer in der Knotenbotschaft";
CM_ SG_ 2549088437 NM_FCU_Lokalaktiv "Zeigt an ob Steuergerät bei Kl15 aus dauerhaft lokal aktiv war, siehe QLAH Abschaltungen Ruhestrommanagement";
CM_ SG_ 2549088437 NM_FCU_Subsystemaktiv "Zeigt an ob Steuergerät bei Kl15 aus dauerhaft lokal aktiv war, siehe QLAH Abschaltungen Ruhestrommanagement";
CM_ SG_ 2549088437 NM_FCU_Wakeup "enthält die Weckursache; stehen mehrere Weckursachen parallel an, dann muss der kleinste Wert übertragen werden";

CM_ SG_ 2549088272 Gateway_Abschaltstufe "Funktionseinschränkung aufgrund aktiver Abschaltstufe";
CM_ SG_ 2549088272 Gateway_KompSchutz "Funktionseinschränkung aufgrund Komponentenschutz aktiv";
CM_ SG_ 2549088272 Gateway_Matrix_Generation "Signal gibt an welche Matrix-Generation umgesetzt ist";
CM_ SG_ 2549088272 Gateway_Matrix_Version "Signal gibt an welche Matrix-Version des Baukasten umgesetzt ist.
z.B. V.08.xx, das Signal gibt den Wert für xx an";
CM_ SG_ 2549088272 Gateway_Nachlauftyp "Abgebildet wird die von der Hardware vorgegebene Möglichkeit, die Kommunikation nach Klemme 15 = AUS aufrecht zu erhalten. Es wird ein Init-Wert gesendet.";
CM_ SG_ 2549088272 Gateway_SNI "Das Signal beinhaltet den Source Node Identifier (Knotenadresse, die auch in der Abbildungsvorschrift zur CAN-ID für die NM-High Botschaft verwendet wird).";
CM_ SG_ 2549088272 Gateway_Transport_Mode "Funktionseinschränkung aufgrund aktivem Transport Mode und/oder Transport Schutz";
CM_ SG_ 2549088272 GW_KD_Fehler "Kundendienstfehlerbit Gateway zur Anzeige eines im Gateway abgelegten Fehlerspeichereintrages.";
CM_ SG_ 2549088272 NM_Gateway_Lokalaktiv "Zeigt an ob das SG nach Klemme15 AUS und nach entsprechender MAX Aktivzeit noch aktiv war.";
CM_ SG_ 2549088272 NM_Gateway_Subsystemaktiv "Zeigt an ob ein Subsystem des SGs nach Klemme15 AUS und nach entsprechender MAX Aktivzeit noch aktiv war";
CM_ SG_ 2549088272 NM_Gateway_Wakeup "enthält die Weckursache; stehen mehrere Weckursachen parallel an, dann muss der kleinste Wert übertragen werden";

CM_ SG_ 2549088379 BMS_HYB_KD_Fehler "Bei gesetztem Bit ist mindestens ein Kundendienstfehler eingetragen";
CM_ SG_ 2549088379 Hybrid_01_Abschaltstufe "Funktionseinschränkung aufgrund aktiver Abschaltstufe";
CM_ SG_ 2549088379 Hybrid_01_Lokalaktiv "Zeigt an ob das SG nach Klemme15 AUS und nach entsprechender MAX Aktivzeit noch aktiv war";
CM_ SG_ 2549088379 Hybrid_01_SNI "Das Signal beinhaltet den Source Node Identifier (Knotenadresse, die auch in der Abbildungsvorschrift zur CAN-ID für die NM-High Botschaft verwendet wird).";
CM_ SG_ 2549088379 Hybrid_01_Subsystemaktiv "Zeigt an ob ein Subsystem des SGs nach Klemme15 AUS und nach entsprechender MAX Aktivzeit noch aktiv war";
CM_ SG_ 2549088379 Hybrid_01_Transport_Mode "Funktionseinschränkung aufgrund aktivem Transport Mode und/oder Transport Schutz";
CM_ SG_ 2549088379 Hybrid_KompSchutz "Funktionseinschränkung aufgrund Komponentenschutz aktiv";
CM_ SG_ 2549088379 Hybrid_Nachlauftyp "Abgebildet wird die von der Hardware vorgegebene Möglichkeit, die Kommunikation nach Klemme 15 = AUS aufrecht zu erhalten. Es wird ein Init-Wert gesendet.
0 = Kommunikation nur bei KL15=EIN (kein Nachlauf, nicht weckfähig)
1 = Kommunikation nach KL15=AU";
CM_ SG_ 2549088379 KN_BMS_BusKnockOut "Ausgabe des BusKnockOut-Status in der Knotenbotschaft";
CM_ SG_ 2549088379 KN_BMS_BusKnockOutTimer "Ausgabe des BusKnockOut-Timer in der Knotenbotschaft";
CM_ SG_ 2549088379 KN_BMS_ECUKnockOut "Ausgabe des ECUKnockOut-Status in der Knotenbotschaft";
CM_ SG_ 2549088379 KN_BMS_ECUKnockOutTimer "Ausgabe des ECUKnockOut-Timer in der Knotenbotschaft";
CM_ SG_ 2549088379 NM_Hybrid_01_Wakeup "enthält die Weckursache; stehen mehrere Weckursachen parallel an, dann muss der kleinste Wert übertragen werden";

CM_ SG_ 2549088324 KN_Ladegeraet_BusKnockOut "Ausgabe des BusKnockout-Status in der Knotenbotschaft";
CM_ SG_ 2549088324 KN_Ladegeraet_BusKnockOutTimer "Ausgabe des BusKnockOut-Timer in der Knotenbotschaft";
CM_ SG_ 2549088324 KN_Ladegeraet_ECUKnockOut "Ausgabe des ECUKnockout-Status in der Knotenbotschaft";
CM_ SG_ 2549088324 KN_Ladegeraet_ECUKnockOutTimer "Ausgabe des ECUKnockOut-Timer in der Knotenbotschaft";
CM_ SG_ 2549088324 LG_Abschaltstufe "Funktionseinschränkung aufgrund aktiver Abschaltstufe";
CM_ SG_ 2549088324 LG_KD_Fehler "Bei gesetztem Bit ist mindestens ein Kundendienstfehler eingetragen";
CM_ SG_ 2549088324 LG_KompSchutz "Funktionseinschränkung aufgrund Komponentenschutz aktiv";
CM_ SG_ 2549088324 LG_Nachlauftyp "Abgebildet wird die von der Hardware vorgegebene Möglichkeit, die Kommunikation nach Klemme 15 = AUS aufrecht zu erhalten. Es wird ein Init-Wert gesendet.
0 = Kommunikation nur bei KL15=EIN (kein Nachlauf, nicht weckfähig)
1 = Kommunikation nach KL15=AU";
CM_ SG_ 2549088324 LG_SNI "Das Signal beinhaltet den Source Node Identifier (Knotenadresse, die auch in der Abbildungsvorschrift zur CAN-ID für die NM-High Botschaft verwendet wird).";
CM_ SG_ 2549088324 LG_Transport_Mode "Funktionseinschränkung aufgrund aktivem Transport Mode und/oder Transport Schutz";
CM_ SG_ 2549088324 NM_Ladegeraet_Wakeup "enthält die Weckursache; stehen mehrere Weckursachen parallel an, dann muss der kleinste Wert übertragen werden";
CM_ SG_ 2549088324 NMH_Ladegeraet_Lokalaktiv "Zeigt an ob Steuergerät lokal aktiv war";
CM_ SG_ 2549088324 NMH_Ladegeraet_Subsystemaktiv "Zeigt an ob ein Subsystem des SGs nach Klemme15 AUS und nach entsprechender MAX Aktivzeit noch aktiv war";

CM_ SG_ 2549088454 KN_Ladegeraet_2_BusKnockOut "Ausgabe des BusKnockout-Status in der Knotenbotschaft";
CM_ SG_ 2549088454 KN_Ladegeraet_2_BusKnockOutTimer "Ausgabe des BusKnockOut-Timer in der Knotenbotschaft";
CM_ SG_ 2549088454 KN_Ladegeraet_2_ECUKnockOut "Ausgabe des ECUKnockout-Status in der Knotenbotschaft";
CM_ SG_ 2549088454 KN_Ladegeraet_2_ECUKnockOutTimer "Ausgabe des ECUKnockOut-Timer in der Knotenbotschaft";
CM_ SG_ 2549088454 Ladegeraet2_KD_Fehler "Bei gesetztem Bit ist mindestens ein Kundendienstfehler eingetragen";
CM_ SG_ 2549088454 Ladegeraet_2_Abschaltstufe "Funktionseinschränkung aufgrund aktiver Abschaltstufe";
CM_ SG_ 2549088454 Ladegeraet_2_KompSchutz "Funktionseinschränkung aufgrund Komponentenschutz aktiv";
CM_ SG_ 2549088454 Ladegeraet_2_Nachlauftyp "Abgebildet wird die von der Hardware vorgegebene Möglichkeit, die Kommunikation nach Klemme 15 = AUS aufrecht zu erhalten. Es wird ein Init-Wert gesendet.
0 = Kommunikation nur bei KL15=EIN (kein Nachlauf, nicht weckfähig)
1 = Kommunikation nach KL15=AU";
CM_ SG_ 2549088454 Ladegeraet_2_SNI "Source Node-Identifier (SNI) identifiziert den Sender der NM-Botschaft (Knotenadresse) eindeutig im Fahrzeug";
CM_ SG_ 2549088454 Ladegeraet_2_Transport_Mode "Funktionseinschränkung aufgrund aktivem Transport Mode und/oder Transport Schutz";
CM_ SG_ 2549088454 NM_Ladegeraet_2_Lokalaktiv "Zeigt an ob das SG nach Klemme15 AUS und nach entsprechender MAX Aktivzeit noch aktiv war.";
CM_ SG_ 2549088454 NM_Ladegeraet_2_Wakeup "enthält die Weckursache; stehen mehrere Weckursachen parallel an, dann muss der kleinste Wert übertragen werden";

CM_ SG_ 2549088257 KN_Sekundaer_01_BusKnockOut "Ausgabe des BusKnockout-Status in der Knotenbotschaft";
CM_ SG_ 2549088257 KN_Sekundaer_01_BusKnockOutTimer "Ausgabe des BusKnockOut-Timer in der Knotenbotschaft";
CM_ SG_ 2549088257 KN_Sekundaer_01_ECUKnockOut "Ausgabe des ECUKnockout-Status in der Knotenbotschaft";
CM_ SG_ 2549088257 KN_Sekundaer_01_ECUKnockOutTimer "Ausgabe des ECUKnockOut-Timer in der Knotenbotschaft";
CM_ SG_ 2549088257 NM_Sekundaer_01_Lokalaktiv "Zeigt an ob das SG nach Klemme15 AUS und nach entsprechender MAX Aktivzeit noch aktiv war";
CM_ SG_ 2549088257 NM_Sekundaer_01_Wakeup "enthält die Weckursache; stehen mehrere Weckursachen parallel an, dann muss der kleinste Wert übertragen werden";
CM_ SG_ 2549088257 Sekundaer_01_Abschaltstufe "Funktionseinschränkung aufgrund aktiver Abschaltstufe";
CM_ SG_ 2549088257 Sekundaer_01_KD_Fehler "Status Kundendienst-Fehlerspeicher";
CM_ SG_ 2549088257 Sekundaer_01_KompSchutz "Funktionseinschränkung aufgrund Komponentenschutz aktiv";
CM_ SG_ 2549088257 Sekundaer_01_Nachlauftyp "Abgebildet wird die von der Hardware vorgegebene Möglichkeit, die Kommunikation nach Klemme 15 = AUS aufrecht zu erhalten. Es wird ein Init-Wert gesendet.
0 = Kommunikation nur bei KL15=EIN (kein Nachlauf, nicht weckfähig)
1 = Kommunikation nach KL15=AU";
CM_ SG_ 2549088257 Sekundaer_01_SNI "Das Signal beinhaltet den Source Node Identifier (Knotenadresse, die auch in der Abbildungsvorschrift zur CAN-ID für die NM-High Botschaft verwendet wird).";
CM_ SG_ 2549088257 Sekundaer_01_Transport_Mode "Funktionseinschränkung aufgrund aktivem Transport Mode und/oder Transport Schutz";

CM_ SG_ 2549088259 KN_Sekundaer_03_BusKnockOut "Ausgabe des BusKnockout-Status in der Knotenbotschaft";
CM_ SG_ 2549088259 KN_Sekundaer_03_BusKnockOutTimer "Ausgabe des BusKnockOut-Timer in der Knotenbotschaft";
CM_ SG_ 2549088259 KN_Sekundaer_03_ECUKnockOut "Ausgabe des ECUKnockout-Status in der Knotenbotschaft";
CM_ SG_ 2549088259 KN_Sekundaer_03_ECUKnockOutTimer "Ausgabe des ECUKnockOut-Timer in der Knotenbotschaft";
CM_ SG_ 2549088259 Sekundaer_03_Abschaltstufe "Funktionseinschränkung aufgrund aktiver Abschaltstufe";
CM_ SG_ 2549088259 Sekundaer_03_KD_Fehler "Status Kundendienst-Fehlerspeicher";
CM_ SG_ 2549088259 Sekundaer_03_KompSchutz "Funktionseinschränkung aufgrund Komponentenschutz aktiv";
CM_ SG_ 2549088259 Sekundaer_03_LEH_Wakeup "enthält die Weckursache; stehen mehrere Weckursachen parallel an, dann muss der kleinste Wert übertragen werden";
CM_ SG_ 2549088259 Sekundaer_03_Lokalaktiv "Zeigt an ob das SG nach Klemme15 AUS und nach entsprechender MAX Aktivzeit noch aktiv war";
CM_ SG_ 2549088259 Sekundaer_03_Nachlauftyp "Abgebildet wird die von der Hardware vorgegebene Möglichkeit, die Kommunikation nach Klemme 15 = AUS aufrecht zu erhalten. Es wird ein Init-Wert gesendet.
0 = Kommunikation nur bei KL15=EIN (kein Nachlauf, nicht weckfähig)
1 = Kommunikation nach KL15=AU";
CM_ SG_ 2549088259 Sekundaer_03_SNI "Das Signal beinhaltet den Source Node Identifier (Knotenadresse, die auch in der Abbildungsvorschrift zur CAN-ID für die NM-High Botschaft verwendet wird).";
CM_ SG_ 2549088259 Sekundaer_03_Transport_Mode "Funktionseinschränkung aufgrund aktivem Transport Mode und/oder Transport Schutz";

CM_ SG_ 2549088329 NM_Sub_Gateway_Lokalaktiv "Zeigt an ob das SG nach Klemme15 AUS und nach entsprechender MAX Aktivzeit noch aktiv war";
CM_ SG_ 2549088329 NM_Sub_Gateway_Subsystemaktiv "Zeigt an ob ein Subsystem des SGs nach Klemme15 AUS und nach entsprechender MAX Aktivzeit noch aktiv war";
CM_ SG_ 2549088329 NM_Sub_Gateway_Wakeup "enthält die Weckursache; stehen mehrere Weckursachen parallel an, dann muss der kleinste Wert übertragen werden";
CM_ SG_ 2549088329 Sub_Gateway_Abschaltstufe "Funktionseinschraenkung aufgrund aktiver Abschaltstufe";
CM_ SG_ 2549088329 Sub_Gateway_BusKnockOutTimer "Ausgabe des BusKnockOut-Timer in der Knotenbotschaft
";
CM_ SG_ 2549088329 Sub_Gateway_KD_Fehler "Bei gesetztem Bit ist mindestens ein Kundendienstfehler eingetragen";
CM_ SG_ 2549088329 Sub_Gateway_KompSchutz "Funktionseinschraenkung aufgrund Komponentenschutz aktiv";
CM_ SG_ 2549088329 Sub_Gateway_Nachlauftyp "Abgebildet wird die von der Hardware vorgegebene Möglichkeit, die Kommunikation nach Klemme 15 = AUS aufrecht zu erhalten. Es wird ein Init-Wert gesendet.
0 = Kommunikation nur bei KL15=EIN (kein Nachlauf, nicht weckfähig)
1 = Kommunikation nach KL15=AU";
CM_ SG_ 2549088329 Sub_Gateway_SNI "Das Signal beinhaltet den Source Node Identifier (Knotenadresse, die auch in der Abbildungsvorschrift zur CAN-ID für die NM-High Botschaft verwendet wird).";
CM_ SG_ 2549088329 Sub_Gateway_Transport_Mode "Funktionseinschränkung aufgrund aktivem Transport Mode und/ oder Transport Schutz";

CM_ SG_ 2549088322 KN_TME_BusKnockOutTimer "Ausgabe des BusKnockOut-Timer";
CM_ SG_ 2549088322 NM_TME_Wakeup "enthält die Weckursache; stehen mehrere Weckursachen parallel an, dann muss der kleinste Wert übertragen werden";
CM_ SG_ 2549088322 NMH_TME_Lokalaktiv "Zeigt an ob Steuergerät lokal aktiv war";
CM_ SG_ 2549088322 NMH_TME_Subsystemaktiv "Zeigt an ob ein Subsystem des SGs nach Klemme15 AUS und nach entsprechender MAX Aktivzeit noch aktiv war";
CM_ SG_ 2549088322 TME_Abschaltstufe "Funktionseinschränkung aufgrund aktiver Abschaltstufe";
CM_ SG_ 2549088322 TME_KD_Fehler "Bei gesetztem Bit ist mindestens ein Kundendienstfehler eingetragen";
CM_ SG_ 2549088322 TME_KompSchutz "Funktionseinschränkung aufgrund Komponentenschutz aktiv";
CM_ SG_ 2549088322 TME_Nachlauftyp "Abgebildet wird die von der Hardware vorgegebene Möglichkeit, die Kommunikation nach Klemme 15 = AUS aufrecht zu erhalten. Es wird ein Init-Wert gesendet.";
CM_ SG_ 2549088322 TME_SNI "Das Signal beinhaltet den Source Node Identifier (Knotenadresse, die auch in der Abbildungsvorschrift zur CAN-ID für die NM-High Botschaft verwendet wird).";
CM_ SG_ 2549088322 TME_Transport_Mode "Funktionseinschränkung aufgrund aktivem Transport Mode und/oder Transport Schutz";

CM_ SG_ 779 KBI_ABS_Lampe "ABS-Sicherheits-Lampe wurde eingeschaltet.";
CM_ SG_ 779 KBI_Airbag_Lampe "Airbag Sicherheits-Lampe wurde eingeschaltet ";
CM_ SG_ 779 KBI_angez_Geschw "Im Tacho angezeigte Geschwindigkeit inklusive der Voreilung

";
CM_ SG_ 779 KBI_Anzeigefehler_NV "Über dieses Signal teilt das Kombiinstrument dem Nightvision-Steuergerät mit, dass ein Fehler vom Kombiinstrument diagnostiziert wurde, der zur Abschaltung der Nightvision-Funktion führen muss.";
CM_ SG_ 779 KBI_Anzeigefehler_SWA "Signal bezieht sich nur auf die SWA-Lampe, Vorhalt für Kombis mit SWA-Lampe. ";
CM_ SG_ 779 KBI_Anzeigestatus_ACC "Status der ACC-Anzeige im nicht permanenten Displaybereich";
CM_ SG_ 779 KBI_Anzeigestatus_GRA "Anzeigestatus der GRA High Wunschgeschwindigkeitsanzeige im Kombiinstrument.
Bei VW bedeutet 'nicht vorhanden' GRA-low fähig (LED immer verbaut).
0 = nicht vorhanden
1 = Wunschgeschwindigkeits-Anzeigemöglichkeit vorhanden
2 = reserviert
3 = Fehler (B";
CM_ SG_ 779 KBI_Anzeigestatus_LIM "Anzeigestatus der Speedlimiter Wunschgeschwindigkeitsanzeige im Kombiinstrument (permanenter Anzeigebereich)
0 = nicht vorhanden
1 = Wunschgeschwindigkeits-Anzeigemöglichkeit vorhanden
2 = reserviert
3 = Fehler (Botschaftsüberwachung, Timeout, Akustik";
CM_ SG_ 779 KBI_ARA_in_Anzeige "Anzeige von ARA im Kombi aktiv";
CM_ SG_ 779 KBI_Bestaetigung_ESP_Off "ESP Off Bestätigung vom Kombi ans ESC";
CM_ SG_ 779 KBI_BKL_Lampe "Sicherheits-Lampe Bremskontrolle wurde eingeschaltet;
";
CM_ SG_ 779 KBI_Einheit_Tacho "Information, ob es sich um Meilen- oder Kmh-Kombi handelt, Einheit des Tachos entspricht dem Zifferblatt, Grösse ist nicht veränderlich";
CM_ SG_ 779 KBI_ESP_Lampe "ESP-Sicherheits-Lampe wurde eingeschaltet ";
CM_ SG_ 779 KBI_Fehler_Anzeige_ACC "Rückmeldung an ACC, dass mindestens eine der ACC-relevanten Anzeigen -rote Fahrerübernahme, Mitteldisplay, Gong - fehlerhaft sind.";
CM_ SG_ 779 KBI_GRA_Hauptschalter "Hauptschalter der Fahrerassistenzsysteme basierend auf dem FAS-Menu im Kombi.";
CM_ SG_ 779 KBI_Handbremse "Handbremsen-Information vom Kombi.
Das Signal bezieht sich ausschließlich auf den Zustand der konventionellen Handbremse.";
CM_ SG_ 779 KBI_im_Stellgliedtest "Kombi im Stellgliedtest, Signal muss eingelesen werden, um Fehlfunktion aufgrund der Bewegung der Stellglieder (Drehzahlmesser, Tacho) des Kombis zu verhindern";
CM_ SG_ 779 KBI_Konsistenz_ACC "Rückmeldung an ACC, dass die Botschaften zur Ansteuerung von Anzeigen nicht bzw. nicht konsistent empfangen wurden (Timeout-, BZ-, CHK- und DLC-Fehler)                                                                                                        ";
CM_ SG_ 779 KBI_Lenkung_Lampe "Sicherheits-Lampe der Lenkung (Lenkhilfe EPS, Audi-Dynamic-Steering ...) wurde eingeschaltet.

0x0 = Lenkungs-Lampe aus
0x1 = Lenkungs-Lampe ein";
CM_ SG_ 779 KBI_MFA_v_Einheit_01 "Einheit der Geschwindigkeit, die vom Fahrer im Car-Menü gewählt wurde. Veränderliche Grösse, im Gegensatz zur Einheit des Tachokranzes.";
CM_ SG_ 779 KBI_NV_in_Anzeige "Das Bit gibt dem NV die Information, ob NV-Bild im Kombi in der Anzeige ist. (Information ist notwendig um Kontrasverstellungen nur dann zuzulassen, wenn der Fahrer das Feedback über das  Kombidisplay bekommt.)";
CM_ SG_ 779 KBI_PLA_in_Anzeige "Das Signal wird als aktive Rückmeldung genutzt, ob die Info des PLA im Kombi angezeigt wird. Wenn nach Anforderung des Displays das Signal zweimal auf 0 ist, wird der Parkvorgang abgebrochen.
Ein Kombi, dass PLA Anzeige nicht unterstützt, schickt dauerha";
CM_ SG_ 779 KBI_SILA_gueltig "Rückmeldeinformation (Bit 1-6) ist gültig";
CM_ SG_ 779 KBI_Systemstatus "Signalisiert erkannte FuSi-relevante Fehler im Kombi
(keinen Ausfall der Akustik oder des Displays)";
CM_ SG_ 779 KBI_Tankwarnung "Fahrer wird gewarnt, dass er den Reservebereich erreicht hat. Fzg.spezifische Warnschwelle";
CM_ SG_ 779 KBI_Tankwarnung_ungueltig "Validiert den Inhalt des Signales KBI_Tankwarnung";
CM_ SG_ 779 KBI_Taster_Fahrwerk "Betätigung Taster 'Fahrwerk' im Kombi";
CM_ SG_ 779 KBI_Taster_Lift "Betätigung Taster 'Lift' im Kombi J1 zur Verarbeitung im Porsche EFP Steuergerät";
CM_ SG_ 779 KBI_V_Digital "Ausgabe der im Kombi angezeigten digitalen Geschwindigkeit.

Einheit ist im KBI_MFA_v_Einheit_01 definiert";
CM_ SG_ 779 KBI_Vorglueh_System_Lampe "Rückmeldung der Vorglühlampe bzw. Motor Systemlampe (MO_Systemlampe) an den Motor (bei Diesel und Otto!). Hardwaremässig gleiche LED im Kombi (EPC- oder Glühwendel), Unterscheidung nur über Ziffernblatt.";

CM_ SG_ 1719 KBI_aktive_Laengsfunktion "Auswahl, der vom Fahrer gewünschten Laengsregelfunktion";
CM_ SG_ 1719 KBI_FoD_PopUP_Quittiert "Angezeigte FoD-Warnung im Kombi wurde vom Fahrer quittiert; 
Signal wird für die Dauer von 2 Sekunden gesendet";
CM_ SG_ 1719 KBI_FStatus_Tank "Signal wird gesetzt:

a) Während der Fehlerentprellzeit (20 s Entprellung)

b) Bei erkanntem Fehler wird der Tankinhalt während der laufenden KL15-Phase über den 
    Verbrauch zurückgerechnet. In dieser Zeit ist das Bit ebenfalls gesetzt. Nach einem";
CM_ SG_ 1719 KBI_GRA_im_ACC "Gibt den vom Fahrer ausgewählten Modus (ACC oder GRA_im_ACC) an.";
CM_ SG_ 1719 KBI_Inhalt_Tank "Restmenge 2 bzw. 2,5l nicht auflösbar

";
CM_ SG_ 1719 KBI_Kilometerstand "Fehler wird ausgegeben, falls Kilometerstand nicht restaurierbar
";
CM_ SG_ 1719 KBI_LVDS_Lock "Dient zur Synchronisation der Anzeige zwischen Kombi und ZR";
CM_ SG_ 1719 KBI_Oelwechsel_durchgefuehrt "Nach einen Ölwechsel (Service) ist die Ethanol Warmfahrwarnung zu unterdrücken.";
CM_ SG_ 1719 KBI_QBit_Aussen_Temp_gef "0x0 = gültiger Wert
0x1 = Ersatz-, Init- oder Fehlerwert";
CM_ SG_ 1719 KBI_RDK_Kalibrier_Anf "Bei gesetztem Bit soll die RDK die aktuellen Istdrücke zu Solldrücken übernehmen (nur bei Nichtverbau einer Headunit erforderlich).";
CM_ SG_ 1719 KBI_Reserve_Warnung_Sek "Signalisiert die Reservewarnung für die Energiespeicher CNG, LPG, HV-Batterie.
Fahrer wird gewarnt, dass er den Reservebereich erreicht hat. Fzg.spezifische Warnschwelle.";
CM_ SG_ 1719 KBI_Standzeit_02 "Zähler welcher die Standzeit des Motors wiedergibt.
Das Signal beschreibt den Anteil der Motor-Standzeit zwischen Zündung aus und nächstem Motorstart.";
CM_ SG_ 1719 KBI_TA_gewaehlt_Fahrer "Rueckmeldung, dass der TA vom Fahrer gewaehlt wurde";

CM_ SG_ 2549875067 KS_Hybrid_01_Req_Data "ISO-TP Datenkanal - FID2NA
Request Funktion 0x01 Komponentenschutz an Knoten 0x7B";

CM_ SG_ 2550006139 KS_Hybrid_01_Resp_Data "ISO-TP Datenkanal - FID2NA
Response Knoten 0x7B an Funktion 0x01 Komponentenschutz";

CM_ SG_ 2549875142 KS_Ladegeraet_2_Req_Data "ISO-TP Datenkanal - FID2NA
Request Funktion 0x01 Komponentenschutz an Knoten 0xC6";

CM_ SG_ 2550006214 KS_Ladegeraet_2_Resp_Data "ISO-TP Datenkanal - FID2NA
Response Knoten 0xC6 an Funktion 0x01 Komponentenschutz";

CM_ SG_ 2549875012 KS_Ladegeraet_Req_Data "Komponentenschutz (Funktion 01h). Request mit NA des Slaves.";

CM_ SG_ 2550006084 KS_Ladegeraet_Resp_Data "Komponentenschutz (Funktion 01h). Response mit eigener NA.";

CM_ SG_ 2549899473 KS_SSN_CMC_01_Req_Data "Komponentenschutz (Funktion 01h). Request mit NA des Slaves.";

CM_ SG_ 2550030545 KS_SSN_CMC_01_Resp_Data "Komponentenschutz (Funktion 01h). Request mit NA des Slaves.";

CM_ SG_ 2549899474 KS_SSN_CMC_02_Req_Data "Komponentenschutz (Funktion 01h). Request mit NA des Slaves.";

CM_ SG_ 2550030546 KS_SSN_CMC_02_Resp_Data "Komponentenschutz (Funktion 01h). Request mit NA des Slaves.";

CM_ SG_ 2549899475 KS_SSN_CMC_03_Req_Data "Komponentenschutz (Funktion 01h). Request mit NA des Slaves.";

CM_ SG_ 2550030547 KS_SSN_CMC_03_Resp_Data "Komponentenschutz (Funktion 01h). Request mit NA des Slaves.";

CM_ SG_ 2549899476 KS_SSN_CMC_04_Req_Data "Komponentenschutz (Funktion 01h). Request mit NA des Slaves.";

CM_ SG_ 2550030548 KS_SSN_CMC_04_Resp_Data "Komponentenschutz (Funktion 01h). Request mit NA des Slaves.";

CM_ SG_ 2549899477 KS_SSN_CMC_05_Req_Data "Komponentenschutz (Funktion 01h). Request mit NA des Slaves.";

CM_ SG_ 2550030549 KS_SSN_CMC_05_Resp_Data "Komponentenschutz (Funktion 01h). Request mit NA des Slaves.";

CM_ SG_ 2549899478 KS_SSN_CMC_06_Req_Data "Komponentenschutz (Funktion 01h). Request mit NA des Slaves.";

CM_ SG_ 2550030550 KS_SSN_CMC_06_Resp_Data "Komponentenschutz (Funktion 01h). Request mit NA des Slaves.";

CM_ SG_ 2549899479 KS_SSN_CMC_07_Req_Data "Komponentenschutz (Funktion 01h). Request mit NA des Slaves.";

CM_ SG_ 2550030551 KS_SSN_CMC_07_Resp_Data "Komponentenschutz (Funktion 01h). Request mit NA des Slaves.";

CM_ SG_ 2549899480 KS_SSN_CMC_08_Req_Data "Komponentenschutz (Funktion 01h). Request mit NA des Slaves.";

CM_ SG_ 2550030552 KS_SSN_CMC_08_Resp_Data "Komponentenschutz (Funktion 01h). Request mit NA des Slaves.";

CM_ SG_ 2549899481 KS_SSN_CMC_09_Req_Data "Komponentenschutz (Funktion 01h). Request mit NA des Slaves.";

CM_ SG_ 2550030553 KS_SSN_CMC_09_Resp_Data "Komponentenschutz (Funktion 01h). Request mit NA des Slaves.";

CM_ SG_ 2549899482 KS_SSN_CMC_10_Req_Data "Komponentenschutz (Funktion 01h). Request mit NA des Slaves.";

CM_ SG_ 2550030554 KS_SSN_CMC_10_Resp_Data "Komponentenschutz (Funktion 01h). Request mit NA des Slaves.";

CM_ SG_ 2549899483 KS_SSN_CMC_11_Req_Data "Komponentenschutz (Funktion 01h). Request mit NA des Slaves.";

CM_ SG_ 2550030555 KS_SSN_CMC_11_Resp_Data "Komponentenschutz (Funktion 01h). Request mit NA des Slaves.";

CM_ SG_ 2549899484 KS_SSN_CMC_12_Req_Data "Komponentenschutz (Funktion 01h). Request mit NA des Slaves.";

CM_ SG_ 2550030556 KS_SSN_CMC_12_Resp_Data "Komponentenschutz (Funktion 01h). Request mit NA des Slaves.";

CM_ SG_ 2549899505 KS_SSN_CMC_13_Req_Data "Komponentenschutz (Funktion 01h). Request mit NA des Slaves.";

CM_ SG_ 2550030577 KS_SSN_CMC_13_Resp_Data "Komponentenschutz (Funktion 01h). Request mit NA des Slaves.";

CM_ SG_ 2549899506 KS_SSN_CMC_14_Req_Data "Komponentenschutz (Funktion 01h). Request mit NA des Slaves.";

CM_ SG_ 2550030578 KS_SSN_CMC_14_Resp_Data "Komponentenschutz (Funktion 01h). Request mit NA des Slaves.";

CM_ SG_ 2549899507 KS_SSN_CMC_15_Req_Data "Komponentenschutz (Funktion 01h). Request mit NA des Slaves.";

CM_ SG_ 2550030579 KS_SSN_CMC_15_Resp_Data "Komponentenschutz (Funktion 01h). Request mit NA des Slaves.";

CM_ SG_ 2463978640 LAD2_01_BZ "4bit Botschaftszähler, wird mit jeder Sendebotschaft inkrementiert";
CM_ SG_ 2463978640 LAD2_01_CRC "Für MLB:
Berechnung siehe Lastenheft 'Kommunikationsabsicherung für FlexRay und CAN'
Ab MQB und MLBevo:
Berechnung siehe Lastenheft 'End-to-End Kommunikationsabsicherung'

Endwerte siehe Begleitdokument 'S-PDU Kennungsfolgen'";
CM_ SG_ 2463978640 LAD2_Abregelung_Temperatur "Abregelung auf Grund interner Übertemperatur im OBC2";
CM_ SG_ 2463978640 LAD2_Fehlerstatus "Aktueller Fehlerstatus von OBC2";
CM_ SG_ 2463978640 LAD2_IstModus "Uebergabe aktueller interner Status von OBC2 an OBC1";
CM_ SG_ 2463978640 LAD2_IstSpannung_HV "HV-Ausgangsspannung OBC2";
CM_ SG_ 2463978640 LAD2_Status_Pfad1 "Rail1 von OBC2 im Fehler und nicht nutzbar für Ladevorgang. Loadbalancing wird durch OBC1 durchgeführt.";
CM_ SG_ 2463978640 LAD2_Status_Pfad2 "Rail2 von OBC2 im Fehler und nicht nutzbar für Ladevorgang. Loadbalancing wird durch OBC1 durchgeführt.";
CM_ SG_ 2463978640 LAD2_Status_Pfad3 "Rail3 von OBC2 im Fehler und nicht nutzbar für Ladevorgang. Loadbalancing wird durch OBC1 durchgeführt.";
CM_ SG_ 2463978640 LAD2_Status_Phasenumschaltung1 "Phasenumschaltung1 von OBC2 im Fehler. Loadbalancing wird durch OBC1 durchgeführt.";
CM_ SG_ 2463978640 LAD2_Status_Phasenumschaltung2 "Phasenumschaltung2 von OBC2 im Fehler. Loadbalancing wird durch OBC1 durchgeführt.";
CM_ SG_ 2463978640 LAD2_Status_Spgfreiheit "Status Spannungsfreiheit OBC2";
CM_ SG_ 2463978640 LAD2_Temperatur "Momentanwert Temperatur OBC2";

CM_ SG_ 2463978644 LAD2_AC_Istspannung_L1 "AC-IstSpannung Rail1 von OBC2";
CM_ SG_ 2463978644 LAD2_AC_Istspannung_L2 "AC-IstSpannung Rail2 von OBC2";
CM_ SG_ 2463978644 LAD2_AC_Istspannung_L3 "AC-IstSpannung Rail3 von OBC2";
CM_ SG_ 2463978644 LAD2_IstStrom_HV_Pfad1 "HV-IstStrom Rail1 von OBC2";
CM_ SG_ 2463978644 LAD2_IstStrom_HV_Pfad2 "HV-IstStrom Rail2 von OBC2";
CM_ SG_ 2463978644 LAD2_IstStrom_HV_Pfad3 "HV-IstStrom Rail3 von OBC2";

CM_ SG_ 2463978645 LAD2_AC_IstStrom_L1 "AC-IstStrom Rail1 von OBC2";
CM_ SG_ 2463978645 LAD2_AC_IstStrom_L2 "AC-IstStrom Rail2 von OBC2";
CM_ SG_ 2463978645 LAD2_AC_IstStrom_L3 "AC-IstStrom Rail3 von OBC2";

CM_ SG_ 2589283493 LAD2_CALID_CVN_MUX "Alle CALID-Indizes bilden zusammen die CALID (OBC2)";
CM_ SG_ 2589283493 LAD2_CALID_Index_01 "Software-Calibration-Identification (CALID) im ASCII-Zeichenformat; 
für Ausgabe an das Generic Scan-Tool für OBD in NAR

0x30 entspricht ASCII '0'";
CM_ SG_ 2589283493 LAD2_CALID_Index_02 "Software-Calibration-Identification (CALID) im ASCII-Zeichenformat; 
für Ausgabe an das Generic Scan-Tool für OBD in NAR

0x30 entspricht ASCII '0'";
CM_ SG_ 2589283493 LAD2_CALID_Index_03 "Software-Calibration-Identification (CALID) im ASCII-Zeichenformat; 
für Ausgabe an das Generic Scan-Tool für OBD in NAR

0x30 entspricht ASCII '0'";
CM_ SG_ 2589283493 LAD2_CALID_Index_04 "Software-Calibration-Identification (CALID) im ASCII-Zeichenformat; 
für Ausgabe an das Generic Scan-Tool für OBD in NAR

0x30 entspricht ASCII '0'";
CM_ SG_ 2589283493 LAD2_CALID_Index_05 "Software-Calibration-Identification (CALID) im ASCII-Zeichenformat; 
für Ausgabe an das Generic Scan-Tool für OBD in NAR

0x30 entspricht ASCII '0'";
CM_ SG_ 2589283493 LAD2_CALID_Index_06 "Software-Calibration-Identification (CALID) im ASCII-Zeichenformat; 
für Ausgabe an das Generic Scan-Tool für OBD in NAR

0x30 entspricht ASCII '0'";
CM_ SG_ 2589283493 LAD2_CALID_Index_07 "Software-Calibration-Identification (CALID) im ASCII-Zeichenformat; 
für Ausgabe an das Generic Scan-Tool für OBD in NAR

0x30 entspricht ASCII '0'";
CM_ SG_ 2589283493 LAD2_CALID_Index_08 "Software-Calibration-Identification (CALID) im ASCII-Zeichenformat; 
für Ausgabe an das Generic Scan-Tool für OBD in NAR

0x30 entspricht ASCII '0'";
CM_ SG_ 2589283493 LAD2_CALID_Index_09 "Software-Calibration-Identification (CALID) im ASCII-Zeichenformat; 
für Ausgabe an das Generic Scan-Tool für OBD in NAR

0x30 entspricht ASCII '0'";
CM_ SG_ 2589283493 LAD2_CALID_Index_10 "Software-Calibration-Identification (CALID) im ASCII-Zeichenformat; 
für Ausgabe an das Generic Scan-Tool für OBD in NAR

0x30 entspricht ASCII '0'";
CM_ SG_ 2589283493 LAD2_CALID_Index_11 "Software-Calibration-Identification (CALID) im ASCII-Zeichenformat; 
für Ausgabe an das Generic Scan-Tool für OBD in NAR

0x30 entspricht ASCII '0'";
CM_ SG_ 2589283493 LAD2_CALID_Index_12 "Software-Calibration-Identification (CALID) im ASCII-Zeichenformat; 
für Ausgabe an das Generic Scan-Tool für OBD in NAR

0x30 entspricht ASCII '0'";
CM_ SG_ 2589283493 LAD2_CALID_Index_13 "Software-Calibration-Identification (CALID) im ASCII-Zeichenformat; 
für Ausgabe an das Generic Scan-Tool für OBD in NAR

0x30 entspricht ASCII '0'";
CM_ SG_ 2589283493 LAD2_CALID_Index_14 "Software-Calibration-Identification (CALID) im ASCII-Zeichenformat; 
für Ausgabe an das Generic Scan-Tool für OBD in NAR

0x30 entspricht ASCII '0'";
CM_ SG_ 2589283493 LAD2_CALID_Index_15 "Software-Calibration-Identification (CALID) im ASCII-Zeichenformat; 
für Ausgabe an das Generic Scan-Tool für OBD in NAR

0x30 entspricht ASCII '0'";
CM_ SG_ 2589283493 LAD2_CALID_Index_16 "Software-Calibration-Identification (CALID) im ASCII-Zeichenformat; 
für Ausgabe an das Generic Scan-Tool für OBD in NAR

0x30 entspricht ASCII '0'";
CM_ SG_ 2589283493 LAD2_CVN_Byte_1 "Calibration Verification Number (CVN bzw. Checksumme) des SW- und Datenstandes; 
für Ausgabe an das Generic Scan-Tool für OBD in NAR";
CM_ SG_ 2589283493 LAD2_CVN_Byte_2 "Calibration Verification Number (CVN bzw. Checksumme) des SW- und Datenstandes; 
für Ausgabe an das Generic Scan-Tool für OBD in NAR";
CM_ SG_ 2589283493 LAD2_CVN_Byte_3 "Calibration Verification Number (CVN bzw. Checksumme) des SW- und Datenstandes; 
für Ausgabe an das Generic Scan-Tool für OBD in NAR";
CM_ SG_ 2589283493 LAD2_CVN_Byte_4 "Calibration Verification Number (CVN bzw. Checksumme) des SW- und Datenstandes; 
für Ausgabe an das Generic Scan-Tool für OBD in NAR";
CM_ SG_ 2589283493 LAD2_CVN_VLD "Valid-Bit der Calibration-Verification-Number (CVN bzw. Checksumme) für OBC2";

CM_ SG_ 2589283392 LAD2_KomponentenFehler_01 "Übertragung OBD relevanter Fehlerpfade vom Secondary zum Primary Steuergerät. 
Zuordnung der generischen Komponentenfehler muss zwischen Sender und Empfänger abgestimmt werden.";
CM_ SG_ 2589283392 LAD2_KomponentenFehler_02 "Übertragung OBD relevanter Fehlerpfade vom Secondary zum Primary Steuergerät. 
Zuordnung der generischen Komponentenfehler muss zwischen Sender und Empfänger abgestimmt werden.";
CM_ SG_ 2589283392 LAD2_KomponentenFehler_03 "Übertragung OBD relevanter Fehlerpfade vom Secondary zum Primary Steuergerät. 
Zuordnung der generischen Komponentenfehler muss zwischen Sender und Empfänger abgestimmt werden.";
CM_ SG_ 2589283392 LAD2_KomponentenFehler_04 "Übertragung OBD relevanter Fehlerpfade vom Secondary zum Primary Steuergerät. 
Zuordnung der generischen Komponentenfehler muss zwischen Sender und Empfänger abgestimmt werden.";
CM_ SG_ 2589283392 LAD2_KomponentenFehler_05 "Übertragung OBD relevanter Fehlerpfade vom Secondary zum Primary Steuergerät. 
Zuordnung der generischen Komponentenfehler muss zwischen Sender und Empfänger abgestimmt werden.";
CM_ SG_ 2589283392 LAD2_KomponentenFehler_06 "Übertragung OBD relevanter Fehlerpfade vom Secondary zum Primary Steuergerät. 
Zuordnung der generischen Komponentenfehler muss zwischen Sender und Empfänger abgestimmt werden.";
CM_ SG_ 2589283392 LAD2_KomponentenFehler_07 "Übertragung OBD relevanter Fehlerpfade vom Secondary zum Primary Steuergerät. 
Zuordnung der generischen Komponentenfehler muss zwischen Sender und Empfänger abgestimmt werden.";
CM_ SG_ 2589283392 LAD2_KomponentenFehler_08 "Übertragung OBD relevanter Fehlerpfade vom Secondary zum Primary Steuergerät. 
Zuordnung der generischen Komponentenfehler muss zwischen Sender und Empfänger abgestimmt werden.";
CM_ SG_ 2589283392 LAD2_KomponentenFehler_09 "Übertragung OBD relevanter Fehlerpfade vom Secondary zum Primary Steuergerät. 
Zuordnung der generischen Komponentenfehler muss zwischen Sender und Empfänger abgestimmt werden.";
CM_ SG_ 2589283392 LAD2_KomponentenFehler_10 "Übertragung OBD relevanter Fehlerpfade vom Secondary zum Primary Steuergerät. 
Zuordnung der generischen Komponentenfehler muss zwischen Sender und Empfänger abgestimmt werden.";
CM_ SG_ 2589283392 LAD2_KomponentenFehler_11 "Übertragung OBD relevanter Fehlerpfade vom Secondary zum Primary Steuergerät. 
Zuordnung der generischen Komponentenfehler muss zwischen Sender und Empfänger abgestimmt werden.";
CM_ SG_ 2589283392 LAD2_KomponentenFehler_12 "Übertragung OBD relevanter Fehlerpfade vom Secondary zum Primary Steuergerät. 
Zuordnung der generischen Komponentenfehler muss zwischen Sender und Empfänger abgestimmt werden.";
CM_ SG_ 2589283392 LAD2_KomponentenFehler_13 "Übertragung OBD relevanter Fehlerpfade vom Secondary zum Primary Steuergerät. 
Zuordnung der generischen Komponentenfehler muss zwischen Sender und Empfänger abgestimmt werden.";
CM_ SG_ 2589283392 LAD2_KomponentenFehler_14 "Übertragung OBD relevanter Fehlerpfade vom Secondary zum Primary Steuergerät. 
Zuordnung der generischen Komponentenfehler muss zwischen Sender und Empfänger abgestimmt werden.";
CM_ SG_ 2589283392 LAD2_KomponentenFehler_15 "Übertragung OBD relevanter Fehlerpfade vom Secondary zum Primary Steuergerät. 
Zuordnung der generischen Komponentenfehler muss zwischen Sender und Empfänger abgestimmt werden.";
CM_ SG_ 2589283392 LAD2_KomponentenFehler_16 "Übertragung OBD relevanter Fehlerpfade vom Secondary zum Primary Steuergerät. 
Zuordnung der generischen Komponentenfehler muss zwischen Sender und Empfänger abgestimmt werden.";
CM_ SG_ 2589283392 LAD2_KomponentenFehler_17 "Übertragung OBD relevanter Fehlerpfade vom Secondary zum Primary Steuergerät. 
Zuordnung der generischen Komponentenfehler muss zwischen Sender und Empfänger abgestimmt werden.";
CM_ SG_ 2589283392 LAD2_KomponentenFehler_18 "Übertragung OBD relevanter Fehlerpfade vom Secondary zum Primary Steuergerät. 
Zuordnung der generischen Komponentenfehler muss zwischen Sender und Empfänger abgestimmt werden.";
CM_ SG_ 2589283392 LAD2_KomponentenFehler_19 "Übertragung OBD relevanter Fehlerpfade vom Secondary zum Primary Steuergerät. 
Zuordnung der generischen Komponentenfehler muss zwischen Sender und Empfänger abgestimmt werden.";
CM_ SG_ 2589283392 LAD2_KomponentenFehler_20 "Übertragung OBD relevanter Fehlerpfade vom Secondary zum Primary Steuergerät. 
Zuordnung der generischen Komponentenfehler muss zwischen Sender und Empfänger abgestimmt werden.";

CM_ SG_ 2589283688 LAD2_Version "Abgleich der SW-Version zwischen OBC1 und  OBC2 zur Plausibilisierung in der 2x11 kW Topologie";
CM_ SG_ 2589283688 LAD2_Version_Index_01 "Marke Architektur";
CM_ SG_ 2589283688 LAD2_Version_Index_02 "Leistungsklasse";
CM_ SG_ 2589283688 LAD2_Version_Index_03 "Versionszähler Zehner";
CM_ SG_ 2589283688 LAD2_Version_Index_04 "Versionszähler Einer";
CM_ SG_ 2589283688 LAD2_Version_MUX "Alle Indizes ergeben die SW-Version";

CM_ SG_ 1380 LAD_01_BZ "freilaufender Botschaftszähler";
CM_ SG_ 1380 LAD_01_CRC "Ab MQB und MLBevo:
'Berechnung siehe Lastenheft 'End-to-End Kommunikationsabsicherung''

Endwerte siehe Begleitdokument 'S-PDU Kennungsfolgen'";
CM_ SG_ 1380 LAD_AC_Istspannung "Istwert AC-Netzspannung (RMS) ";
CM_ SG_ 1380 LAD_IstModus "Betriebsmodus des Ladegerätes";
CM_ SG_ 1380 LAD_IstSpannung_HV "Ausgangsspannung Lader";
CM_ SG_ 1380 LAD_IstStrom_HV "Ausgangsstrom Lader";
CM_ SG_ 1380 LAD_Status_Spgfreiheit "0 = Init (ohne Funktion)
1 = Ladegerät HV-Komponenten spannungsfrei (U_Zwkr < 20V)
2 = Ladegerät HV_Komponenten nicht spannungsfrei (U_Zwkr >= 20V)
3 = Fehler (z. B. Fehler in der Sensorik)";
CM_ SG_ 1380 LAD_Temperatur "Momentanwert: Temperatur Ladegerät";
CM_ SG_ 1380 LAD_Verlustleistung "Momentanwert: Verlustleistung Ladegerät";

CM_ SG_ 1662 LAD_02_BZ "freilaufender Botschaftszähler";
CM_ SG_ 1662 LAD_02_CRC "Ab MQB und MLBevo:
'Berechnung siehe Lastenheft 'End-to-End Kommunikationsabsicherung''

Endwerte siehe Begleitdokument 'S-PDU Kennungsfolgen'";
CM_ SG_ 1662 LAD_Abregelung_BuchseTemp "Reduzierung aufgrund zu hoher Temperatur der Ladebuchse";
CM_ SG_ 1662 LAD_Abregelung_IU_Ein_Aus "Abregelung aufgrund Strom oder Spannung am Eingang oder Ausgang";
CM_ SG_ 1662 LAD_Abregelung_Temperatur "Abregelung aufgrund interner Übertemperatur im Ladegerät";
CM_ SG_ 1662 LAD_CP_Erkennung "Status Control Pilot Überwachung (Erkennung des Control Pilot Duty-Cycles)";
CM_ SG_ 1662 LAD_Fehlerzustand "Sammelfehler Ladegerät - kein Laden möglich";
CM_ SG_ 1662 LAD_Kuehlbedarf "Kühlbedarf des Ladegerätes";
CM_ SG_ 1662 LAD_MaxLadLeistung_HV "Maximale Leistung Ladegerät bezogen auf die maximale Leistung Infrastruktur (Kabel, Ladestation) und Berücksichtigung des Ladegerät-Wirkungsgrades";
CM_ SG_ 1662 LAD_MaxLadLeistung_HV_Offset "Signal kann in Ergänzung zu LAD_MaxLadLeistung_HV (100W Skalierung) genutzt werden, um die Auflösegenauigkeit auf 25W zu erweitern.";
CM_ SG_ 1662 LAD_PRX_Stromlimit "AC-Stromlimit aufgrund der PRX Kabelkodierung";
CM_ SG_ 1662 LAD_Stecker_Verriegelt "Status Steckerverriegelung (Rücklesekontakt des Verrieglungsaktors)";
CM_ SG_ 1662 LAD_Warnzustand "Sammelwarnung Ladegerät
0 keine Warnbedingung aktiv
1 Warnbedingung aktiv, evtl. eingeschränkte Leistungsfähigkeit";

CM_ SG_ 2463978642 LAD_SollStrom_HV_Pfad1 "HV-SollStrom für Rail1 von OBC2";
CM_ SG_ 2463978642 LAD_SollStrom_HV_Pfad2 "HV-Sollstrom für Rail2 von OBC2";
CM_ SG_ 2463978642 LAD_SollStrom_HV_Pfad3 "HV-Sollstrom für Rail3 von OBC2";

CM_ SG_ 2463978643 LAD_05_BZ "4bit Botschaftszähler, wird mit jeder Sendebotschaft inkrementiert";
CM_ SG_ 2463978643 LAD_05_CRC "Für MLB:
Berechnung siehe Lastenheft 'Kommunikationsabsicherung für FlexRay und CAN'
Ab MQB und MLBevo:
Berechnung siehe Lastenheft 'End-to-End Kommunikationsabsicherung'

Endwerte siehe Begleitdokument 'S-PDU Kennungsfolgen'";
CM_ SG_ 2463978643 LAD_AC_MaxStrom_L1 "Maximaler AC-Eingangsstrom auf Rail 1 für OBC2";
CM_ SG_ 2463978643 LAD_AC_MaxStrom_L2 "Maximaler AC-Eingangsstrom auf Rail 2 für OBC2";
CM_ SG_ 2463978643 LAD_AC_MaxStrom_L3 "Maximaler AC-Eingangsstrom auf Rail 3 für OBC2";
CM_ SG_ 2463978643 LAD_Freigabe_LAD2 "Ladefreigabe für zweiten OBC bei Verbau von 2x11 kW OBC";
CM_ SG_ 2463978643 LAD_Max_LadeSpannung_LAD2 "max. voltage / maximal erlaubte Ladespannung";

CM_ SG_ 2589283663 LAD_PlanAntw_Verlustleistung "Antwort auf die Ladeplan-Anfrage für die Ladeplanung: Verlustleistung";
CM_ SG_ 2589283663 LAD_PlanAntw_Zaehler "Antwort auf die Ladeplan-Anfrage für die Ladeplanung: Zähler";

CM_ SG_ 2589283415 LAD_CALID_CVN_MUX "Alle CALID-Indizes bilden zusammen die CALID";
CM_ SG_ 2589283415 LAD_CALID_Index_01 "Software-Calibration-Identification (CALID) im ASCII-Zeichenformat; 
für Ausgabe an das Generic Scan-Tool für OBD in NAR

0x30 entspricht ASCII '0'";
CM_ SG_ 2589283415 LAD_CALID_Index_02 "Software-Calibration-Identification (CALID) im ASCII-Zeichenformat; 
für Ausgabe an das Generic Scan-Tool für OBD in NAR

0x30 entspricht ASCII '0'";
CM_ SG_ 2589283415 LAD_CALID_Index_03 "Software-Calibration-Identification (CALID) im ASCII-Zeichenformat; 
für Ausgabe an das Generic Scan-Tool für OBD in NAR

0x30 entspricht ASCII '0'";
CM_ SG_ 2589283415 LAD_CALID_Index_04 "Software-Calibration-Identification (CALID) im ASCII-Zeichenformat; 
für Ausgabe an das Generic Scan-Tool für OBD in NAR

0x30 entspricht ASCII '0'";
CM_ SG_ 2589283415 LAD_CALID_Index_05 "Software-Calibration-Identification (CALID) im ASCII-Zeichenformat; 
für Ausgabe an das Generic Scan-Tool für OBD in NAR

0x30 entspricht ASCII '0'";
CM_ SG_ 2589283415 LAD_CALID_Index_06 "Software-Calibration-Identification (CALID) im ASCII-Zeichenformat; 
für Ausgabe an das Generic Scan-Tool für OBD in NAR

0x30 entspricht ASCII '0'";
CM_ SG_ 2589283415 LAD_CALID_Index_07 "Software-Calibration-Identification (CALID) im ASCII-Zeichenformat; 
für Ausgabe an das Generic Scan-Tool für OBD in NAR

0x30 entspricht ASCII '0'";
CM_ SG_ 2589283415 LAD_CALID_Index_08 "Software-Calibration-Identification (CALID) im ASCII-Zeichenformat; 
für Ausgabe an das Generic Scan-Tool für OBD in NAR

0x30 entspricht ASCII '0'";
CM_ SG_ 2589283415 LAD_CALID_Index_09 "Software-Calibration-Identification (CALID) im ASCII-Zeichenformat; 
für Ausgabe an das Generic Scan-Tool für OBD in NAR

0x30 entspricht ASCII '0'";
CM_ SG_ 2589283415 LAD_CALID_Index_10 "Software-Calibration-Identification (CALID) im ASCII-Zeichenformat; 
für Ausgabe an das Generic Scan-Tool für OBD in NAR

0x30 entspricht ASCII '0'";
CM_ SG_ 2589283415 LAD_CALID_Index_11 "Software-Calibration-Identification (CALID) im ASCII-Zeichenformat; 
für Ausgabe an das Generic Scan-Tool für OBD in NAR

0x30 entspricht ASCII '0'";
CM_ SG_ 2589283415 LAD_CALID_Index_12 "Software-Calibration-Identification (CALID) im ASCII-Zeichenformat; 
für Ausgabe an das Generic Scan-Tool für OBD in NAR

0x30 entspricht ASCII '0'";
CM_ SG_ 2589283415 LAD_CALID_Index_13 "Software-Calibration-Identification (CALID) im ASCII-Zeichenformat; 
für Ausgabe an das Generic Scan-Tool für OBD in NAR

0x30 entspricht ASCII '0'";
CM_ SG_ 2589283415 LAD_CALID_Index_14 "Software-Calibration-Identification (CALID) im ASCII-Zeichenformat; 
für Ausgabe an das Generic Scan-Tool für OBD in NAR

0x30 entspricht ASCII '0'";
CM_ SG_ 2589283415 LAD_CALID_Index_15 "Software-Calibration-Identification (CALID) im ASCII-Zeichenformat; 
für Ausgabe an das Generic Scan-Tool für OBD in NAR

0x30 entspricht ASCII '0'";
CM_ SG_ 2589283415 LAD_CALID_Index_16 "Software-Calibration-Identification (CALID) im ASCII-Zeichenformat; 
für Ausgabe an das Generic Scan-Tool für OBD in NAR

0x30 entspricht ASCII '0'";
CM_ SG_ 2589283415 LAD_CVN_Byte_1 "Calibration Verification Number (CVN bzw. Checksumme) des SW- und Datenstandes; 
für Ausgabe an das Generic Scan-Tool für OBD in NAR";
CM_ SG_ 2589283415 LAD_CVN_Byte_2 "Calibration Verification Number (CVN bzw. Checksumme) des SW- und Datenstandes; 
für Ausgabe an das Generic Scan-Tool für OBD in NAR";
CM_ SG_ 2589283415 LAD_CVN_Byte_3 "Calibration Verification Number (CVN bzw. Checksumme) des SW- und Datenstandes; 
für Ausgabe an das Generic Scan-Tool für OBD in NAR";
CM_ SG_ 2589283415 LAD_CVN_Byte_4 "Calibration Verification Number (CVN bzw. Checksumme) des SW- und Datenstandes; 
für Ausgabe an das Generic Scan-Tool für OBD in NAR";
CM_ SG_ 2589283415 LAD_CVN_VLD "Valid-Bit der Calibration-Verification-Number (CVN bzw. Checksumme)";

CM_ SG_ 2589283472 LAD_KomponentenFehler_01 "Übertragung OBD relevanter Fehlerpfade vom Secondary zum Primary Steuergerät. 
Zuordnung der generischen Komponentenfehler muss zwischen Sender und Empfänger abgestimmt werden.";
CM_ SG_ 2589283472 LAD_KomponentenFehler_02 "Übertragung OBD relevanter Fehlerpfade vom Secondary zum Primary Steuergerät. 
Zuordnung der generischen Komponentenfehler muss zwischen Sender und Empfänger abgestimmt werden.";
CM_ SG_ 2589283472 LAD_KomponentenFehler_03 "Übertragung OBD relevanter Fehlerpfade vom Secondary zum Primary Steuergerät. 
Zuordnung der generischen Komponentenfehler muss zwischen Sender und Empfänger abgestimmt werden.";
CM_ SG_ 2589283472 LAD_KomponentenFehler_04 "Übertragung OBD relevanter Fehlerpfade vom Secondary zum Primary Steuergerät. 
Zuordnung der generischen Komponentenfehler muss zwischen Sender und Empfänger abgestimmt werden.";
CM_ SG_ 2589283472 LAD_KomponentenFehler_05 "Übertragung OBD relevanter Fehlerpfade vom Secondary zum Primary Steuergerät. 
Zuordnung der generischen Komponentenfehler muss zwischen Sender und Empfänger abgestimmt werden.";
CM_ SG_ 2589283472 LAD_KomponentenFehler_06 "Übertragung OBD relevanter Fehlerpfade vom Secondary zum Primary Steuergerät. 
Zuordnung der generischen Komponentenfehler muss zwischen Sender und Empfänger abgestimmt werden.";
CM_ SG_ 2589283472 LAD_KomponentenFehler_07 "Übertragung OBD relevanter Fehlerpfade vom Secondary zum Primary Steuergerät. 
Zuordnung der generischen Komponentenfehler muss zwischen Sender und Empfänger abgestimmt werden.";
CM_ SG_ 2589283472 LAD_KomponentenFehler_08 "Übertragung OBD relevanter Fehlerpfade vom Secondary zum Primary Steuergerät. 
Zuordnung der generischen Komponentenfehler muss zwischen Sender und Empfänger abgestimmt werden.";
CM_ SG_ 2589283472 LAD_KomponentenFehler_09 "Übertragung OBD relevanter Fehlerpfade vom Secondary zum Primary Steuergerät. 
Zuordnung der generischen Komponentenfehler muss zwischen Sender und Empfänger abgestimmt werden.";
CM_ SG_ 2589283472 LAD_KomponentenFehler_10 "Übertragung OBD relevanter Fehlerpfade vom Secondary zum Primary Steuergerät. 
Zuordnung der generischen Komponentenfehler muss zwischen Sender und Empfänger abgestimmt werden.";
CM_ SG_ 2589283472 LAD_KomponentenFehler_11 "Übertragung OBD relevanter Fehlerpfade vom Secondary zum Primary Steuergerät. 
Zuordnung der generischen Komponentenfehler muss zwischen Sender und Empfänger abgestimmt werden.";
CM_ SG_ 2589283472 LAD_KomponentenFehler_12 "Übertragung OBD relevanter Fehlerpfade vom Secondary zum Primary Steuergerät. 
Zuordnung der generischen Komponentenfehler muss zwischen Sender und Empfänger abgestimmt werden.";
CM_ SG_ 2589283472 LAD_KomponentenFehler_13 "Übertragung OBD relevanter Fehlerpfade vom Secondary zum Primary Steuergerät. 
Zuordnung der generischen Komponentenfehler muss zwischen Sender und Empfänger abgestimmt werden.";
CM_ SG_ 2589283472 LAD_KomponentenFehler_14 "Übertragung OBD relevanter Fehlerpfade vom Secondary zum Primary Steuergerät. 
Zuordnung der generischen Komponentenfehler muss zwischen Sender und Empfänger abgestimmt werden.";
CM_ SG_ 2589283472 LAD_KomponentenFehler_15 "Übertragung OBD relevanter Fehlerpfade vom Secondary zum Primary Steuergerät. 
Zuordnung der generischen Komponentenfehler muss zwischen Sender und Empfänger abgestimmt werden.";
CM_ SG_ 2589283472 LAD_KomponentenFehler_16 "Übertragung OBD relevanter Fehlerpfade vom Secondary zum Primary Steuergerät. 
Zuordnung der generischen Komponentenfehler muss zwischen Sender und Empfänger abgestimmt werden.";
CM_ SG_ 2589283472 LAD_KomponentenFehler_17 "Übertragung OBD relevanter Fehlerpfade vom Secondary zum Primary Steuergerät. 
Zuordnung der generischen Komponentenfehler muss zwischen Sender und Empfänger abgestimmt werden.";
CM_ SG_ 2589283472 LAD_KomponentenFehler_18 "Übertragung OBD relevanter Fehlerpfade vom Secondary zum Primary Steuergerät. 
Zuordnung der generischen Komponentenfehler muss zwischen Sender und Empfänger abgestimmt werden.";
CM_ SG_ 2589283472 LAD_KomponentenFehler_19 "Übertragung OBD relevanter Fehlerpfade vom Secondary zum Primary Steuergerät. 
Zuordnung der generischen Komponentenfehler muss zwischen Sender und Empfänger abgestimmt werden.";
CM_ SG_ 2589283472 LAD_KomponentenFehler_20 "Übertragung OBD relevanter Fehlerpfade vom Secondary zum Primary Steuergerät. 
Zuordnung der generischen Komponentenfehler muss zwischen Sender und Empfänger abgestimmt werden.";
CM_ SG_ 2589283472 LAD_KomponentenFehler_21 "Übertragung OBD relevanter Fehlerpfade vom Secondary zum Primary Steuergerät. 
Zuordnung der generischen Komponentenfehler muss zwischen Sender und Empfänger abgestimmt werden.";
CM_ SG_ 2589283472 LAD_KomponentenFehler_22 "Übertragung OBD relevanter Fehlerpfade vom Secondary zum Primary Steuergerät. 
Zuordnung der generischen Komponentenfehler muss zwischen Sender und Empfänger abgestimmt werden.";
CM_ SG_ 2589283472 LAD_KomponentenFehler_23 "Übertragung OBD relevanter Fehlerpfade vom Secondary zum Primary Steuergerät. 
Zuordnung der generischen Komponentenfehler muss zwischen Sender und Empfänger abgestimmt werden.";
CM_ SG_ 2589283472 LAD_KomponentenFehler_24 "Übertragung OBD relevanter Fehlerpfade vom Secondary zum Primary Steuergerät. 
Zuordnung der generischen Komponentenfehler muss zwischen Sender und Empfänger abgestimmt werden.";
CM_ SG_ 2589283472 LAD_KomponentenFehler_25 "Übertragung OBD relevanter Fehlerpfade vom Secondary zum Primary Steuergerät. 
Zuordnung der generischen Komponentenfehler muss zwischen Sender und Empfänger abgestimmt werden.";
CM_ SG_ 2589283472 LAD_KomponentenFehler_26 "Übertragung OBD relevanter Fehlerpfade vom Secondary zum Primary Steuergerät. 
Zuordnung der generischen Komponentenfehler muss zwischen Sender und Empfänger abgestimmt werden.";
CM_ SG_ 2589283472 LAD_KomponentenFehler_27 "Übertragung OBD relevanter Fehlerpfade vom Secondary zum Primary Steuergerät. 
Zuordnung der generischen Komponentenfehler muss zwischen Sender und Empfänger abgestimmt werden.";
CM_ SG_ 2589283472 LAD_KomponentenFehler_28 "Übertragung OBD relevanter Fehlerpfade vom Secondary zum Primary Steuergerät. 
Zuordnung der generischen Komponentenfehler muss zwischen Sender und Empfänger abgestimmt werden.";
CM_ SG_ 2589283472 LAD_KomponentenFehler_29 "Übertragung OBD relevanter Fehlerpfade vom Secondary zum Primary Steuergerät. 
Zuordnung der generischen Komponentenfehler muss zwischen Sender und Empfänger abgestimmt werden.";
CM_ SG_ 2589283472 LAD_KomponentenFehler_30 "Übertragung OBD relevanter Fehlerpfade vom Secondary zum Primary Steuergerät. 
Zuordnung der generischen Komponentenfehler muss zwischen Sender und Empfänger abgestimmt werden.";
CM_ SG_ 2589283472 LAD_KomponentenFehler_31 "Übertragung OBD relevanter Fehlerpfade vom Secondary zum Primary Steuergerät. 
Zuordnung der generischen Komponentenfehler muss zwischen Sender und Empfänger abgestimmt werden.";
CM_ SG_ 2589283472 LAD_KomponentenFehler_32 "Übertragung OBD relevanter Fehlerpfade vom Secondary zum Primary Steuergerät. 
Zuordnung der generischen Komponentenfehler muss zwischen Sender und Empfänger abgestimmt werden.";

CM_ SG_ 2589283473 LAD_KomponentenFehler_33 "Übertragung OBD relevanter Fehlerpfade vom Secondary zum Primary Steuergerät. 
Zuordnung der generischen Komponentenfehler muss zwischen Sender und Empfänger abgestimmt werden.";
CM_ SG_ 2589283473 LAD_KomponentenFehler_34 "Übertragung OBD relevanter Fehlerpfade vom Secondary zum Primary Steuergerät. 
Zuordnung der generischen Komponentenfehler muss zwischen Sender und Empfänger abgestimmt werden.";
CM_ SG_ 2589283473 LAD_KomponentenFehler_35 "Übertragung OBD relevanter Fehlerpfade vom Secondary zum Primary Steuergerät. 
Zuordnung der generischen Komponentenfehler muss zwischen Sender und Empfänger abgestimmt werden.";
CM_ SG_ 2589283473 LAD_KomponentenFehler_36 "Übertragung OBD relevanter Fehlerpfade vom Secondary zum Primary Steuergerät. 
Zuordnung der generischen Komponentenfehler muss zwischen Sender und Empfänger abgestimmt werden.";
CM_ SG_ 2589283473 LAD_KomponentenFehler_37 "Übertragung OBD relevanter Fehlerpfade vom Secondary zum Primary Steuergerät. 
Zuordnung der generischen Komponentenfehler muss zwischen Sender und Empfänger abgestimmt werden.";
CM_ SG_ 2589283473 LAD_KomponentenFehler_38 "Übertragung OBD relevanter Fehlerpfade vom Secondary zum Primary Steuergerät. 
Zuordnung der generischen Komponentenfehler muss zwischen Sender und Empfänger abgestimmt werden.";
CM_ SG_ 2589283473 LAD_KomponentenFehler_39 "Übertragung OBD relevanter Fehlerpfade vom Secondary zum Primary Steuergerät. 
Zuordnung der generischen Komponentenfehler muss zwischen Sender und Empfänger abgestimmt werden.";
CM_ SG_ 2589283473 LAD_KomponentenFehler_40 "Übertragung OBD relevanter Fehlerpfade vom Secondary zum Primary Steuergerät. 
Zuordnung der generischen Komponentenfehler muss zwischen Sender und Empfänger abgestimmt werden.";
CM_ SG_ 2589283473 LAD_KomponentenFehler_41 "Übertragung OBD relevanter Fehlerpfade vom Secondary zum Primary Steuergerät. 
Zuordnung der generischen Komponentenfehler muss zwischen Sender und Empfänger abgestimmt werden.";
CM_ SG_ 2589283473 LAD_KomponentenFehler_42 "Übertragung OBD relevanter Fehlerpfade vom Secondary zum Primary Steuergerät. 
Zuordnung der generischen Komponentenfehler muss zwischen Sender und Empfänger abgestimmt werden.";
CM_ SG_ 2589283473 LAD_KomponentenFehler_43 "Übertragung OBD relevanter Fehlerpfade vom Secondary zum Primary Steuergerät. 
Zuordnung der generischen Komponentenfehler muss zwischen Sender und Empfänger abgestimmt werden.";
CM_ SG_ 2589283473 LAD_KomponentenFehler_44 "Übertragung OBD relevanter Fehlerpfade vom Secondary zum Primary Steuergerät. 
Zuordnung der generischen Komponentenfehler muss zwischen Sender und Empfänger abgestimmt werden.";
CM_ SG_ 2589283473 LAD_KomponentenFehler_45 "Übertragung OBD relevanter Fehlerpfade vom Secondary zum Primary Steuergerät. 
Zuordnung der generischen Komponentenfehler muss zwischen Sender und Empfänger abgestimmt werden.";
CM_ SG_ 2589283473 LAD_KomponentenFehler_46 "Übertragung OBD relevanter Fehlerpfade vom Secondary zum Primary Steuergerät. 
Zuordnung der generischen Komponentenfehler muss zwischen Sender und Empfänger abgestimmt werden.";
CM_ SG_ 2589283473 LAD_KomponentenFehler_47 "Übertragung OBD relevanter Fehlerpfade vom Secondary zum Primary Steuergerät. 
Zuordnung der generischen Komponentenfehler muss zwischen Sender und Empfänger abgestimmt werden.";
CM_ SG_ 2589283473 LAD_KomponentenFehler_48 "Übertragung OBD relevanter Fehlerpfade vom Secondary zum Primary Steuergerät. 
Zuordnung der generischen Komponentenfehler muss zwischen Sender und Empfänger abgestimmt werden.";
CM_ SG_ 2589283473 LAD_KomponentenFehler_49 "Übertragung OBD relevanter Fehlerpfade vom Secondary zum Primary Steuergerät. 
Zuordnung der generischen Komponentenfehler muss zwischen Sender und Empfänger abgestimmt werden.";
CM_ SG_ 2589283473 LAD_KomponentenFehler_50 "Übertragung OBD relevanter Fehlerpfade vom Secondary zum Primary Steuergerät. 
Zuordnung der generischen Komponentenfehler muss zwischen Sender und Empfänger abgestimmt werden.";
CM_ SG_ 2589283473 LAD_KomponentenFehler_51 "Übertragung OBD relevanter Fehlerpfade vom Secondary zum Primary Steuergerät. 
Zuordnung der generischen Komponentenfehler muss zwischen Sender und Empfänger abgestimmt werden.";
CM_ SG_ 2589283473 LAD_KomponentenFehler_52 "Übertragung OBD relevanter Fehlerpfade vom Secondary zum Primary Steuergerät. 
Zuordnung der generischen Komponentenfehler muss zwischen Sender und Empfänger abgestimmt werden.";
CM_ SG_ 2589283473 LAD_KomponentenFehler_53 "Übertragung OBD relevanter Fehlerpfade vom Secondary zum Primary Steuergerät. 
Zuordnung der generischen Komponentenfehler muss zwischen Sender und Empfänger abgestimmt werden.";
CM_ SG_ 2589283473 LAD_KomponentenFehler_54 "Übertragung OBD relevanter Fehlerpfade vom Secondary zum Primary Steuergerät. 
Zuordnung der generischen Komponentenfehler muss zwischen Sender und Empfänger abgestimmt werden.";
CM_ SG_ 2589283473 LAD_KomponentenFehler_55 "Übertragung OBD relevanter Fehlerpfade vom Secondary zum Primary Steuergerät. 
Zuordnung der generischen Komponentenfehler muss zwischen Sender und Empfänger abgestimmt werden.";
CM_ SG_ 2589283473 LAD_KomponentenFehler_56 "Übertragung OBD relevanter Fehlerpfade vom Secondary zum Primary Steuergerät. 
Zuordnung der generischen Komponentenfehler muss zwischen Sender und Empfänger abgestimmt werden.";
CM_ SG_ 2589283473 LAD_KomponentenFehler_57 "Übertragung OBD relevanter Fehlerpfade vom Secondary zum Primary Steuergerät. 
Zuordnung der generischen Komponentenfehler muss zwischen Sender und Empfänger abgestimmt werden.";
CM_ SG_ 2589283473 LAD_KomponentenFehler_58 "Übertragung OBD relevanter Fehlerpfade vom Secondary zum Primary Steuergerät. 
Zuordnung der generischen Komponentenfehler muss zwischen Sender und Empfänger abgestimmt werden.";
CM_ SG_ 2589283473 LAD_KomponentenFehler_59 "Übertragung OBD relevanter Fehlerpfade vom Secondary zum Primary Steuergerät. 
Zuordnung der generischen Komponentenfehler muss zwischen Sender und Empfänger abgestimmt werden.";
CM_ SG_ 2589283473 LAD_KomponentenFehler_60 "Übertragung OBD relevanter Fehlerpfade vom Secondary zum Primary Steuergerät. 
Zuordnung der generischen Komponentenfehler muss zwischen Sender und Empfänger abgestimmt werden.";
CM_ SG_ 2589283473 LAD_KomponentenFehler_61 "Übertragung OBD relevanter Fehlerpfade vom Secondary zum Primary Steuergerät. 
Zuordnung der generischen Komponentenfehler muss zwischen Sender und Empfänger abgestimmt werden.";
CM_ SG_ 2589283473 LAD_KomponentenFehler_62 "Übertragung OBD relevanter Fehlerpfade vom Secondary zum Primary Steuergerät. 
Zuordnung der generischen Komponentenfehler muss zwischen Sender und Empfänger abgestimmt werden.";
CM_ SG_ 2589283473 LAD_KomponentenFehler_63 "Übertragung OBD relevanter Fehlerpfade vom Secondary zum Primary Steuergerät. 
Zuordnung der generischen Komponentenfehler muss zwischen Sender und Empfänger abgestimmt werden.";
CM_ SG_ 2589283473 LAD_Komponentenfehler_VLD "Valid-Bit der OBD-Komponentenfehler. Das Bit wird beim Fehlerspeicher löschen zurückgenommen und erst wieder gesetzt, wenn der Fehlerspeicher vollständig gelöscht wurde. Der Primary-OBD-ECU soll damit mitgeteilt werden, ob sie den Inhalten der Komponenten";
BA_DEF_ BO_  "DiagRequest" ENUM "No", "Yes";
BA_DEF_ BO_  "DiagResponse" ENUM "No", "Yes";
BA_DEF_ BO_  "DiagState" ENUM "No", "Yes";
BA_DEF_ BO_  "GenMsgChkConstant" HEX 0 4095;
BA_DEF_ BO_  "GenMsgCycleTime" INT 0 65535;
BA_DEF_ BO_  "GenMsgCycleTimeFast" INT 0 65535;
BA_DEF_ BO_  "GenMsgDelayTime" INT 0 100000;
BA_DEF_ BO_  "GenMsgILSupport" ENUM "No", "Yes";
BA_DEF_ BO_  "GenMsgNrOfRepetition" INT 0 100;
BA_DEF_ BO_  "GenMsgPDUConstants" STRING;
BA_DEF_ BO_  "GenMsgSendType" ENUM "Cyclic", "not_used", "not_used", "not_used", "not_used", "not_used", "not_used", "IfActive", "NoMsgSendType";
BA_DEF_ BO_  "GenMsgStartDelayTime" INT 0 100000;
BA_DEF_ BO_  "NmMessage" ENUM "No", "Yes";
BA_DEF_ BO_  "NmhMessage" ENUM "No", "Yes";
BA_DEF_ BO_  "MsgType" ENUM "Application", "NM ", "NMH", "TP2.0", "ISO-TP ", "BAP", "EID", "KS", "XCP_PRE_CONFIGURED", "XCP_RUNTIME_CONFIGURED";
BA_DEF_ BO_  "VAGTP20_API" HEX 0 255;
BA_DEF_ BO_  "VAGTP20_DynConnection" ENUM "No", "Yes";
BA_DEF_ BO_  "VAGTP20_DynSetup" ENUM "No", "Yes";
BA_DEF_ BO_  "VAGTP20_StatConnection" ENUM "No", "Yes";
BA_DEF_ SG_  "GenSigActiveRepetitions" INT -2147483648 2147483647;
BA_DEF_ SG_  "GenSigInactiveValue" INT -2147483648 2147483647;
BA_DEF_ SG_  "GenSigSendType" ENUM "Cyclic", "OnWrite", "OnWriteWithRepetition", "OnChange", "OnChangeWithRepetition", "IfActive", "IfActiveWithRepetition", "NoSigSendType", "OnChangeAndIfActive", "OnChangeAndIfActiveWithRepetition";
BA_DEF_ SG_  "GenSigStartValue" INT -2147483648 2147483647;
BA_DEF_ SG_  "NWM-WakeupAllowed" ENUM "No", "Yes";
BA_DEF_ SG_  "GenSigFuncType" ENUM "NoFunction", "MsgCounter", "CRC-8", "XOR", "XOR-2", "DatedBit", "SW-Kl15", "CHK", "Constant", "Protocol", "CRC-8-SAE_J1850", "CRC-32", "DataLength", "DataID", "MsgCounter16", "SOK-Signatur", "Cluster";
BA_DEF_ SG_  "GenSigSwitchedByIgnition" ENUM "No", "Yes";
BA_DEF_ SG_  "Fehlerwert" HEX 0 2147483647;
BA_DEF_ SG_  "GenSigMissingSourceValue" HEX 0 2147483647;
BA_DEF_DEF_  "DiagRequest" "No";
BA_DEF_DEF_  "DiagResponse" "No";
BA_DEF_DEF_  "DiagState" "No";
BA_DEF_DEF_  "GenMsgChkConstant" 0;
BA_DEF_DEF_  "GenMsgCycleTime" 0;
BA_DEF_DEF_  "GenMsgCycleTimeFast" 0;
BA_DEF_DEF_  "GenMsgDelayTime" 0;
BA_DEF_DEF_  "GenMsgILSupport" "No";
BA_DEF_DEF_  "GenMsgNrOfRepetition" 0;
BA_DEF_DEF_  "GenMsgPDUConstants" "";
BA_DEF_DEF_  "GenMsgSendType" "NoMsgSendType";
BA_DEF_DEF_  "GenMsgStartDelayTime" 0;
BA_DEF_DEF_  "NmMessage" "No";
BA_DEF_DEF_  "NmhMessage" "No";
BA_DEF_DEF_  "MsgType" "Application";
BA_DEF_DEF_  "VAGTP20_API" 0;
BA_DEF_DEF_  "VAGTP20_DynConnection" "No";
BA_DEF_DEF_  "VAGTP20_DynSetup" "No";
BA_DEF_DEF_  "VAGTP20_StatConnection" "No";
BA_DEF_DEF_  "GenSigActiveRepetitions" 0;
BA_DEF_DEF_  "GenSigInactiveValue" 0;
BA_DEF_DEF_  "GenSigSendType" "NoSigSendType";
BA_DEF_DEF_  "GenSigStartValue" 0;
BA_DEF_DEF_  "NWM-WakeupAllowed" "No";
BA_DEF_DEF_  "GenSigFuncType" "NoFunction";
BA_DEF_DEF_  "GenSigSwitchedByIgnition" "Yes";
BA_DEF_DEF_  "Fehlerwert" 0;
BA_DEF_DEF_  "GenSigMissingSourceValue" 0;
BA_ "DiagRequest" BO_ 2549874869 1;
BA_ "MsgType" BO_ 2549874869 4;
BA_ "DiagResponse" BO_ 2550005941 1;
BA_ "MsgType" BO_ 2550005941 4;
BA_ "DiagRequest" BO_ 2549874811 1;
BA_ "MsgType" BO_ 2549874811 4;
BA_ "DiagResponse" BO_ 2550005883 1;
BA_ "MsgType" BO_ 2550005883 4;
BA_ "DiagRequest" BO_ 2549874886 1;
BA_ "MsgType" BO_ 2549874886 4;
BA_ "DiagResponse" BO_ 2550005958 1;
BA_ "MsgType" BO_ 2550005958 4;
BA_ "DiagRequest" BO_ 2549874868 1;
BA_ "MsgType" BO_ 2549874868 4;
BA_ "DiagResponse" BO_ 2550005940 1;
BA_ "MsgType" BO_ 2550005940 4;
BA_ "GenMsgCycleTime" BO_ 497 500;
BA_ "GenMsgCycleTimeFast" BO_ 497 40;
BA_ "GenMsgDelayTime" BO_ 497 20;
BA_ "GenMsgILSupport" BO_ 497 1;
BA_ "GenMsgNrOfRepetition" BO_ 497 7;
BA_ "GenMsgSendType" BO_ 497 0;
BA_ "GenMsgChkConstant" BO_ 960 195;
BA_ "GenMsgCycleTime" BO_ 960 100;
BA_ "GenMsgDelayTime" BO_ 960 10;
BA_ "GenMsgILSupport" BO_ 960 1;
BA_ "GenMsgPDUConstants" BO_ 960 "0xc3,0xc3,0xc3,0xc3,0xc3,0xc3,0xc3,0xc3,0xc3,0xc3,0xc3,0xc3,0xc3,0xc3,0xc3,0xc3";
BA_ "GenMsgSendType" BO_ 960 0;
BA_ "GenMsgCycleTime" BO_ 1646 2000;
BA_ "GenMsgDelayTime" BO_ 1646 200;
BA_ "GenMsgILSupport" BO_ 1646 1;
BA_ "GenMsgSendType" BO_ 1646 0;
BA_ "GenMsgCycleTime" BO_ 1649 2000;
BA_ "GenMsgDelayTime" BO_ 1649 200;
BA_ "GenMsgILSupport" BO_ 1649 1;
BA_ "GenMsgSendType" BO_ 1649 0;
BA_ "GenMsgCycleTime" BO_ 949 100;
BA_ "GenMsgILSupport" BO_ 949 1;
BA_ "GenMsgSendType" BO_ 949 0;
BA_ "GenMsgCycleTime" BO_ 1640 200;
BA_ "GenMsgCycleTimeFast" BO_ 1640 100;
BA_ "GenMsgDelayTime" BO_ 1640 25;
BA_ "GenMsgILSupport" BO_ 1640 1;
BA_ "GenMsgNrOfRepetition" BO_ 1640 5;
BA_ "GenMsgSendType" BO_ 1640 0;
BA_ "GenMsgCycleTime" BO_ 1441 500;
BA_ "GenMsgILSupport" BO_ 1441 1;
BA_ "GenMsgSendType" BO_ 1441 0;
BA_ "GenMsgCycleTime" BO_ 2589283469 1000;
BA_ "GenMsgDelayTime" BO_ 2589283469 100;
BA_ "GenMsgILSupport" BO_ 2589283469 1;
BA_ "GenMsgSendType" BO_ 2589283469 0;
BA_ "GenMsgCycleTime" BO_ 2589283621 1000;
BA_ "GenMsgDelayTime" BO_ 2589283621 100;
BA_ "GenMsgILSupport" BO_ 2589283621 1;
BA_ "GenMsgSendType" BO_ 2589283621 0;
BA_ "GenMsgCycleTime" BO_ 2463978701 100;
BA_ "GenMsgILSupport" BO_ 2463978701 1;
BA_ "GenMsgSendType" BO_ 2463978701 0;
BA_ "GenMsgCycleTime" BO_ 1712 500;
BA_ "GenMsgILSupport" BO_ 1712 1;
BA_ "GenMsgSendType" BO_ 1712 0;
BA_ "GenMsgCycleTime" BO_ 1505 200;
BA_ "GenMsgILSupport" BO_ 1505 1;
BA_ "GenMsgSendType" BO_ 1505 0;
BA_ "GenMsgCycleTime" BO_ 1717 500;
BA_ "GenMsgILSupport" BO_ 1717 1;
BA_ "GenMsgSendType" BO_ 1717 0;
BA_ "GenMsgCycleTime" BO_ 1513 200;
BA_ "GenMsgILSupport" BO_ 1513 1;
BA_ "GenMsgSendType" BO_ 1513 0;
BA_ "GenMsgCycleTime" BO_ 1295 100;
BA_ "GenMsgILSupport" BO_ 1295 1;
BA_ "GenMsgSendType" BO_ 1295 0;
BA_ "GenMsgCycleTime" BO_ 2589283474 1000;
BA_ "GenMsgDelayTime" BO_ 2589283474 100;
BA_ "GenMsgILSupport" BO_ 2589283474 1;
BA_ "GenMsgSendType" BO_ 2589283474 0;
BA_ "GenMsgCycleTime" BO_ 2463978659 100;
BA_ "GenMsgDelayTime" BO_ 2463978659 10;
BA_ "GenMsgILSupport" BO_ 2463978659 1;
BA_ "GenMsgSendType" BO_ 2463978659 0;
BA_ "GenMsgCycleTime" BO_ 2549088399 500;
BA_ "GenMsgILSupport" BO_ 2549088399 1;
BA_ "GenMsgSendType" BO_ 2549088399 0;
BA_ "GenMsgCycleTime" BO_ 2549088430 500;
BA_ "GenMsgILSupport" BO_ 2549088430 1;
BA_ "GenMsgSendType" BO_ 2549088430 0;
BA_ "GenMsgCycleTime" BO_ 2549088412 500;
BA_ "GenMsgILSupport" BO_ 2549088412 1;
BA_ "GenMsgSendType" BO_ 2549088412 0;
BA_ "GenMsgCycleTime" BO_ 2549088321 500;
BA_ "GenMsgILSupport" BO_ 2549088321 1;
BA_ "GenMsgSendType" BO_ 2549088321 0;
BA_ "GenMsgCycleTime" BO_ 2549088439 500;
BA_ "GenMsgILSupport" BO_ 2549088439 1;
BA_ "GenMsgSendType" BO_ 2549088439 0;
BA_ "GenMsgCycleTime" BO_ 2549088455 500;
BA_ "GenMsgILSupport" BO_ 2549088455 1;
BA_ "GenMsgSendType" BO_ 2549088455 0;
BA_ "GenMsgCycleTime" BO_ 2549088437 500;
BA_ "GenMsgILSupport" BO_ 2549088437 1;
BA_ "GenMsgSendType" BO_ 2549088437 0;
BA_ "GenMsgCycleTime" BO_ 2549088272 500;
BA_ "GenMsgILSupport" BO_ 2549088272 1;
BA_ "GenMsgSendType" BO_ 2549088272 0;
BA_ "GenMsgStartDelayTime" BO_ 2549088272 75;
BA_ "GenMsgCycleTime" BO_ 2549088379 500;
BA_ "GenMsgILSupport" BO_ 2549088379 1;
BA_ "GenMsgSendType" BO_ 2549088379 0;
BA_ "GenMsgCycleTime" BO_ 2549088324 500;
BA_ "GenMsgILSupport" BO_ 2549088324 1;
BA_ "GenMsgSendType" BO_ 2549088324 0;
BA_ "GenMsgCycleTime" BO_ 2549088454 500;
BA_ "GenMsgILSupport" BO_ 2549088454 1;
BA_ "GenMsgSendType" BO_ 2549088454 0;
BA_ "GenMsgCycleTime" BO_ 2549088257 500;
BA_ "GenMsgILSupport" BO_ 2549088257 1;
BA_ "GenMsgSendType" BO_ 2549088257 0;
BA_ "GenMsgCycleTime" BO_ 2549088259 500;
BA_ "GenMsgILSupport" BO_ 2549088259 1;
BA_ "GenMsgSendType" BO_ 2549088259 0;
BA_ "GenMsgCycleTime" BO_ 2549088329 500;
BA_ "GenMsgILSupport" BO_ 2549088329 1;
BA_ "GenMsgSendType" BO_ 2549088329 0;
BA_ "GenMsgCycleTime" BO_ 2549088322 500;
BA_ "GenMsgILSupport" BO_ 2549088322 1;
BA_ "GenMsgSendType" BO_ 2549088322 0;
BA_ "GenMsgCycleTime" BO_ 779 50;
BA_ "GenMsgILSupport" BO_ 779 1;
BA_ "GenMsgSendType" BO_ 779 0;
BA_ "GenMsgCycleTime" BO_ 1719 1000;
BA_ "GenMsgDelayTime" BO_ 1719 100;
BA_ "GenMsgILSupport" BO_ 1719 1;
BA_ "GenMsgSendType" BO_ 1719 0;
BA_ "MsgType" BO_ 2549875067 4;
BA_ "MsgType" BO_ 2550006139 4;
BA_ "MsgType" BO_ 2549875142 4;
BA_ "MsgType" BO_ 2550006214 4;
BA_ "MsgType" BO_ 2549875012 4;
BA_ "MsgType" BO_ 2550006084 4;
BA_ "MsgType" BO_ 2549899473 4;
BA_ "MsgType" BO_ 2550030545 4;
BA_ "MsgType" BO_ 2549899474 4;
BA_ "MsgType" BO_ 2550030546 4;
BA_ "MsgType" BO_ 2549899475 4;
BA_ "MsgType" BO_ 2550030547 4;
BA_ "MsgType" BO_ 2549899476 4;
BA_ "MsgType" BO_ 2550030548 4;
BA_ "MsgType" BO_ 2549899477 4;
BA_ "MsgType" BO_ 2550030549 4;
BA_ "MsgType" BO_ 2549899478 4;
BA_ "MsgType" BO_ 2550030550 4;
BA_ "MsgType" BO_ 2549899479 4;
BA_ "MsgType" BO_ 2550030551 4;
BA_ "MsgType" BO_ 2549899480 4;
BA_ "MsgType" BO_ 2550030552 4;
BA_ "MsgType" BO_ 2549899481 4;
BA_ "MsgType" BO_ 2550030553 4;
BA_ "MsgType" BO_ 2549899482 4;
BA_ "MsgType" BO_ 2550030554 4;
BA_ "MsgType" BO_ 2549899483 4;
BA_ "MsgType" BO_ 2550030555 4;
BA_ "MsgType" BO_ 2549899484 4;
BA_ "MsgType" BO_ 2550030556 4;
BA_ "MsgType" BO_ 2549899505 4;
BA_ "MsgType" BO_ 2550030577 4;
BA_ "MsgType" BO_ 2549899506 4;
BA_ "MsgType" BO_ 2550030578 4;
BA_ "MsgType" BO_ 2549899507 4;
BA_ "MsgType" BO_ 2550030579 4;
BA_ "GenMsgCycleTime" BO_ 2463978640 100;
BA_ "GenMsgILSupport" BO_ 2463978640 1;
BA_ "GenMsgPDUConstants" BO_ 2463978640 "0x48,0x52,0xa7,0xe6,0x83,0x2b,0x8c,0xfb,0x7b,0x64,0x58,0x50,0xbc,0xb3,0x0f,0x9c";
BA_ "GenMsgSendType" BO_ 2463978640 0;
BA_ "GenMsgCycleTime" BO_ 2463978644 100;
BA_ "GenMsgILSupport" BO_ 2463978644 1;
BA_ "GenMsgSendType" BO_ 2463978644 0;
BA_ "GenMsgCycleTime" BO_ 2463978645 100;
BA_ "GenMsgILSupport" BO_ 2463978645 1;
BA_ "GenMsgSendType" BO_ 2463978645 0;
BA_ "GenMsgCycleTime" BO_ 2589283493 1000;
BA_ "GenMsgILSupport" BO_ 2589283493 1;
BA_ "GenMsgSendType" BO_ 2589283493 0;
BA_ "GenMsgCycleTime" BO_ 2589283392 500;
BA_ "GenMsgILSupport" BO_ 2589283392 1;
BA_ "GenMsgSendType" BO_ 2589283392 0;
BA_ "GenMsgCycleTime" BO_ 2589283688 1000;
BA_ "GenMsgILSupport" BO_ 2589283688 1;
BA_ "GenMsgSendType" BO_ 2589283688 0;
BA_ "GenMsgChkConstant" BO_ 1380 36;
BA_ "GenMsgCycleTime" BO_ 1380 1000;
BA_ "GenMsgCycleTimeFast" BO_ 1380 100;
BA_ "GenMsgDelayTime" BO_ 1380 100;
BA_ "GenMsgILSupport" BO_ 1380 1;
BA_ "GenMsgNrOfRepetition" BO_ 1380 5;
BA_ "GenMsgPDUConstants" BO_ 1380 "0x24,0x24,0x24,0x24,0x24,0x24,0x24,0x24,0x24,0x24,0x24,0x24,0x24,0x24,0x24,0x24";
BA_ "GenMsgSendType" BO_ 1380 0;
BA_ "GenMsgChkConstant" BO_ 1662 37;
BA_ "GenMsgCycleTime" BO_ 1662 1000;
BA_ "GenMsgDelayTime" BO_ 1662 50;
BA_ "GenMsgILSupport" BO_ 1662 1;
BA_ "GenMsgPDUConstants" BO_ 1662 "0x25,0x25,0x25,0x25,0x25,0x25,0x25,0x25,0x25,0x25,0x25,0x25,0x25,0x25,0x25,0x25";
BA_ "GenMsgSendType" BO_ 1662 0;
BA_ "GenMsgCycleTime" BO_ 2463978642 100;
BA_ "GenMsgILSupport" BO_ 2463978642 1;
BA_ "GenMsgSendType" BO_ 2463978642 0;
BA_ "GenMsgCycleTime" BO_ 2463978643 100;
BA_ "GenMsgILSupport" BO_ 2463978643 1;
BA_ "GenMsgPDUConstants" BO_ 2463978643 "0x74,0x7e,0x45,0xe8,0x3c,0xd0,0x13,0x1f,0x4e,0x3a,0x88,0x0b,0x7d,0xd2,0x6d,0xab";
BA_ "GenMsgSendType" BO_ 2463978643 0;
BA_ "GenMsgCycleTime" BO_ 2589283663 1000;
BA_ "GenMsgDelayTime" BO_ 2589283663 100;
BA_ "GenMsgILSupport" BO_ 2589283663 1;
BA_ "GenMsgSendType" BO_ 2589283663 0;
BA_ "GenMsgCycleTime" BO_ 2589283415 1000;
BA_ "GenMsgILSupport" BO_ 2589283415 1;
BA_ "GenMsgSendType" BO_ 2589283415 0;
BA_ "GenMsgCycleTime" BO_ 2589283472 500;
BA_ "GenMsgILSupport" BO_ 2589283472 1;
BA_ "GenMsgSendType" BO_ 2589283472 0;
BA_ "GenMsgCycleTime" BO_ 2589283473 500;
BA_ "GenMsgILSupport" BO_ 2589283473 1;
BA_ "GenMsgSendType" BO_ 2589283473 0;
BA_ "GenSigSendType" SG_ 2549874869 ISOx_FCU_Req_Data 3;
BA_ "GenSigFuncType" SG_ 2549874869 ISOx_FCU_Req_Data 9;
BA_ "GenSigSwitchedByIgnition" SG_ 2549874869 ISOx_FCU_Req_Data 0;
BA_ "GenSigSendType" SG_ 2550005941 ISOx_FCU_Resp_Data 3;
BA_ "GenSigFuncType" SG_ 2550005941 ISOx_FCU_Resp_Data 9;
BA_ "GenSigSwitchedByIgnition" SG_ 2550005941 ISOx_FCU_Resp_Data 0;
BA_ "GenSigSendType" SG_ 2549874811 ISOx_Hybrid_01_Req_Data 3;
BA_ "GenSigFuncType" SG_ 2549874811 ISOx_Hybrid_01_Req_Data 9;
BA_ "GenSigSwitchedByIgnition" SG_ 2549874811 ISOx_Hybrid_01_Req_Data 0;
BA_ "GenSigSendType" SG_ 2550005883 ISOx_Hybrid_01_Resp_Data 3;
BA_ "GenSigFuncType" SG_ 2550005883 ISOx_Hybrid_01_Resp_Data 9;
BA_ "GenSigSwitchedByIgnition" SG_ 2550005883 ISOx_Hybrid_01_Resp_Data 0;
BA_ "GenSigSendType" SG_ 2549874886 ISOx_Ladegeraet_2_Req_Data 3;
BA_ "GenSigFuncType" SG_ 2549874886 ISOx_Ladegeraet_2_Req_Data 9;
BA_ "GenSigSwitchedByIgnition" SG_ 2549874886 ISOx_Ladegeraet_2_Req_Data 0;
BA_ "GenSigSendType" SG_ 2550005958 ISOx_Ladegeraet_2_Resp_Data 3;
BA_ "GenSigFuncType" SG_ 2550005958 ISOx_Ladegeraet_2_Resp_Data 9;
BA_ "GenSigSwitchedByIgnition" SG_ 2550005958 ISOx_Ladegeraet_2_Resp_Data 0;
BA_ "GenSigSendType" SG_ 2549874868 ISOx_TelemetrieSG_Req_Data 3;
BA_ "GenSigFuncType" SG_ 2549874868 ISOx_TelemetrieSG_Req_Data 9;
BA_ "GenSigSwitchedByIgnition" SG_ 2549874868 ISOx_TelemetrieSG_Req_Data 0;
BA_ "GenSigSendType" SG_ 2550005940 ISOx_TelemetrieSG_Resp_Data 3;
BA_ "GenSigFuncType" SG_ 2550005940 ISOx_TelemetrieSG_Resp_Data 9;
BA_ "GenSigSwitchedByIgnition" SG_ 2550005940 ISOx_TelemetrieSG_Resp_Data 0;
BA_ "GenSigActiveRepetitions" SG_ 497 FBS_Aktivierung_Pilot_Parken 7;
BA_ "GenSigSendType" SG_ 497 FBS_Aktivierung_Pilot_Parken 2;
BA_ "GenSigSwitchedByIgnition" SG_ 497 FBS_Aktivierung_Pilot_Parken 0;
BA_ "GenSigActiveRepetitions" SG_ 497 FFB_FDF_Taste 7;
BA_ "GenSigSendType" SG_ 497 FFB_FDF_Taste 2;
BA_ "GenSigSwitchedByIgnition" SG_ 497 FFB_FDF_Taste 0;
BA_ "GenSigActiveRepetitions" SG_ 497 FFB_Joker_Taste 7;
BA_ "GenSigSendType" SG_ 497 FFB_Joker_Taste 2;
BA_ "GenSigSwitchedByIgnition" SG_ 497 FFB_Joker_Taste 0;
BA_ "GenSigActiveRepetitions" SG_ 497 FFB_Park_Taste 7;
BA_ "GenSigSendType" SG_ 497 FFB_Park_Taste 2;
BA_ "GenSigSwitchedByIgnition" SG_ 497 FFB_Park_Taste 0;
BA_ "GenSigActiveRepetitions" SG_ 497 FFB_Remotestart_Taste 7;
BA_ "GenSigSendType" SG_ 497 FFB_Remotestart_Taste 2;
BA_ "GenSigSwitchedByIgnition" SG_ 497 FFB_Remotestart_Taste 0;
BA_ "GenSigActiveRepetitions" SG_ 497 KY_Auf_Taste 7;
BA_ "GenSigSendType" SG_ 497 KY_Auf_Taste 2;
BA_ "GenSigSwitchedByIgnition" SG_ 497 KY_Auf_Taste 0;
BA_ "GenSigActiveRepetitions" SG_ 497 KY_Bereich 7;
BA_ "GenSigSendType" SG_ 497 KY_Bereich 2;
BA_ "GenSigStartValue" SG_ 497 KY_Bereich 7;
BA_ "GenSigSwitchedByIgnition" SG_ 497 KY_Bereich 0;
BA_ "GenSigActiveRepetitions" SG_ 497 KY_BT_Entriegelung_Autorisiert 7;
BA_ "GenSigSendType" SG_ 497 KY_BT_Entriegelung_Autorisiert 2;
BA_ "GenSigSwitchedByIgnition" SG_ 497 KY_BT_Entriegelung_Autorisiert 0;
BA_ "GenSigActiveRepetitions" SG_ 497 KY_BT_Verriegelung_Autorisiert 7;
BA_ "GenSigSendType" SG_ 497 KY_BT_Verriegelung_Autorisiert 2;
BA_ "GenSigSwitchedByIgnition" SG_ 497 KY_BT_Verriegelung_Autorisiert 0;
BA_ "GenSigSendType" SG_ 497 KY_EasyClose_Abbruch 3;
BA_ "GenSigSwitchedByIgnition" SG_ 497 KY_EasyClose_Abbruch 0;
BA_ "GenSigSendType" SG_ 497 KY_EasyClose_Status 3;
BA_ "GenSigSwitchedByIgnition" SG_ 497 KY_EasyClose_Status 0;
BA_ "GenSigActiveRepetitions" SG_ 497 KY_Front_Entr_Autorisiert 7;
BA_ "GenSigSendType" SG_ 497 KY_Front_Entr_Autorisiert 2;
BA_ "GenSigSwitchedByIgnition" SG_ 497 KY_Front_Entr_Autorisiert 0;
BA_ "GenSigActiveRepetitions" SG_ 497 KY_Front_Verr_Autorisiert 7;
BA_ "GenSigSendType" SG_ 497 KY_Front_Verr_Autorisiert 2;
BA_ "GenSigSwitchedByIgnition" SG_ 497 KY_Front_Verr_Autorisiert 0;
BA_ "GenSigActiveRepetitions" SG_ 497 KY_FT_Entriegelung_Autorisiert 7;
BA_ "GenSigSendType" SG_ 497 KY_FT_Entriegelung_Autorisiert 2;
BA_ "GenSigSwitchedByIgnition" SG_ 497 KY_FT_Entriegelung_Autorisiert 0;
BA_ "GenSigActiveRepetitions" SG_ 497 KY_FT_Verriegelung_Autorisiert 7;
BA_ "GenSigSendType" SG_ 497 KY_FT_Verriegelung_Autorisiert 2;
BA_ "GenSigSwitchedByIgnition" SG_ 497 KY_FT_Verriegelung_Autorisiert 0;
BA_ "GenSigActiveRepetitions" SG_ 497 KY_HBFS_Entriegelung_Autorisiert 7;
BA_ "GenSigSendType" SG_ 497 KY_HBFS_Entriegelung_Autorisiert 2;
BA_ "GenSigSwitchedByIgnition" SG_ 497 KY_HBFS_Entriegelung_Autorisiert 0;
BA_ "GenSigActiveRepetitions" SG_ 497 KY_HBFS_Verriegelung_Autorisiert 7;
BA_ "GenSigSendType" SG_ 497 KY_HBFS_Verriegelung_Autorisiert 2;
BA_ "GenSigSwitchedByIgnition" SG_ 497 KY_HBFS_Verriegelung_Autorisiert 0;
BA_ "GenSigActiveRepetitions" SG_ 497 KY_HD_Auffahrt 7;
BA_ "GenSigSendType" SG_ 497 KY_HD_Auffahrt 2;
BA_ "GenSigSwitchedByIgnition" SG_ 497 KY_HD_Auffahrt 0;
BA_ "GenSigActiveRepetitions" SG_ 497 KY_HD_Entriegelung_Autorisiert 7;
BA_ "GenSigSendType" SG_ 497 KY_HD_Entriegelung_Autorisiert 2;
BA_ "GenSigSwitchedByIgnition" SG_ 497 KY_HD_Entriegelung_Autorisiert 0;
BA_ "GenSigActiveRepetitions" SG_ 497 KY_HD_Verriegelung_Autorisiert 7;
BA_ "GenSigSendType" SG_ 497 KY_HD_Verriegelung_Autorisiert 2;
BA_ "GenSigSwitchedByIgnition" SG_ 497 KY_HD_Verriegelung_Autorisiert 0;
BA_ "GenSigActiveRepetitions" SG_ 497 KY_HD_Zufahrt 7;
BA_ "GenSigSendType" SG_ 497 KY_HD_Zufahrt 2;
BA_ "GenSigSwitchedByIgnition" SG_ 497 KY_HD_Zufahrt 0;
BA_ "GenSigActiveRepetitions" SG_ 497 KY_HDF_Taste 7;
BA_ "GenSigSendType" SG_ 497 KY_HDF_Taste 2;
BA_ "GenSigSwitchedByIgnition" SG_ 497 KY_HDF_Taste 0;
BA_ "GenSigActiveRepetitions" SG_ 497 KY_HFS_Entriegelung_Autorisiert 7;
BA_ "GenSigSendType" SG_ 497 KY_HFS_Entriegelung_Autorisiert 2;
BA_ "GenSigSwitchedByIgnition" SG_ 497 KY_HFS_Entriegelung_Autorisiert 0;
BA_ "GenSigActiveRepetitions" SG_ 497 KY_HFS_Verriegelung_Autorisiert 7;
BA_ "GenSigSendType" SG_ 497 KY_HFS_Verriegelung_Autorisiert 2;
BA_ "GenSigSwitchedByIgnition" SG_ 497 KY_HFS_Verriegelung_Autorisiert 0;
BA_ "GenSigActiveRepetitions" SG_ 497 KY_IDG_in_Reichweite 7;
BA_ "GenSigSendType" SG_ 497 KY_IDG_in_Reichweite 2;
BA_ "GenSigSwitchedByIgnition" SG_ 497 KY_IDG_in_Reichweite 0;
BA_ "GenSigActiveRepetitions" SG_ 497 KY_LKL_1_Autorisierung 7;
BA_ "GenSigSendType" SG_ 497 KY_LKL_1_Autorisierung 2;
BA_ "GenSigSwitchedByIgnition" SG_ 497 KY_LKL_1_Autorisierung 0;
BA_ "GenSigActiveRepetitions" SG_ 497 KY_LKL_2_Autorisierung 7;
BA_ "GenSigSendType" SG_ 497 KY_LKL_2_Autorisierung 2;
BA_ "GenSigSwitchedByIgnition" SG_ 497 KY_LKL_2_Autorisierung 0;
BA_ "GenSigActiveRepetitions" SG_ 497 KY_Panik_Taste 7;
BA_ "GenSigSendType" SG_ 497 KY_Panik_Taste 2;
BA_ "GenSigSwitchedByIgnition" SG_ 497 KY_Panik_Taste 0;
BA_ "GenSigActiveRepetitions" SG_ 497 KY_Position 7;
BA_ "GenSigSendType" SG_ 497 KY_Position 2;
BA_ "GenSigStartValue" SG_ 497 KY_Position 7;
BA_ "GenSigSwitchedByIgnition" SG_ 497 KY_Position 0;
BA_ "GenSigActiveRepetitions" SG_ 497 KY_Schluessel_im_Fzg 7;
BA_ "GenSigSendType" SG_ 497 KY_Schluessel_im_Fzg 2;
BA_ "GenSigSwitchedByIgnition" SG_ 497 KY_Schluessel_im_Fzg 0;
BA_ "GenSigActiveRepetitions" SG_ 497 KY_Zu_Taste 7;
BA_ "GenSigSendType" SG_ 497 KY_Zu_Taste 2;
BA_ "GenSigSwitchedByIgnition" SG_ 497 KY_Zu_Taste 0;
BA_ "GenSigActiveRepetitions" SG_ 497 KY_ZV_Signatur 7;
BA_ "GenSigSendType" SG_ 497 KY_ZV_Signatur 2;
BA_ "GenSigSwitchedByIgnition" SG_ 497 KY_ZV_Signatur 0;
BA_ "GenSigActiveRepetitions" SG_ 497 Schluesselnr_Personalisierung 7;
BA_ "GenSigSendType" SG_ 497 Schluesselnr_Personalisierung 2;
BA_ "GenSigStartValue" SG_ 497 Schluesselnr_Personalisierung 14;
BA_ "GenSigSwitchedByIgnition" SG_ 497 Schluesselnr_Personalisierung 0;
BA_ "Fehlerwert" SG_ 497 Schluesselnr_Personalisierung 15;
BA_ "GenSigSendType" SG_ 960 BCM_Ausparken_Betrieb 3;
BA_ "GenSigSwitchedByIgnition" SG_ 960 BCM_Ausparken_Betrieb 0;
BA_ "GenSigSendType" SG_ 960 BCM_Remotestart_Betrieb 3;
BA_ "GenSigSwitchedByIgnition" SG_ 960 BCM_Remotestart_Betrieb 0;
BA_ "GenSigSendType" SG_ 960 BCM_Remotestart_KL15_Anf 3;
BA_ "GenSigSwitchedByIgnition" SG_ 960 BCM_Remotestart_KL15_Anf 0;
BA_ "GenSigSendType" SG_ 960 BCM_Remotestart_MO_Start 3;
BA_ "GenSigSwitchedByIgnition" SG_ 960 BCM_Remotestart_MO_Start 0;
BA_ "GenSigSendType" SG_ 960 Klemmen_Status_01_BZ 0;
BA_ "GenSigFuncType" SG_ 960 Klemmen_Status_01_BZ 1;
BA_ "GenSigSwitchedByIgnition" SG_ 960 Klemmen_Status_01_BZ 0;
BA_ "GenSigSendType" SG_ 960 Klemmen_Status_01_CRC 0;
BA_ "GenSigFuncType" SG_ 960 Klemmen_Status_01_CRC 2;
BA_ "GenSigSwitchedByIgnition" SG_ 960 Klemmen_Status_01_CRC 0;
BA_ "GenSigSendType" SG_ 960 KST_Fahrerhinweis_1 3;
BA_ "GenSigSwitchedByIgnition" SG_ 960 KST_Fahrerhinweis_1 0;
BA_ "GenSigSendType" SG_ 960 KST_Fahrerhinweis_2 3;
BA_ "GenSigSwitchedByIgnition" SG_ 960 KST_Fahrerhinweis_2 0;
BA_ "GenSigSendType" SG_ 960 KST_Fahrerhinweis_4 3;
BA_ "GenSigSwitchedByIgnition" SG_ 960 KST_Fahrerhinweis_4 0;
BA_ "GenSigSendType" SG_ 960 KST_Fahrerhinweis_5 3;
BA_ "GenSigSwitchedByIgnition" SG_ 960 KST_Fahrerhinweis_5 0;
BA_ "GenSigSendType" SG_ 960 KST_Fahrerhinweis_6 3;
BA_ "GenSigSwitchedByIgnition" SG_ 960 KST_Fahrerhinweis_6 0;
BA_ "GenSigSendType" SG_ 960 KST_Warn_P1_ZST_def 3;
BA_ "GenSigSwitchedByIgnition" SG_ 960 KST_Warn_P1_ZST_def 0;
BA_ "GenSigSendType" SG_ 960 KST_Warn_P2_ZST_def 3;
BA_ "GenSigSwitchedByIgnition" SG_ 960 KST_Warn_P2_ZST_def 0;
BA_ "GenSigSendType" SG_ 960 RSt_Fahrerhinweise 3;
BA_ "GenSigSwitchedByIgnition" SG_ 960 RSt_Fahrerhinweise 0;
BA_ "GenSigSendType" SG_ 960 ZAS_Kl_15 3;
BA_ "NWM-WakeupAllowed" SG_ 960 ZAS_Kl_15 1;
BA_ "GenSigFuncType" SG_ 960 ZAS_Kl_15 6;
BA_ "GenSigSwitchedByIgnition" SG_ 960 ZAS_Kl_15 0;
BA_ "GenSigSendType" SG_ 960 ZAS_Kl_50_Startanforderung 3;
BA_ "GenSigSwitchedByIgnition" SG_ 960 ZAS_Kl_50_Startanforderung 0;
BA_ "GenSigSendType" SG_ 960 ZAS_Kl_Infotainment 3;
BA_ "GenSigSwitchedByIgnition" SG_ 960 ZAS_Kl_Infotainment 0;
BA_ "GenSigSendType" SG_ 960 ZAS_Kl_S 3;
BA_ "GenSigSwitchedByIgnition" SG_ 960 ZAS_Kl_S 0;
BA_ "GenSigSendType" SG_ 960 ZAS_Kl_X 3;
BA_ "GenSigSwitchedByIgnition" SG_ 960 ZAS_Kl_X 0;
BA_ "GenSigSendType" SG_ 1646 KL_Anf_AussenspiegelHzg 3;
BA_ "GenSigSwitchedByIgnition" SG_ 1646 KL_Anf_AussenspiegelHzg 0;
BA_ "GenSigSendType" SG_ 1646 KL_BCmE_Livetip_Freigabe 3;
BA_ "GenSigSwitchedByIgnition" SG_ 1646 KL_BCmE_Livetip_Freigabe 0;
BA_ "GenSigSendType" SG_ 1646 KL_ErwVK_Anf 3;
BA_ "GenSigSwitchedByIgnition" SG_ 1646 KL_ErwVK_Anf 0;
BA_ "GenSigSendType" SG_ 1646 KL_ErwVK_Zusatzrelais 3;
BA_ "GenSigSwitchedByIgnition" SG_ 1646 KL_ErwVK_Zusatzrelais 0;
BA_ "GenSigSendType" SG_ 1646 KL_FSH_Automatikbetrieb 3;
BA_ "GenSigSwitchedByIgnition" SG_ 1646 KL_FSH_Automatikbetrieb 0;
BA_ "GenSigSendType" SG_ 1646 KL_Geblaese_Fond_Status 0;
BA_ "GenSigStartValue" SG_ 1646 KL_Geblaese_Fond_Status 14;
BA_ "GenSigSwitchedByIgnition" SG_ 1646 KL_Geblaese_Fond_Status 0;
BA_ "Fehlerwert" SG_ 1646 KL_Geblaese_Fond_Status 15;
BA_ "GenSigSendType" SG_ 1646 KL_Geblaese_Status 0;
BA_ "GenSigStartValue" SG_ 1646 KL_Geblaese_Status 14;
BA_ "GenSigSwitchedByIgnition" SG_ 1646 KL_Geblaese_Status 0;
BA_ "Fehlerwert" SG_ 1646 KL_Geblaese_Status 15;
BA_ "GenSigSendType" SG_ 1646 KL_Heizkreisventilstellung 0;
BA_ "GenSigSwitchedByIgnition" SG_ 1646 KL_Heizkreisventilstellung 0;
BA_ "Fehlerwert" SG_ 1646 KL_Heizkreisventilstellung 3;
BA_ "GenSigSendType" SG_ 1646 KL_HYB_ASV_hinten_schliessen_Anf 3;
BA_ "GenSigSwitchedByIgnition" SG_ 1646 KL_HYB_ASV_hinten_schliessen_Anf 0;
BA_ "GenSigSendType" SG_ 1646 KL_HYB_ASV_vorne_schliessen_Anf 3;
BA_ "GenSigSwitchedByIgnition" SG_ 1646 KL_HYB_ASV_vorne_schliessen_Anf 0;
BA_ "GenSigSendType" SG_ 1646 KL_I_Geblaese_Fond 3;
BA_ "GenSigSwitchedByIgnition" SG_ 1646 KL_I_Geblaese_Fond 0;
BA_ "Fehlerwert" SG_ 1646 KL_I_Geblaese_Fond 255;
BA_ "GenSigSendType" SG_ 1646 KL_Innen_Temp 0;
BA_ "GenSigStartValue" SG_ 1646 KL_Innen_Temp 254;
BA_ "GenSigSwitchedByIgnition" SG_ 1646 KL_Innen_Temp 0;
BA_ "Fehlerwert" SG_ 1646 KL_Innen_Temp 255;
BA_ "GenSigSendType" SG_ 1646 KL_Kompressorkupplung 3;
BA_ "GenSigSwitchedByIgnition" SG_ 1646 KL_Kompressorkupplung 0;
BA_ "GenSigSendType" SG_ 1646 KL_Magnetventil 3;
BA_ "GenSigSwitchedByIgnition" SG_ 1646 KL_Magnetventil 0;
BA_ "GenSigSendType" SG_ 1646 KL_Restwaerme_aktiv 3;
BA_ "GenSigSwitchedByIgnition" SG_ 1646 KL_Restwaerme_aktiv 0;
BA_ "GenSigSendType" SG_ 1646 KL_SIH_LEH_Verteilung_VL 3;
BA_ "GenSigSwitchedByIgnition" SG_ 1646 KL_SIH_LEH_Verteilung_VL 0;
BA_ "GenSigSendType" SG_ 1646 KL_SIH_LEH_Verteilung_VR 3;
BA_ "GenSigSwitchedByIgnition" SG_ 1646 KL_SIH_LEH_Verteilung_VR 0;
BA_ "GenSigSendType" SG_ 1646 KL_SIH_LEL_Verteilung_VL 3;
BA_ "GenSigSwitchedByIgnition" SG_ 1646 KL_SIH_LEL_Verteilung_VL 0;
BA_ "GenSigSendType" SG_ 1646 KL_SIH_LEL_Verteilung_VR 3;
BA_ "GenSigSwitchedByIgnition" SG_ 1646 KL_SIH_LEL_Verteilung_VR 0;
BA_ "GenSigSendType" SG_ 1646 KL_Solarluefter_aktiv 3;
BA_ "GenSigSwitchedByIgnition" SG_ 1646 KL_Solarluefter_aktiv 0;
BA_ "GenSigSendType" SG_ 1646 KL_Status_Beduftung 3;
BA_ "GenSigSwitchedByIgnition" SG_ 1646 KL_Status_Beduftung 0;
BA_ "GenSigSendType" SG_ 1646 KL_Status_Ionisator_Front 3;
BA_ "GenSigSwitchedByIgnition" SG_ 1646 KL_Status_Ionisator_Front 0;
BA_ "GenSigSendType" SG_ 1646 KL_STH_aktiv 3;
BA_ "GenSigSwitchedByIgnition" SG_ 1646 KL_STH_aktiv 0;
BA_ "GenSigSendType" SG_ 1646 KL_STH_Ansteuerung 3;
BA_ "GenSigSwitchedByIgnition" SG_ 1646 KL_STH_Ansteuerung 0;
BA_ "GenSigSendType" SG_ 1646 KL_STH_Betriebsdauer 3;
BA_ "GenSigSwitchedByIgnition" SG_ 1646 KL_STH_Betriebsdauer 0;
BA_ "GenSigSendType" SG_ 1646 KL_STH_Timer_Status 3;
BA_ "GenSigSwitchedByIgnition" SG_ 1646 KL_STH_Timer_Status 0;
BA_ "GenSigSendType" SG_ 1646 KL_STL_aktiv 3;
BA_ "GenSigSwitchedByIgnition" SG_ 1646 KL_STL_aktiv 0;
BA_ "GenSigSendType" SG_ 1646 KL_Umluft_Taste 3;
BA_ "GenSigSwitchedByIgnition" SG_ 1646 KL_Umluft_Taste 0;
BA_ "GenSigSendType" SG_ 1646 KL_WaPu 3;
BA_ "GenSigSwitchedByIgnition" SG_ 1646 KL_WaPu 0;
BA_ "GenSigSendType" SG_ 1649 KL_Betriebsmodus_FH 3;
BA_ "GenSigSwitchedByIgnition" SG_ 1649 KL_Betriebsmodus_FH 0;
BA_ "GenSigSendType" SG_ 1649 KL_Stopp_Wiederstart_Anz_01 3;
BA_ "GenSigSwitchedByIgnition" SG_ 1649 KL_Stopp_Wiederstart_Anz_01 0;
BA_ "GenSigSendType" SG_ 1649 KL_Stopp_Wiederstart_Anz_02 3;
BA_ "GenSigSwitchedByIgnition" SG_ 1649 KL_Stopp_Wiederstart_Anz_02 0;
BA_ "GenSigSendType" SG_ 1649 KL_Stopp_Wiederstart_Anz_03 3;
BA_ "GenSigSwitchedByIgnition" SG_ 1649 KL_Stopp_Wiederstart_Anz_03 0;
BA_ "GenSigSendType" SG_ 1649 KL_Stopp_Wiederstart_Anz_04 3;
BA_ "GenSigSwitchedByIgnition" SG_ 1649 KL_Stopp_Wiederstart_Anz_04 0;
BA_ "GenSigSendType" SG_ 1649 KL_Stopp_Wiederstart_Anz_05 3;
BA_ "GenSigSwitchedByIgnition" SG_ 1649 KL_Stopp_Wiederstart_Anz_05 0;
BA_ "GenSigSendType" SG_ 1649 KL_Stopp_Wiederstart_Anz_06 3;
BA_ "GenSigSwitchedByIgnition" SG_ 1649 KL_Stopp_Wiederstart_Anz_06 0;
BA_ "GenSigSendType" SG_ 1649 KL_Stopp_Wiederstart_Anz_07 3;
BA_ "GenSigSwitchedByIgnition" SG_ 1649 KL_Stopp_Wiederstart_Anz_07 0;
BA_ "GenSigSendType" SG_ 1649 KL_Stopp_Wiederstart_Anz_08 3;
BA_ "GenSigSwitchedByIgnition" SG_ 1649 KL_Stopp_Wiederstart_Anz_08 0;
BA_ "GenSigSendType" SG_ 1649 KL_Stopp_Wiederstart_Anz_09 3;
BA_ "GenSigSwitchedByIgnition" SG_ 1649 KL_Stopp_Wiederstart_Anz_09 0;
BA_ "GenSigSendType" SG_ 1649 KL_Stopp_Wiederstart_Anz_Std1 3;
BA_ "GenSigSwitchedByIgnition" SG_ 1649 KL_Stopp_Wiederstart_Anz_Std1 0;
BA_ "GenSigSendType" SG_ 1649 KL_Stopp_Wiederstart_Anz_Std2 3;
BA_ "GenSigSwitchedByIgnition" SG_ 1649 KL_Stopp_Wiederstart_Anz_Std2 0;
BA_ "GenSigSendType" SG_ 1649 KL_ZZ_Betriebsmodus 3;
BA_ "GenSigSwitchedByIgnition" SG_ 1649 KL_ZZ_Betriebsmodus 0;
BA_ "GenSigSendType" SG_ 1649 KL_ZZ_Minute 3;
BA_ "GenSigSwitchedByIgnition" SG_ 1649 KL_ZZ_Minute 0;
BA_ "GenSigSendType" SG_ 1649 KL_ZZ_Monat 3;
BA_ "GenSigSwitchedByIgnition" SG_ 1649 KL_ZZ_Monat 0;
BA_ "GenSigSendType" SG_ 1649 KL_ZZ_Status_Timer 3;
BA_ "GenSigSwitchedByIgnition" SG_ 1649 KL_ZZ_Status_Timer 0;
BA_ "GenSigSendType" SG_ 1649 KL_ZZ_Stunde 3;
BA_ "GenSigSwitchedByIgnition" SG_ 1649 KL_ZZ_Stunde 0;
BA_ "GenSigSendType" SG_ 1649 KL_ZZ_Tag 3;
BA_ "GenSigSwitchedByIgnition" SG_ 1649 KL_ZZ_Tag 0;
BA_ "GenSigSendType" SG_ 949 KL_AC_Schalter 0;
BA_ "GenSigSwitchedByIgnition" SG_ 949 KL_AC_Schalter 0;
BA_ "GenSigSendType" SG_ 949 KL_Anf_KL 0;
BA_ "GenSigSwitchedByIgnition" SG_ 949 KL_Anf_KL 0;
BA_ "Fehlerwert" SG_ 949 KL_Anf_KL 255;
BA_ "GenSigSendType" SG_ 949 KL_Ausstattung_Klima 0;
BA_ "GenSigSwitchedByIgnition" SG_ 949 KL_Ausstattung_Klima 0;
BA_ "GenSigSendType" SG_ 949 KL_Charisma_FahrPr 0;
BA_ "GenSigSwitchedByIgnition" SG_ 949 KL_Charisma_FahrPr 0;
BA_ "GenSigSendType" SG_ 949 KL_Charisma_Status 0;
BA_ "GenSigSwitchedByIgnition" SG_ 949 KL_Charisma_Status 0;
BA_ "GenSigSendType" SG_ 949 KL_Drehz_Anh 0;
BA_ "GenSigSwitchedByIgnition" SG_ 949 KL_Drehz_Anh 0;
BA_ "GenSigSendType" SG_ 949 KL_el_Zuheizer_Stufe 0;
BA_ "GenSigSwitchedByIgnition" SG_ 949 KL_el_Zuheizer_Stufe 0;
BA_ "GenSigSendType" SG_ 949 KL_Freilauf_Info 0;
BA_ "GenSigSwitchedByIgnition" SG_ 949 KL_Freilauf_Info 0;
BA_ "GenSigSendType" SG_ 949 KL_Komp_Moment_alt 0;
BA_ "GenSigFuncType" SG_ 949 KL_Komp_Moment_alt 5;
BA_ "GenSigSwitchedByIgnition" SG_ 949 KL_Komp_Moment_alt 0;
BA_ "GenSigSendType" SG_ 949 KL_Kompressorkupplung_linear 0;
BA_ "GenSigStartValue" SG_ 949 KL_Kompressorkupplung_linear 254;
BA_ "GenSigSwitchedByIgnition" SG_ 949 KL_Kompressorkupplung_linear 0;
BA_ "GenSigSendType" SG_ 949 KL_Last_Kompr 0;
BA_ "GenSigSwitchedByIgnition" SG_ 949 KL_Last_Kompr 0;
BA_ "Fehlerwert" SG_ 949 KL_Last_Kompr 255;
BA_ "GenSigSendType" SG_ 949 KL_nachtr_Stopp_Anf 0;
BA_ "GenSigSwitchedByIgnition" SG_ 949 KL_nachtr_Stopp_Anf 0;
BA_ "GenSigSendType" SG_ 949 KL_Spannungs_Anf 0;
BA_ "GenSigSwitchedByIgnition" SG_ 949 KL_Spannungs_Anf 0;
BA_ "GenSigSendType" SG_ 949 KL_StartStopp_Info 0;
BA_ "GenSigSwitchedByIgnition" SG_ 949 KL_StartStopp_Info 0;
BA_ "GenSigSendType" SG_ 949 KL_T_Charge 0;
BA_ "GenSigSwitchedByIgnition" SG_ 949 KL_T_Charge 0;
BA_ "GenSigSendType" SG_ 949 KL_Thermomanagement 0;
BA_ "GenSigSwitchedByIgnition" SG_ 949 KL_Thermomanagement 0;
BA_ "GenSigSendType" SG_ 949 KL_Variante_Standheizung 0;
BA_ "GenSigSwitchedByIgnition" SG_ 949 KL_Variante_Standheizung 0;
BA_ "GenSigSendType" SG_ 949 KL_Vorwarn_Komp_ein 0;
BA_ "GenSigSwitchedByIgnition" SG_ 949 KL_Vorwarn_Komp_ein 0;
BA_ "GenSigSendType" SG_ 949 KL_Vorwarn_Zuheizer_ein 0;
BA_ "GenSigSwitchedByIgnition" SG_ 949 KL_Vorwarn_Zuheizer_ein 0;
BA_ "GenSigSendType" SG_ 949 KL_Zustand 0;
BA_ "GenSigSwitchedByIgnition" SG_ 949 KL_Zustand 0;
BA_ "GenSigActiveRepetitions" SG_ 1640 FSH_Taster 5;
BA_ "GenSigSendType" SG_ 1640 FSH_Taster 4;
BA_ "GenSigSwitchedByIgnition" SG_ 1640 FSH_Taster 0;
BA_ "GenSigActiveRepetitions" SG_ 1640 HSH_Taster 5;
BA_ "GenSigSendType" SG_ 1640 HSH_Taster 4;
BA_ "GenSigSwitchedByIgnition" SG_ 1640 HSH_Taster 0;
BA_ "GenSigSendType" SG_ 1640 KL_Beschlagsgefahr 3;
BA_ "GenSigSwitchedByIgnition" SG_ 1640 KL_Beschlagsgefahr 0;
BA_ "GenSigSendType" SG_ 1640 KL_Geblspng_Fond_Soll 0;
BA_ "GenSigSwitchedByIgnition" SG_ 1640 KL_Geblspng_Fond_Soll 0;
BA_ "Fehlerwert" SG_ 1640 KL_Geblspng_Fond_Soll 255;
BA_ "GenSigSendType" SG_ 1640 KL_Geblspng_Soll 0;
BA_ "GenSigSwitchedByIgnition" SG_ 1640 KL_Geblspng_Soll 0;
BA_ "Fehlerwert" SG_ 1640 KL_Geblspng_Soll 255;
BA_ "GenSigSendType" SG_ 1640 KL_I_Geblaese 0;
BA_ "GenSigSwitchedByIgnition" SG_ 1640 KL_I_Geblaese 0;
BA_ "Fehlerwert" SG_ 1640 KL_I_Geblaese 255;
BA_ "GenSigSendType" SG_ 1640 KL_Kompressorstrom_soll 0;
BA_ "GenSigStartValue" SG_ 1640 KL_Kompressorstrom_soll 1022;
BA_ "GenSigSwitchedByIgnition" SG_ 1640 KL_Kompressorstrom_soll 0;
BA_ "Fehlerwert" SG_ 1640 KL_Kompressorstrom_soll 1023;
BA_ "GenSigSendType" SG_ 1640 KL_LRH_Stufe 0;
BA_ "GenSigStartValue" SG_ 1640 KL_LRH_Stufe 1;
BA_ "GenSigSwitchedByIgnition" SG_ 1640 KL_LRH_Stufe 0;
BA_ "GenSigActiveRepetitions" SG_ 1640 KL_LRH_Taster 5;
BA_ "GenSigSendType" SG_ 1640 KL_LRH_Taster 4;
BA_ "GenSigSwitchedByIgnition" SG_ 1640 KL_LRH_Taster 0;
BA_ "GenSigSendType" SG_ 1640 KL_PTC_Verbauinfo 0;
BA_ "GenSigSwitchedByIgnition" SG_ 1640 KL_PTC_Verbauinfo 0;
BA_ "GenSigSendType" SG_ 1640 KL_SIH_Soll_li 3;
BA_ "GenSigSwitchedByIgnition" SG_ 1640 KL_SIH_Soll_li 0;
BA_ "GenSigSendType" SG_ 1640 KL_SIH_Soll_re 3;
BA_ "GenSigSwitchedByIgnition" SG_ 1640 KL_SIH_Soll_re 0;
